VERSION ""

NS_ :

BS_:
BU_: IAP ODS _4WD BCM HUD DATC MDPS AAF_Tester AEMC SMK _4WD EPB CUBIS MTS TMU EVP CGW TPMS LPI DI_BOX SPAS EMS LCA TCU IBOX FATC AFLS FPCM SCC AHLS AVM ABS SNV OPI PGS SAS AAF Dummy LDWS_LKAS LVR ESC PSB CLU ECS ACU REA
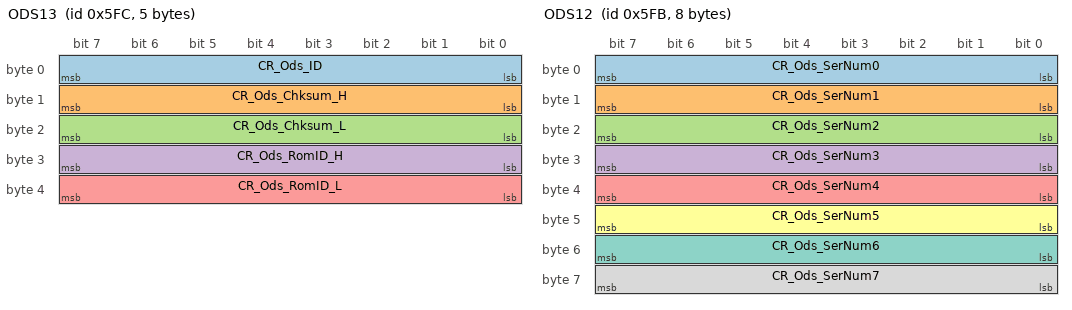
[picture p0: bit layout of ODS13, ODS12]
BO_ 1532 ODS13: 5 ODS
	SG_ CR_Ods_ID : 0|8@1+ (1.0,0.0) [0.0|255.0] ""  ACU
	SG_ CR_Ods_Chksum_H : 8|8@1+ (1.0,0.0) [0.0|255.0] ""  Dummy
	SG_ CR_Ods_Chksum_L : 16|8@1+ (1.0,0.0) [0.0|255.0] ""  Dummy
	SG_ CR_Ods_RomID_H : 24|8@1+ (1.0,0.0) [0.0|255.0] ""  Dummy
	SG_ CR_Ods_RomID_L : 32|8@1+ (1.0,0.0) [0.0|255.0] ""  Dummy

BO_ 1531 ODS12: 8 ODS
	SG_ CR_Ods_SerNum0 : 0|8@1+ (1.0,0.0) [0.0|255.0] ""  ACU
	SG_ CR_Ods_SerNum1 : 8|8@1+ (1.0,0.0) [0.0|255.0] ""  ACU
	SG_ CR_Ods_SerNum2 : 16|8@1+ (1.0,0.0) [0.0|255.0] ""  ACU
	SG_ CR_Ods_SerNum3 : 24|8@1+ (1.0,0.0) [0.0|255.0] ""  ACU
	SG_ CR_Ods_SerNum4 : 32|8@1+ (1.0,0.0) [0.0|255.0] ""  ACU
	SG_ CR_Ods_SerNum5 : 40|8@1+ (1.0,0.0) [0.0|255.0] ""  ACU
	SG_ CR_Ods_SerNum6 : 48|8@1+ (1.0,0.0) [0.0|255.0] ""  ACU
	SG_ CR_Ods_SerNum7 : 56|8@1+ (1.0,0.0) [0.0|255.0] ""  ACU

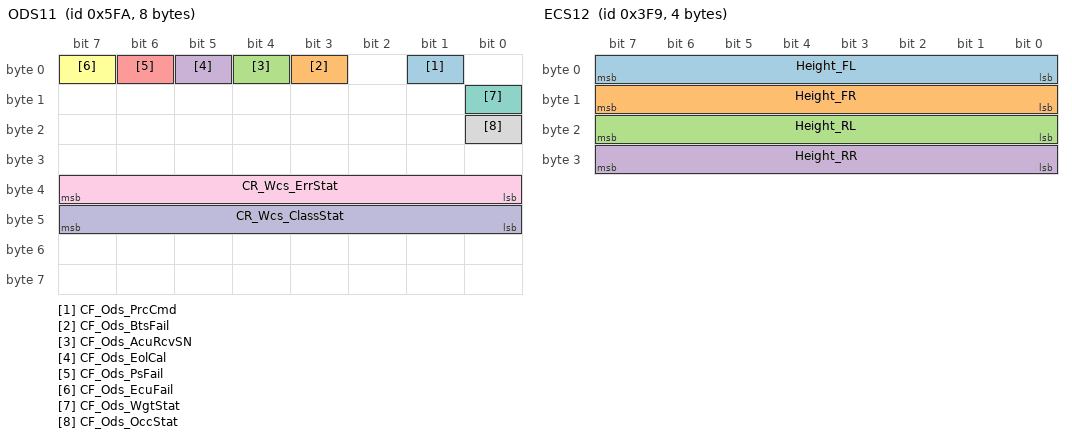
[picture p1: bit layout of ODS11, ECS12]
BO_ 1530 ODS11: 8 ODS
	SG_ CF_Ods_PrcCmd : 1|1@1+ (1.0,0.0) [0.0|1.0] ""  Dummy
	SG_ CF_Ods_BtsFail : 3|1@1+ (1.0,0.0) [0.0|1.0] ""  Dummy
	SG_ CF_Ods_AcuRcvSN : 4|1@1+ (1.0,0.0) [0.0|1.0] ""  ACU
	SG_ CF_Ods_EolCal : 5|1@1+ (1.0,0.0) [0.0|1.0] ""  ACU
	SG_ CF_Ods_PsFail : 6|1@1+ (1.0,0.0) [0.0|1.0] ""  ACU
	SG_ CF_Ods_EcuFail : 7|1@1+ (1.0,0.0) [0.0|1.0] ""  ACU
	SG_ CF_Ods_WgtStat : 8|1@1+ (1.0,0.0) [0.0|1.0] ""  ACU
	SG_ CF_Ods_OccStat : 16|1@1+ (1.0,0.0) [0.0|1.0] ""  ACU
	SG_ CR_Wcs_ErrStat : 32|8@1+ (1.0,0.0) [0.0|63.0] ""  ACU
	SG_ CR_Wcs_ClassStat : 40|8@1+ (1.0,0.0) [0.0|4.0] ""  ACU,BCM

BO_ 1017 ECS12: 4 ECS
	SG_ Height_FL : 0|8@1+ (1.0,-128.0) [-128.0|127.0] "mm"  AFLS
	SG_ Height_FR : 8|8@1+ (1.0,-128.0) [-128.0|127.0] "mm"  AFLS
	SG_ Height_RL : 16|8@1+ (1.0,-128.0) [-128.0|127.0] "mm"  AFLS
	SG_ Height_RR : 24|8@1+ (1.0,-128.0) [-128.0|127.0] "mm"  AFLS

BO_ 1268 SPAS12: 8 SPAS
	SG_ CF_Spas_HMI_Stat : 0|8@1+ (1.0,0.0) [0.0|255.0] ""  CLU
	SG_ CF_Spas_Disp : 8|2@1+ (1.0,0.0) [0.0|3.0] ""  CLU,EMS
	SG_ CF_Spas_FIL_Ind : 10|3@1+ (1.0,0.0) [0.0|7.0] ""  AVM,CLU
	SG_ CF_Spas_FIR_Ind : 13|3@1+ (1.0,0.0) [0.0|7.0] ""  AVM,CLU
	SG_ CF_Spas_FOL_Ind : 16|3@1+ (1.0,0.0) [0.0|7.0] ""  AVM,CLU
	SG_ CF_Spas_FOR_Ind : 19|3@1+ (1.0,0.0) [0.0|7.0] ""  AVM,CLU
	SG_ CF_Spas_VolDown : 22|2@1+ (1.0,0.0) [0.0|3.0] ""  CLU
	SG_ CF_Spas_RIL_Ind : 24|3@1+ (1.0,0.0) [0.0|7.0] ""  AVM,CLU
	SG_ CF_Spas_RIR_Ind : 27|3@1+ (1.0,0.0) [0.0|7.0] ""  AVM,CLU
	SG_ CF_Spas_FLS_Alarm : 30|2@1+ (1.0,0.0) [0.0|3.0] ""  CLU
	SG_ CF_Spas_ROL_Ind : 32|3@1+ (1.0,0.0) [0.0|7.0] ""  AVM,CLU
	SG_ CF_Spas_ROR_Ind : 35|3@1+ (1.0,0.0) [0.0|7.0] ""  AVM,CLU
	SG_ CF_Spas_FCS_Alarm : 38|2@1+ (1.0,0.0) [0.0|3.0] ""  CLU
	SG_ CF_Spas_FI_Ind : 40|3@1+ (1.0,0.0) [0.0|7.0] ""  AVM,CLU
	SG_ CF_Spas_RI_Ind : 43|3@1+ (1.0,0.0) [0.0|7.0] ""  AVM,CLU
	SG_ CF_Spas_FRS_Alarm : 46|2@1+ (1.0,0.0) [0.0|3.0] ""  CLU
	SG_ CF_Spas_FR_Alarm : 48|2@1+ (1.0,0.0) [0.0|3.0] ""  BCM,CLU
	SG_ CF_Spas_RR_Alarm : 50|2@1+ (1.0,0.0) [0.0|3.0] ""  BCM,CLU
	SG_ CF_Spas_BEEP_Alarm : 52|4@1+ (1.0,0.0) [0.0|15.0] ""  BCM,CLU
	SG_ CF_Spas_StatAlarm : 56|1@1+ (1.0,0.0) [0.0|1.0] ""  CLU
	SG_ CF_Spas_RLS_Alarm : 57|2@1+ (1.0,0.0) [0.0|3.0] ""  CLU
	SG_ CF_Spas_RCS_Alarm : 59|2@1+ (1.0,0.0) [0.0|3.0] ""  CLU
	SG_ CF_Spas_RRS_Alarm : 61|2@1+ (1.0,0.0) [0.0|3.0] ""  CLU

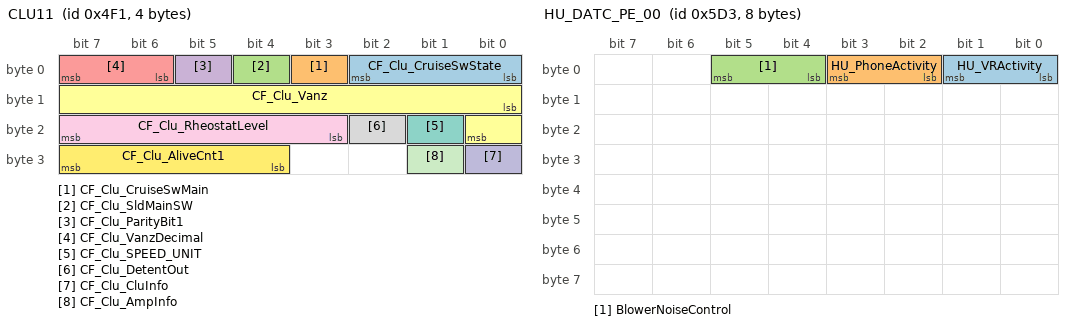
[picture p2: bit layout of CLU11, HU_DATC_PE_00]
BO_ 1265 CLU11: 4 CLU
	SG_ CF_Clu_CruiseSwState : 0|3@1+ (1.0,0.0) [0.0|7.0] ""  EMS,LDWS_LKAS,SCC
	SG_ CF_Clu_CruiseSwMain : 3|1@1+ (1.0,0.0) [0.0|1.0] ""  EMS,LDWS_LKAS,SCC
	SG_ CF_Clu_SldMainSW : 4|1@1+ (1.0,0.0) [0.0|1.0] ""  EMS
	SG_ CF_Clu_ParityBit1 : 5|1@1+ (1.0,0.0) [0.0|1.0] "pulse count"  EMS
	SG_ CF_Clu_VanzDecimal : 6|2@1+ (0.125,0.0) [0.0|0.375] ""  EMS
	SG_ CF_Clu_Vanz : 8|9@1+ (0.5,0.0) [0.0|255.5] "km/h or MPH"  BCM,CUBIS,EMS,IBOX,LDWS_LKAS,MDPS,SCC
	SG_ CF_Clu_SPEED_UNIT : 17|1@1+ (1.0,0.0) [0.0|1.0] ""  BCM,CUBIS,EMS,IBOX,LDWS_LKAS,MDPS,SCC
	SG_ CF_Clu_DetentOut : 18|1@1+ (1.0,0.0) [0.0|1.0] ""  AVM,BCM,LCA,PGS,SPAS
	SG_ CF_Clu_RheostatLevel : 19|5@1+ (1.0,0.0) [0.0|31.0] ""  AVM,BCM,LCA,PGS,SPAS
	SG_ CF_Clu_CluInfo : 24|1@1+ (1.0,0.0) [0.0|1.0] ""  BCM
	SG_ CF_Clu_AmpInfo : 25|1@1+ (1.0,0.0) [0.0|1.0] ""  BCM
	SG_ CF_Clu_AliveCnt1 : 28|4@1+ (1.0,0.0) [0.0|15.0] ""  AHLS,EMS,EPB,LDWS_LKAS,MDPS,SCC

BO_ 1492 TMU_GW_PE_01: 8 CLU
	SG_ TMU_IVRActivity : 0|2@1+ (1.0,0.0) [0.0|3.0] ""  DATC
	SG_ TMU_PhoneActivity : 2|2@1+ (1.0,0.0) [0.0|3.0] ""  DATC

BO_ 1491 HU_DATC_PE_00: 8 CLU
	SG_ HU_VRActivity : 0|2@1+ (1.0,0.0) [0.0|3.0] ""  DATC
	SG_ HU_PhoneActivity : 2|2@1+ (1.0,0.0) [0.0|3.0] ""  DATC
	SG_ BlowerNoiseControl : 4|2@1+ (1.0,0.0) [0.0|3.0] ""  DATC

BO_ 1490 HU_DATC_E_02: 8 CLU
	SG_ HU_DATC_RearOnOffSet : 6|2@1+ (1.0,0.0) [0.0|3.0] ""  DATC
	SG_ HU_DATC_ADSOnOffSet : 8|2@1+ (1.0,0.0) [0.0|3.0] ""  DATC

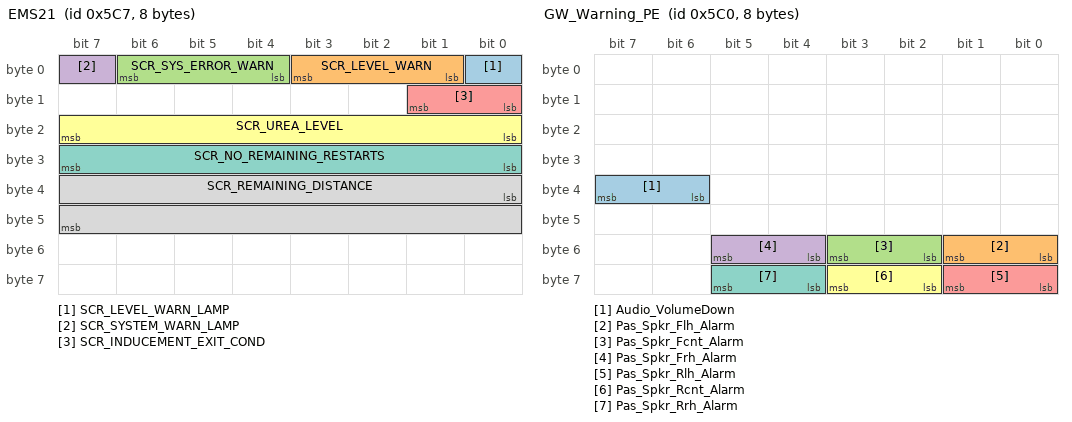
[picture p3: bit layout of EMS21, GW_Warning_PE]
BO_ 1479 EMS21: 8 EMS
	SG_ SCR_LEVEL_WARN_LAMP : 0|1@1+ (1.0,0.0) [0.0|1.0] ""  CLU
	SG_ SCR_LEVEL_WARN : 1|3@1+ (1.0,0.0) [0.0|4.0] ""  CLU
	SG_ SCR_SYS_ERROR_WARN : 4|3@1+ (1.0,0.0) [0.0|7.0] ""  CLU
	SG_ SCR_SYSTEM_WARN_LAMP : 7|1@1+ (1.0,0.0) [0.0|1.0] ""  CLU
	SG_ SCR_INDUCEMENT_EXIT_COND : 8|2@1+ (1.0,0.0) [0.0|3.0] ""  CLU
	SG_ SCR_UREA_LEVEL : 16|8@1+ (0.5,0.0) [0.0|100.0] "%"  CLU
	SG_ SCR_NO_REMAINING_RESTARTS : 24|8@1+ (1.0,0.0) [0.0|255.0] ""  CLU
	SG_ SCR_REMAINING_DISTANCE : 32|16@1+ (1.0,0.0) [0.0|25000.0] "km"  CLU

BO_ 1472 GW_Warning_PE: 8 BCM
	SG_ Audio_VolumeDown : 38|2@1+ (1.0,0.0) [0.0|3.0] ""  CLU
	SG_ Pas_Spkr_Flh_Alarm : 48|2@1+ (1.0,0.0) [0.0|3.0] ""  CLU
	SG_ Pas_Spkr_Fcnt_Alarm : 50|2@1+ (1.0,0.0) [0.0|3.0] ""  CLU
	SG_ Pas_Spkr_Frh_Alarm : 52|2@1+ (1.0,0.0) [0.0|3.0] ""  CLU
	SG_ Pas_Spkr_Rlh_Alarm : 56|2@1+ (1.0,0.0) [0.0|3.0] ""  CLU,PGS
	SG_ Pas_Spkr_Rcnt_Alarm : 58|2@1+ (1.0,0.0) [0.0|3.0] ""  CLU
	SG_ Pas_Spkr_Rrh_Alarm : 60|2@1+ (1.0,0.0) [0.0|3.0] ""  CLU,PGS

BO_ 1984 CAL_SAS11: 2 ESC
	SG_ CCW : 0|4@1+ (1.0,0.0) [0.0|15.0] ""  SAS
	SG_ SAS_CID : 4|11@1+ (1.0,0.0) [0.0|2047.0] ""  SAS

BO_ 1456 CLU12: 4 CLU
	SG_ CF_Clu_Odometer : 0|24@1+ (0.1,0.0) [0.0|1677721.4] "km"  _4WD,AAF,BCM,CUBIS,EMS,EPB,IBOX,LDWS_LKAS,SCC,TPMS

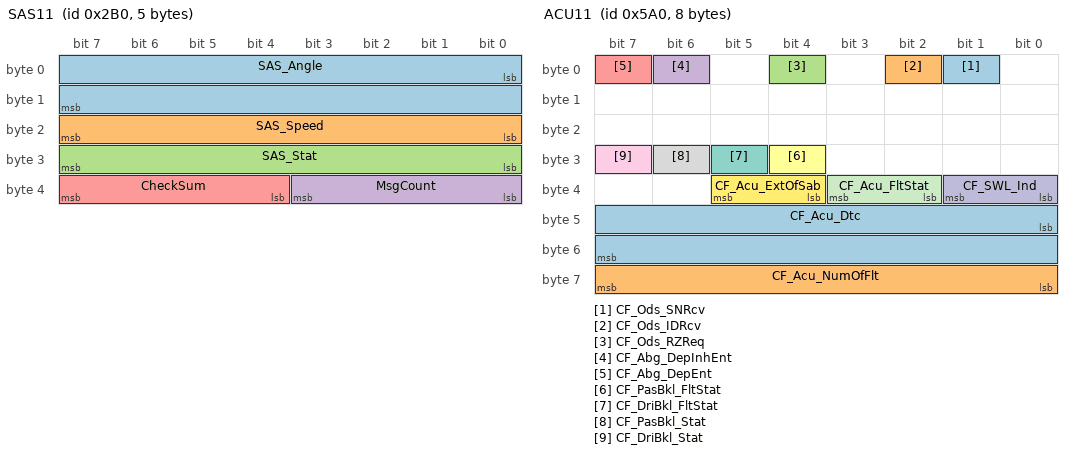
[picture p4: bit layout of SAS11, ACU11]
BO_ 688 SAS11: 5 MDPS
	SG_ SAS_Angle : 0|16@1+ (0.1,0.0) [-3276.8|3276.7] "Deg"  _4WD,ACU,AFLS,AVM,CLU,ECS,EMS,ESC,IBOX,LCA,LDWS_LKAS,PGS,PSB,SCC,SPAS,TCU,_4WD,ACU,AFLS,AVM,BCM,CLU,ECS,EMS,ESC,IBOX,LCA,LDWS_LKAS,PGS,PSB,SCC,SPAS,TCU
	SG_ SAS_Speed : 16|8@1+ (4.0,0.0) [0.0|1016.0] ""  AFLS,ECS,ESC,IBOX,LDWS_LKAS,SCC,SPAS,TCU,AFLS,ECS,ESC,IBOX,LDWS_LKAS,SCC,SPAS,TCU
	SG_ SAS_Stat : 24|8@1+ (1.0,0.0) [0.0|255.0] ""  ECS,ESC,IBOX,LDWS_LKAS,PSB,SCC,SPAS,TCU,ECS,ESC,IBOX,LDWS_LKAS,PSB,SCC,SPAS,TCU
	SG_ MsgCount : 32|4@1+ (1.0,0.0) [0.0|15.0] ""  ECS,ESC,IBOX,LDWS_LKAS,PSB,SCC,SPAS,ECS,ESC,IBOX,LDWS_LKAS,PSB,SCC,SPAS
	SG_ CheckSum : 36|4@1+ (1.0,0.0) [0.0|15.0] ""  ECS,EMS,ESC,IBOX,LDWS_LKAS,PSB,SCC,SPAS,ECS,EMS,ESC,IBOX,LDWS_LKAS,PSB,SCC,SPAS

BO_ 1441 ACU12: 8 ACU
	SG_ CR_Acu_SN : 0|64@1+ (1.0,0.0) [0.0|0.0] ""  ODS

BO_ 1440 ACU11: 8 ACU
	SG_ CF_Ods_SNRcv : 1|1@1+ (1.0,0.0) [0.0|1.0] ""  ODS
	SG_ CF_Ods_IDRcv : 2|1@1+ (1.0,0.0) [0.0|1.0] ""  ODS
	SG_ CF_Ods_RZReq : 4|1@1+ (1.0,0.0) [0.0|1.0] ""  ODS
	SG_ CF_Abg_DepInhEnt : 6|1@1+ (1.0,0.0) [0.0|1.0] ""  ODS
	SG_ CF_Abg_DepEnt : 7|1@1+ (1.0,0.0) [0.0|1.0] ""  ODS
	SG_ CF_PasBkl_FltStat : 28|1@1+ (1.0,0.0) [0.0|1.0] ""  ODS,PSB
	SG_ CF_DriBkl_FltStat : 29|1@1+ (1.0,0.0) [0.0|1.0] ""  ODS,PSB
	SG_ CF_PasBkl_Stat : 30|1@1+ (1.0,0.0) [0.0|1.0] ""  IBOX,ODS,PSB,TMU
	SG_ CF_DriBkl_Stat : 31|1@1+ (1.0,0.0) [0.0|1.0] ""  ODS,PSB
	SG_ CF_SWL_Ind : 32|2@1+ (1.0,0.0) [0.0|3.0] ""  CUBIS,IBOX
	SG_ CF_Acu_FltStat : 34|2@1+ (1.0,0.0) [0.0|3.0] ""  CUBIS,IBOX
	SG_ CF_Acu_ExtOfSab : 36|2@1+ (1.0,0.0) [0.0|3.0] ""  BCM,CLU,CUBIS,IBOX
	SG_ CF_Acu_Dtc : 40|16@1+ (1.0,0.0) [0.0|65535.0] ""  CUBIS,IBOX
	SG_ CF_Acu_NumOfFlt : 56|8@1+ (1.0,0.0) [0.0|255.0] ""  CUBIS,IBOX

BO_ 1437 AHLS11: 8 AHLS
	SG_ CF_Ahls_WarnLamp : 0|2@1+ (1.0,0.0) [0.0|3.0] ""  CLU
	SG_ CF_Ahls_WarnMsg : 2|2@1+ (1.0,0.0) [0.0|3.0] ""  CLU

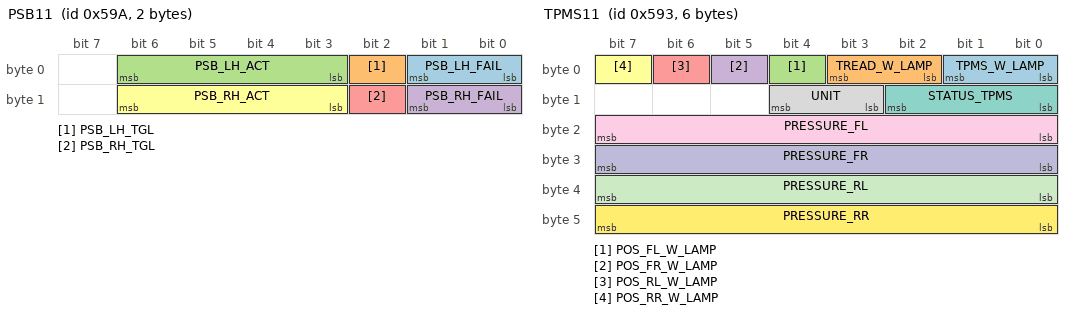
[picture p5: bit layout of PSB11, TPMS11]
BO_ 1434 PSB11: 2 PSB
	SG_ PSB_LH_FAIL : 0|2@1+ (1.0,0.0) [0.0|3.0] ""  CLU
	SG_ PSB_LH_TGL : 2|1@1+ (1.0,0.0) [0.0|1.0] ""  CLU
	SG_ PSB_LH_ACT : 3|4@1+ (1.0,0.0) [0.0|4.0] ""  Dummy
	SG_ PSB_RH_FAIL : 8|2@1+ (1.0,0.0) [0.0|3.0] ""  CLU
	SG_ PSB_RH_TGL : 10|1@1+ (1.0,0.0) [0.0|1.0] ""  CLU
	SG_ PSB_RH_ACT : 11|4@1+ (1.0,0.0) [0.0|4.0] ""  Dummy

BO_ 916 TCS13: 8 ESC
	SG_ aBasis : 0|11@1+ (0.01,-10.23) [-10.23|10.24] "m/s^2"  EMS,SCC
	SG_ BrakeLight : 11|1@1+ (1.0,0.0) [0.0|1.0] ""  CLU,EMS,SCC
	SG_ DCEnable : 12|1@1+ (1.0,0.0) [0.0|1.0] ""  EMS,SCC
	SG_ AliveCounterTCS : 13|3@1+ (1.0,0.0) [0.0|7.0] ""  EMS,SCC
	SG_ ACCReqLim : 22|2@1+ (1.0,0.0) [0.0|3.0] ""  EMS,SCC
	SG_ TQI_ACC : 24|8@1+ (0.390625,0.0) [0.0|99.609375] "%"  EMS
	SG_ ACCEL_REF_ACC : 32|11@1+ (0.01,-10.23) [-10.23|10.24] "m/s^2"  EMS,SCC
	SG_ ACCEnable : 43|2@1+ (1.0,0.0) [0.0|3.0] ""  EMS,SCC
	SG_ DriverOverride : 45|2@1+ (1.0,0.0) [0.0|3.0] ""  EMS,SCC
	SG_ StandStill : 47|1@1+ (1.0,0.0) [0.0|1.0] ""  EMS,SCC
	SG_ CheckSum_TCS3 : 48|4@1+ (1.0,0.0) [0.0|15.0] ""  EMS,SCC
	SG_ ACC_EQUIP : 52|1@1+ (1.0,0.0) [0.0|1.0] ""  EMS,SCC
	SG_ PBRAKE_ACT : 53|1@1+ (1.0,0.0) [0.0|1.0] ""  EMS,SCC
	SG_ ACC_REQ : 54|1@1+ (1.0,0.0) [0.0|1.0] ""  EMS
	SG_ DriverBraking : 55|1@1+ (1.0,0.0) [0.0|1.0] ""  EMS,SCC
	SG_ CF_VSM_Coded : 56|1@1+ (1.0,0.0) [0.0|1.0] ""  SCC
	SG_ CF_VSM_Avail : 57|2@1+ (1.0,0.0) [0.0|3.0] ""  CLU,SCC
	SG_ CF_VSM_Handshake : 59|1@1+ (1.0,0.0) [0.0|1.0] ""  SCC
	SG_ CF_DriBkeStat : 60|1@1+ (1.0,0.0) [0.0|1.0] ""  SCC
	SG_ CF_VSM_ConfSwi : 61|2@1+ (1.0,0.0) [0.0|3.0] ""  SCC
	SG_ AEB_EQUIP : 63|1@1+ (1.0,0.0) [0.0|1.0] ""  SCC

BO_ 1427 TPMS11: 6 BCM
	SG_ TPMS_W_LAMP : 0|2@1+ (1.0,0.0) [0.0|3.0] ""  CLU,CUBIS,HUD,IBOX,CLU,CUBIS,HUD,IBOX
	SG_ TREAD_W_LAMP : 2|2@1+ (1.0,0.0) [0.0|3.0] ""  CLU,CUBIS,HUD,IBOX,CLU,CUBIS,HUD,IBOX
	SG_ POS_FL_W_LAMP : 4|1@1+ (1.0,0.0) [0.0|1.0] ""  CLU,CUBIS,HUD,IBOX
	SG_ POS_FR_W_LAMP : 5|1@1+ (1.0,0.0) [0.0|1.0] ""  CLU,CUBIS,HUD,IBOX
	SG_ POS_RL_W_LAMP : 6|1@1+ (1.0,0.0) [0.0|1.0] ""  CLU,CUBIS,HUD,IBOX
	SG_ POS_RR_W_LAMP : 7|1@1+ (1.0,0.0) [0.0|1.0] ""  CLU,CUBIS,HUD,IBOX
	SG_ STATUS_TPMS : 8|3@1+ (1.0,0.0) [0.0|0.0] ""  CLU
	SG_ UNIT : 11|2@1+ (1.0,0.0) [0.0|3.0] ""  CLU
	SG_ PRESSURE_FL : 16|8@1+ (1.0,0.0) [0.0|255.0] ""  CLU
	SG_ PRESSURE_FR : 24|8@1+ (1.0,0.0) [0.0|255.0] ""  CLU
	SG_ PRESSURE_RL : 32|8@1+ (1.0,0.0) [0.0|255.0] ""  CLU
	SG_ PRESSURE_RR : 40|8@1+ (1.0,0.0) [0.0|255.0] ""  CLU

BO_ 915 TCS12: 4 ESC
	SG_ SA_COUNT : 0|16@1+ (2.0,-32768.0) [-32768.0|98302.0] "¢ª"  _4WD,ACU,MDPS
	SG_ SA_Z_COUNT : 16|15@1+ (2.0,-32768.0) [-32768.0|32766.0] "¢ª"  _4WD,ACU,MDPS
	SG_ SA_Z_FLAG : 31|1@1+ (1.0,0.0) [0.0|1.0] ""  _4WD,ACU,MDPS

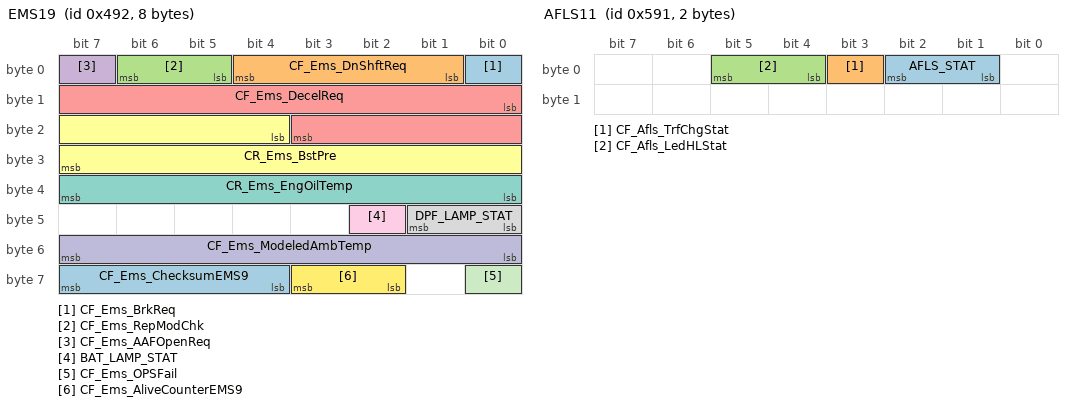
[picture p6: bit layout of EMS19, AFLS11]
BO_ 1170 EMS19: 8 EMS
	SG_ CF_Ems_BrkReq : 0|1@1+ (1.0,0.0) [0.0|1.0] ""  ESC,IBOX,TCU
	SG_ CF_Ems_DnShftReq : 1|4@1+ (1.0,0.0) [0.0|14.0] ""  IBOX,TCU
	SG_ CF_Ems_RepModChk : 5|2@1+ (1.0,0.0) [0.0|3.0] ""  IBOX
	SG_ CF_Ems_AAFOpenReq : 7|1@1+ (1.0,0.0) [0.0|1.0] ""  AAF,IBOX
	SG_ CF_Ems_DecelReq : 8|12@1+ (0.0010,-4.094) [-4.094|0.0] "m/s^2"  ESC,IBOX,TCU
	SG_ CR_Ems_BstPre : 20|12@1+ (1.322,0.0) [0.0|4094.0] "hPa"  CLU,IBOX
	SG_ CR_Ems_EngOilTemp : 32|8@1+ (0.75,-40.0) [0.0|254.0] "¡É"  CLU,IBOX
	SG_ DPF_LAMP_STAT : 40|2@1+ (1.0,0.0) [0.0|3.0] ""  CLU,IBOX
	SG_ BAT_LAMP_STAT : 42|1@1+ (1.0,0.0) [0.0|1.0] ""  CLU,IBOX
	SG_ CF_Ems_ModeledAmbTemp : 48|8@1+ (0.5,-41.0) [-41.0|85.5] "¡É"  AAF,IBOX
	SG_ CF_Ems_OPSFail : 56|1@1+ (1.0,0.0) [0.0|1.0] ""  CLU,IBOX
	SG_ CF_Ems_AliveCounterEMS9 : 58|2@1+ (1.0,0.0) [0.0|3.0] ""  AAF,ABS,CUBIS,ECS,EPB,IBOX,MDPS,REA,SCC,SMK,TCU
	SG_ CF_Ems_ChecksumEMS9 : 60|4@1+ (1.0,0.0) [0.0|15.0] ""  AAF,ABS,CUBIS,ECS,EPB,IBOX,MDPS,REA,SCC,SMK,TCU

BO_ 1425 AFLS11: 2 AFLS
	SG_ AFLS_STAT : 1|2@1+ (1.0,0.0) [0.0|3.0] ""  CLU
	SG_ CF_Afls_TrfChgStat : 3|1@1+ (1.0,0.0) [0.0|1.0] ""  CLU
	SG_ CF_Afls_LedHLStat : 4|2@1+ (1.0,0.0) [0.0|3.0] ""  CLU

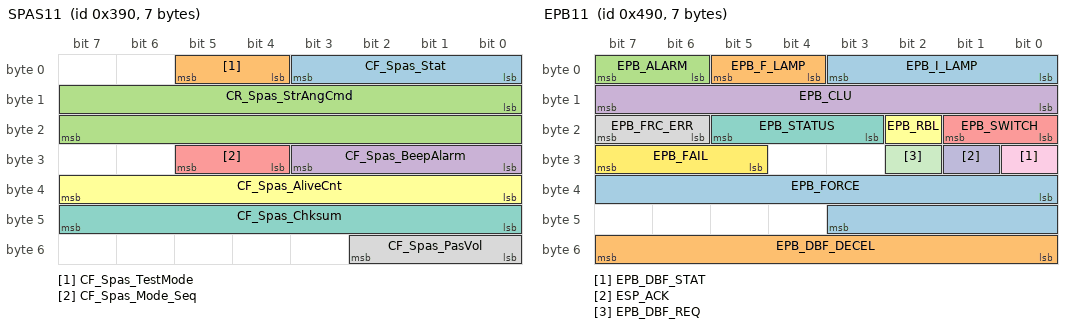
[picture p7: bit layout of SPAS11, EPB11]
BO_ 912 SPAS11: 7 SPAS
	SG_ CF_Spas_Stat : 0|4@1+ (1.0,0.0) [0.0|15.0] ""  ESC,MDPS
	SG_ CF_Spas_TestMode : 4|2@1+ (1.0,0.0) [0.0|3.0] ""  MDPS
	SG_ CR_Spas_StrAngCmd : 8|16@1- (0.1,0.0) [-3276.8|3276.7] ""  MDPS
	SG_ CF_Spas_BeepAlarm : 24|4@1+ (1.0,0.0) [0.0|15.0] ""  CLU
	SG_ CF_Spas_Mode_Seq : 28|2@1+ (1.0,0.0) [0.0|3.0] ""  CLU
	SG_ CF_Spas_AliveCnt : 32|8@1+ (1.0,0.0) [0.0|255.0] ""  MDPS
	SG_ CF_Spas_Chksum : 40|8@1+ (1.0,0.0) [0.0|255.0] ""  MDPS
	SG_ CF_Spas_PasVol : 48|3@1+ (1.0,0.0) [0.0|7.0] ""  CGW,CLU

BO_ 1168 EPB11: 7 EPB
	SG_ EPB_I_LAMP : 0|4@1+ (1.0,0.0) [0.0|15.0] ""  BCM,CLU,CUBIS,ESC,IBOX
	SG_ EPB_F_LAMP : 4|2@1+ (1.0,0.0) [0.0|3.0] ""  CLU,CUBIS,ESC,IBOX
	SG_ EPB_ALARM : 6|2@1+ (1.0,0.0) [0.0|3.0] ""  CLU,ESC
	SG_ EPB_CLU : 8|8@1+ (1.0,0.0) [0.0|255.0] ""  CLU,ESC
	SG_ EPB_SWITCH : 16|2@1+ (1.0,0.0) [0.0|3.0] ""  ESC,SCC
	SG_ EPB_RBL : 18|1@1+ (1.0,0.0) [0.0|1.0] ""  EMS,ESC
	SG_ EPB_STATUS : 19|3@1+ (1.0,0.0) [0.0|7.0] ""  CLU,EMS,ESC,SCC,TCU
	SG_ EPB_FRC_ERR : 22|2@1+ (1.0,0.0) [0.0|3.0] ""  EMS,ESC,SCC,TCU
	SG_ EPB_DBF_STAT : 24|1@1+ (1.0,0.0) [0.0|1.0] ""  ESC
	SG_ ESP_ACK : 25|1@1+ (1.0,0.0) [0.0|1.0] ""  ESC
	SG_ EPB_DBF_REQ : 26|1@1+ (1.0,0.0) [0.0|1.0] ""  ESC
	SG_ EPB_FAIL : 29|3@1+ (1.0,0.0) [0.0|7.0] ""  ESC,SCC
	SG_ EPB_FORCE : 32|12@1+ (1.0,-1000.0) [-1000.0|3000.0] ""  ESC
	SG_ EPB_DBF_DECEL : 48|8@1+ (0.01,0.0) [0.0|2.54] "g"  ESC

BO_ 399 EMS_H12: 8 EMS
	SG_ R_TqAcnApvC : 0|8@1+ (0.2,0.0) [0.0|51.0] "Nm"  DATC,IBOX
	SG_ R_PAcnC : 8|8@1+ (125.0,0.0) [0.0|31875.0] "hPa"  DATC,IBOX
	SG_ TQI_B : 16|8@1+ (0.390625,0.0) [0.0|99.609375] "%"  ABS,ESC,IBOX
	SG_ SLD_VS : 24|8@1+ (1.0,0.0) [0.0|255.0] "km/h"  CLU,IBOX
	SG_ CF_CdaStat : 32|3@1+ (1.0,0.0) [0.0|7.0] ""  AEMC,IBOX,TCU
	SG_ CF_Ems_IsgStat : 35|3@1+ (1.0,0.0) [0.0|7.0] ""  ABS,BCM,CLU,DATC,EPB,ESC,IBOX,LDWS_LKAS,MDPS,SMK,TCU
	SG_ CF_Ems_OilChg : 38|1@1+ (1.0,0.0) [0.0|1.0] ""  CLU,IBOX
	SG_ CF_Ems_EtcLimpMod : 39|1@1+ (1.0,0.0) [0.0|1.0] ""  CLU,IBOX
	SG_ R_NEngIdlTgC : 40|8@1+ (10.0,0.0) [0.0|2550.0] "rpm"  DATC,IBOX,TCU
	SG_ CF_Ems_UpTarGr : 48|1@1+ (1.0,0.0) [0.0|1.0] ""  CLU,IBOX
	SG_ CF_Ems_DownTarGr : 49|1@1+ (1.0,0.0) [0.0|1.0] ""  CLU,IBOX
	SG_ CF_Ems_DesCurGr : 50|4@1+ (1.0,0.0) [0.0|15.0] ""  CLU,IBOX
	SG_ CF_Ems_SldAct : 54|1@1+ (1.0,0.0) [0.0|1.0] ""  CLU,IBOX
	SG_ CF_Ems_SldPosAct : 55|1@1+ (1.0,0.0) [0.0|1.0] ""  CLU,IBOX
	SG_ CF_Ems_HPresStat : 56|1@1+ (1.0,0.0) [0.0|1.0] ""  IBOX,TCU
	SG_ CF_Ems_IsgBuz : 57|1@1+ (1.0,0.0) [0.0|1.0] ""  CLU,IBOX
	SG_ CF_Ems_IdlStpFCO : 58|1@1+ (1.0,0.0) [0.0|1.0] ""  CLU,IBOX
	SG_ CF_Ems_FCopen : 59|1@1+ (1.0,0.0) [0.0|1.0] ""  CLU,IBOX
	SG_ CF_Ems_ActEcoAct : 60|1@1+ (1.0,0.0) [0.0|1.0] ""  CLU,IBOX,TCU
	SG_ CF_Ems_EngRunNorm : 61|1@1+ (1.0,0.0) [0.0|1.0] ""  ABS,ESC,IBOX,TCU
	SG_ CF_Ems_IsgStat2 : 62|2@1+ (2.0,0.0) [0.0|3.0] ""  CLU,IBOX,TCU

BO_ 1419 LCA11: 8 LCA
	SG_ CF_Lca_Stat : 0|4@1+ (1.0,0.0) [0.0|15.0] ""  BCM,CLU
	SG_ CF_Rcta_Stat : 4|4@1+ (1.0,0.0) [0.0|15.0] ""  BCM,CLU
	SG_ CF_Lca_IndLeft : 8|2@1+ (1.0,0.0) [0.0|3.0] ""  BCM,CLU
	SG_ CF_Rcw_Stat : 10|4@1+ (1.0,0.0) [0.0|15.0] ""  BCM,CLU
	SG_ CF_RCW_Warning : 14|2@1+ (1.0,0.0) [0.0|3.0] ""  BCM,CLU
	SG_ CF_Lca_IndRight : 16|2@1+ (1.0,0.0) [0.0|3.0] ""  BCM,CLU
	SG_ CF_Lca_SndWan_Stat : 18|2@1+ (1.0,0.0) [0.0|3.0] ""  BCM,CLU
	SG_ CF_FR_SndWan : 20|1@1+ (1.0,0.0) [0.0|1.0] ""  BCM,CLU
	SG_ CF_FL_SndWan : 21|1@1+ (1.0,0.0) [0.0|1.0] ""  BCM,CLU
	SG_ CF_RR_SndWan : 22|1@1+ (1.0,0.0) [0.0|1.0] ""  BCM,CLU
	SG_ CF_RL_SndWan : 23|1@1+ (1.0,0.0) [0.0|1.0] ""  BCM,CLU
	SG_ CF_Lca_IndBriLeft : 24|8@1+ (1.0,0.0) [0.0|255.0] ""  BCM,CLU
	SG_ CF_Lca_IndBriRight : 32|8@1+ (1.0,0.0) [0.0|255.0] ""  BCM,CLU
	SG_ CF_RCTA_IndBriLeft : 40|8@1+ (1.0,0.0) [0.0|255.0] ""  BCM,CLU
	SG_ CF_RCTA_IndBriRight : 48|8@1+ (1.0,0.0) [0.0|255.0] ""  BCM,CLU
	SG_ CF_RCTA_IndLeft : 56|2@1+ (1.0,0.0) [0.0|3.0] ""  BCM,CLU
	SG_ CF_RCTA_IndRight : 58|2@1+ (1.0,0.0) [0.0|3.0] ""  BCM,CLU
	SG_ CF_SndWarnForClu : 60|1@1+ (1.0,0.0) [0.0|1.0] ""  CLU

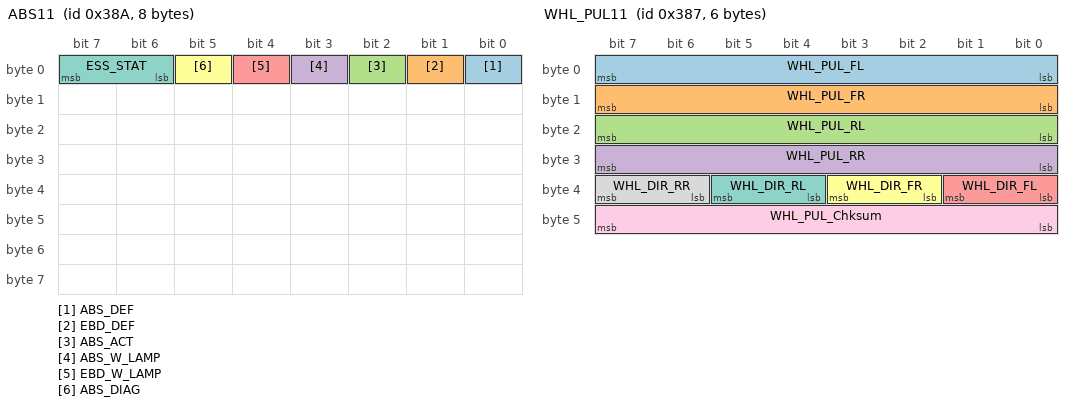
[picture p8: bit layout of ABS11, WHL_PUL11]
BO_ 906 ABS11: 8 ABS
	SG_ ABS_DEF : 0|1@1+ (1.0,0.0) [0.0|1.0] ""  _4WD,ACU,EMS,SPAS,TCU
	SG_ EBD_DEF : 1|1@1+ (1.0,0.0) [0.0|1.0] ""  _4WD,EMS,SPAS,TCU
	SG_ ABS_ACT : 2|1@1+ (1.0,0.0) [0.0|1.0] ""  _4WD,ACU,EPB,SPAS,TCU
	SG_ ABS_W_LAMP : 3|1@1+ (1.0,0.0) [0.0|1.0] ""  _4WD,CLU,CUBIS,MTS,TMU
	SG_ EBD_W_LAMP : 4|1@1+ (1.0,0.0) [0.0|1.0] ""  _4WD,CLU
	SG_ ABS_DIAG : 5|1@1+ (1.0,0.0) [0.0|1.0] ""  _4WD,CLU
	SG_ ESS_STAT : 6|2@1+ (1.0,0.0) [0.0|3.0] ""  _4WD,BCM,CLU,EMS

BO_ 903 WHL_PUL11: 6 ABS
	SG_ WHL_PUL_FL : 0|8@1+ (0.5,0.0) [0.0|127.5] "pulse count"  CUBIS,EPB,IBOX,SPAS,TMU,TPMS,CUBIS,EPB,IBOX,LDWS_LKAS,SPAS,TMU,TPMS
	SG_ WHL_PUL_FR : 8|8@1+ (0.5,0.0) [0.0|127.5] "pulse count"  CUBIS,EPB,IBOX,SPAS,TMU,TPMS,CUBIS,EPB,IBOX,LDWS_LKAS,SPAS,TMU,TPMS
	SG_ WHL_PUL_RL : 16|8@1+ (0.5,0.0) [0.0|127.5] "pulse count"  CUBIS,EPB,IBOX,SPAS,TMU,TPMS,CUBIS,EPB,IBOX,LDWS_LKAS,SPAS,TMU,TPMS
	SG_ WHL_PUL_RR : 24|8@1+ (0.5,0.0) [0.0|127.5] "pulse count"  CUBIS,EPB,IBOX,SPAS,TMU,TPMS,CUBIS,EPB,IBOX,LDWS_LKAS,SPAS,TMU,TPMS
	SG_ WHL_DIR_FL : 32|2@1+ (1.0,0.0) [0.0|3.0] ""  EPB,SPAS,TPMS,EPB,LCA,SPAS,TPMS
	SG_ WHL_DIR_FR : 34|2@1+ (1.0,0.0) [0.0|3.0] ""  EPB,SPAS,TPMS,EPB,LCA,SPAS,TPMS
	SG_ WHL_DIR_RL : 36|2@1+ (1.0,0.0) [0.0|3.0] ""  EPB,SPAS,TPMS,EPB,LCA,SPAS,TPMS
	SG_ WHL_DIR_RR : 38|2@1+ (1.0,0.0) [0.0|3.0] ""  EPB,SPAS,TPMS,EPB,LCA,SPAS,TPMS
	SG_ WHL_PUL_Chksum : 40|8@1+ (1.0,0.0) [0.0|255.0] ""  EPB,SPAS,TPMS,EPB,LCA,LDWS_LKAS,SPAS,TPMS

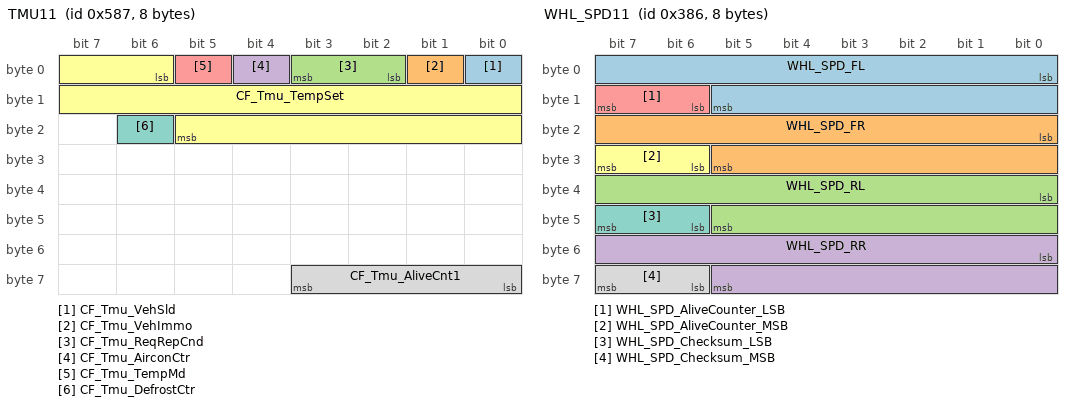
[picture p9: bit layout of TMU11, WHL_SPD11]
BO_ 1415 TMU11: 8 IBOX
	SG_ CF_Tmu_VehSld : 0|1@1+ (1.0,0.0) [0.0|1.0] ""  EMS
	SG_ CF_Tmu_VehImmo : 1|1@1+ (1.0,0.0) [0.0|1.0] ""  EMS
	SG_ CF_Tmu_ReqRepCnd : 2|2@1+ (1.0,0.0) [0.0|3.0] ""  EMS
	SG_ CF_Tmu_AirconCtr : 4|1@1+ (1.0,0.0) [0.0|1.0] ""  DATC
	SG_ CF_Tmu_TempMd : 5|1@1+ (1.0,0.0) [0.0|1.0] ""  DATC
	SG_ CF_Tmu_TempSet : 6|16@1+ (1.0,0.0) [0.0|20.0] ""  DATC
	SG_ CF_Tmu_DefrostCtr : 22|1@1+ (1.0,0.0) [0.0|1.0] ""  DATC,FATC
	SG_ CF_Tmu_AliveCnt1 : 56|4@1+ (1.0,0.0) [0.0|15.0] ""  EMS

BO_ 902 WHL_SPD11: 8 ABS
	SG_ WHL_SPD_FL : 0|14@1+ (0.03125,0.0) [0.0|511.96875] "km/h"  _4WD,AFLS,AHLS,AVM,CLU,CUBIS,ECS,EMS,EPB,IBOX,LDWS_LKAS,PGS,PSB,SCC,SMK,SPAS,TCU,TPMS,_4WD,ACU,AFLS,AHLS,AVM,CLU,ECS,EMS,EPB,IBOX,LCA,LDWS_LKAS,PGS,PSB,SCC,SMK,SPAS,TCU,TPMS
	SG_ WHL_SPD_FR : 16|14@1+ (0.03125,0.0) [0.0|511.96875] "km/h"  _4WD,ACU,AFLS,AHLS,AVM,CLU,CUBIS,ECS,EMS,EPB,IBOX,LDWS_LKAS,PGS,PSB,SCC,SMK,SPAS,TCU,TPMS,_4WD,ACU,AFLS,AHLS,AVM,CLU,ECS,EMS,EPB,IBOX,LCA,LDWS_LKAS,PGS,PSB,SCC,SMK,SPAS,TCU,TPMS
	SG_ WHL_SPD_RL : 32|14@1+ (0.03125,0.0) [0.0|511.96875] "km/h"  _4WD,AFLS,AHLS,AVM,BCM,CLU,CUBIS,ECS,EMS,EPB,IBOX,LDWS_LKAS,PGS,PSB,SCC,SMK,SPAS,TCU,TPMS,_4WD,ACU,AFLS,AHLS,AVM,BCM,CLU,ECS,EMS,EPB,IBOX,LCA,LDWS_LKAS,PGS,PSB,SCC,SMK,SPAS,TCU,TPMS
	SG_ WHL_SPD_RR : 48|14@1+ (0.03125,0.0) [0.0|511.96875] "km/h"  _4WD,AFLS,AHLS,AVM,CLU,CUBIS,ECS,EMS,EPB,IBOX,LDWS_LKAS,PGS,PSB,SCC,SMK,SPAS,TCU,TPMS,_4WD,ACU,AFLS,AHLS,AVM,CLU,ECS,EMS,EPB,IBOX,LCA,LDWS_LKAS,PGS,PSB,SCC,SMK,SPAS,TCU,TPMS
	SG_ WHL_SPD_AliveCounter_LSB : 14|2@1+ (1.0,0.0) [0.0|15.0] ""  _4WD,EMS,LPI,TCU,TMU
	SG_ WHL_SPD_AliveCounter_MSB : 30|2@1+ (1.0,0.0) [0.0|15.0] ""  _4WD,EMS,LPI,TCU,TMU
	SG_ WHL_SPD_Checksum_LSB : 46|2@1+ (1.0,0.0) [0.0|15.0] ""  _4WD,EMS,LPI,TCU,TMU
	SG_ WHL_SPD_Checksum_MSB : 62|2@1+ (1.0,0.0) [0.0|15.0] ""  _4WD,EMS,LPI,TCU,TMU

BO_ 1414 EVP11: 3 EVP
	SG_ CF_Evp_Stat : 0|1@1+ (1.0,0.0) [0.0|1.0] ""  CLU

BO_ 1412 AAF11: 8 AAF
	SG_ CF_Aaf_ActFlapStatus : 0|2@1+ (1.0,0.0) [0.0|3.0] ""  AAF_Tester
	SG_ CF_Aaf_ModeStatus : 2|3@1+ (1.0,0.0) [0.0|7.0] ""  AAF_Tester
	SG_ CF_Aaf_WrnLamp : 5|1@1+ (1.0,0.0) [0.0|1.0] ""  CLU
	SG_ CF_Aaf_ErrStatus : 6|10@1+ (1.0,0.0) [0.0|1023.0] ""  AAF_Tester,EMS
	SG_ CF_Aaf_OpenRqSysAct : 16|8@1+ (1.0,0.0) [0.0|255.0] ""  AAF_Tester
	SG_ CF_Aaf_PStatus : 24|8@1+ (1.0,0.0) [0.0|100.0] "%"  AAF_Tester
	SG_ CF_Aaf_OpenRqSysSol : 32|8@1+ (1.0,0.0) [0.0|255.0] ""  AAF_Tester
	SG_ CF_Aaf_SolFlapStatus : 40|2@1+ (1.0,0.0) [0.0|3.0] ""  AAF_Tester
	SG_ CF_Aaf_MilOnReq : 42|1@1+ (1.0,0.0) [0.0|1.0] ""  EMS

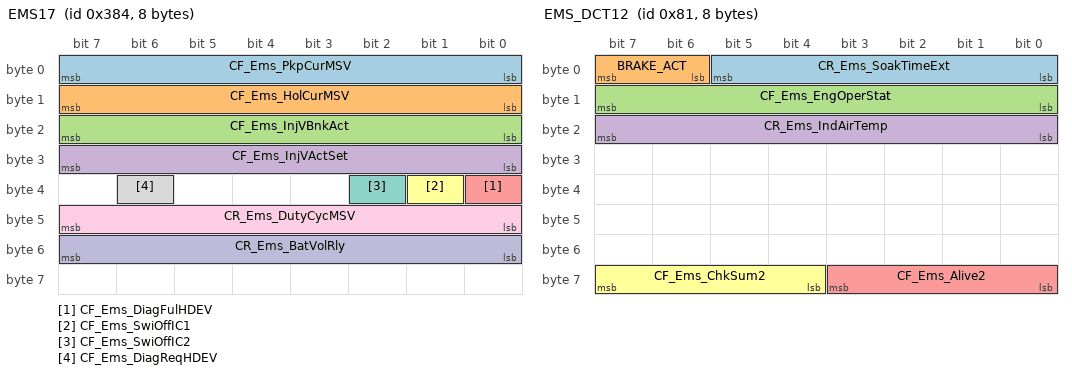
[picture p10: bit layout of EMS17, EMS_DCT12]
BO_ 900 EMS17: 8 EMS
	SG_ CF_Ems_PkpCurMSV : 0|8@1+ (1.0,0.0) [0.0|255.0] ""  DI_BOX
	SG_ CF_Ems_HolCurMSV : 8|8@1+ (1.0,0.0) [0.0|255.0] ""  DI_BOX
	SG_ CF_Ems_InjVBnkAct : 16|8@1+ (1.0,0.0) [0.0|255.0] ""  DI_BOX
	SG_ CF_Ems_InjVActSet : 24|8@1+ (1.0,0.0) [0.0|255.0] ""  DI_BOX
	SG_ CF_Ems_DiagFulHDEV : 32|1@1+ (1.0,0.0) [0.0|1.0] ""  DI_BOX
	SG_ CF_Ems_SwiOffIC1 : 33|1@1+ (1.0,0.0) [0.0|1.0] ""  DI_BOX
	SG_ CF_Ems_SwiOffIC2 : 34|1@1+ (1.0,0.0) [0.0|1.0] ""  DI_BOX
	SG_ CF_Ems_DiagReqHDEV : 38|1@1+ (1.0,0.0) [0.0|1.0] ""  DI_BOX
	SG_ CR_Ems_DutyCycMSV : 40|8@1+ (0.3921568627,0.0) [0.0|100.0] "%"  DI_BOX
	SG_ CR_Ems_BatVolRly : 48|8@1+ (0.1,0.0) [0.0|25.5] "V"  DI_BOX

BO_ 387 REA11: 8 REA
	SG_ CF_EndBst_PwmDuH : 0|1@1+ (1.0,0.0) [0.0|1.0] ""  EMS
	SG_ CF_EndBst_PwmDuL : 1|1@1+ (1.0,0.0) [0.0|1.0] ""  EMS
	SG_ CF_EndBst_PwmFqOutRng : 2|1@1+ (1.0,0.0) [0.0|1.0] ""  EMS
	SG_ CF_EndBst_HbriOverCur : 3|1@1+ (1.0,0.0) [0.0|1.0] ""  EMS
	SG_ CF_EndBst_HbriOverTemp : 4|1@1+ (1.0,0.0) [0.0|1.0] ""  EMS
	SG_ CF_EndBst_PosSnsKOR : 6|1@1+ (1.0,0.0) [0.0|1.0] ""  EMS
	SG_ CF_EndBst_PosSnsOSOR : 7|1@1+ (1.0,0.0) [0.0|1.0] ""  EMS
	SG_ CF_EndBst_EepFlt : 8|1@1+ (1.0,0.0) [0.0|1.0] ""  EMS
	SG_ CF_EndBst_RomFlt : 9|1@1+ (1.0,0.0) [0.0|1.0] ""  EMS
	SG_ CF_EndBst_RamFlt : 10|1@1+ (1.0,0.0) [0.0|1.0] ""  EMS
	SG_ CF_EndBst_CanFlt : 11|1@1+ (1.0,0.0) [0.0|1.0] ""  EMS
	SG_ CF_EndBst_AgH : 12|1@1+ (1.0,0.0) [0.0|1.0] ""  EMS
	SG_ CF_EndBst_AgL : 13|1@1+ (1.0,0.0) [0.0|1.0] ""  EMS
	SG_ CF_EndBst_ORVol : 14|1@1+ (1.0,0.0) [0.0|1.0] ""  EMS
	SG_ CR_EndBst_ActPos : 16|16@1+ (0.117,0.0) [1.989|118.053] "¢ª"  EMS
	SG_ CR_EndBst_DemPos : 32|16@1+ (0.117,0.0) [0.0|119.691] "¢ª"  EMS
	SG_ CR_EndBst_HbriPwr : 48|16@1+ (0.045,0.0) [0.0|99.99] "%"  EMS

BO_ 1411 CUBIS11: 8 CUBIS
	SG_ CF_Cubis_HUDisp : 0|4@1+ (1.0,0.0) [0.0|15.0] ""  CLU

BO_ 899 FATC11: 8 DATC
	SG_ CR_Fatc_TqAcnOut : 0|8@1+ (0.2,0.0) [0.0|50.8] "Nm"  EMS,IBOX
	SG_ CF_Fatc_AcnRqSwi : 8|1@1+ (1.0,0.0) [0.0|1.0] ""  AAF,EMS,IBOX
	SG_ CF_Fatc_AcnCltEnRq : 9|1@1+ (1.0,0.0) [0.0|1.0] ""  EMS,IBOX
	SG_ CF_Fatc_EcvFlt : 10|1@1+ (1.0,0.0) [0.0|1.0] ""  EMS,IBOX
	SG_ CF_Fatc_BlwrOn : 11|1@1+ (1.0,0.0) [0.0|1.0] ""  EMS,IBOX
	SG_ CF_FATC_Iden : 12|2@1+ (1.0,0.0) [0.0|3.0] ""  EMS,IBOX
	SG_ CF_Fatc_BlwrMax : 14|1@1+ (1.0,0.0) [0.0|1.0] ""  CLU,EMS,IBOX
	SG_ CF_Fatc_EngStartReq : 15|1@1+ (1.0,0.0) [0.0|1.0] ""  EMS,IBOX
	SG_ CF_Fatc_IsgStopReq : 16|1@1+ (1.0,0.0) [0.0|1.0] ""  EMS,IBOX
	SG_ CF_Fatc_CtrInf : 17|3@1+ (1.0,0.0) [0.0|7.0] ""  EMS,IBOX
	SG_ CF_Fatc_MsgCnt : 20|4@1+ (1.0,0.0) [0.0|15.0] ""  EMS,IBOX
	SG_ CR_Fatc_OutTemp : 24|8@1+ (0.5,-40.0) [-40.0|60.0] "¡É"  BCM,CLU,EMS,IBOX,SPAS,TCU,TPMS
	SG_ CR_Fatc_OutTempSns : 32|8@1+ (0.5,-40.0) [-40.0|60.0] "¡É"  AAF,AHLS,CLU,EMS,IBOX,SPAS,TCU
	SG_ CF_Fatc_Compload : 40|3@1+ (1.0,0.0) [0.0|7.0] ""  EMS,IBOX
	SG_ CF_Fatc_ActiveEco : 43|1@1+ (1.0,0.0) [0.0|1.0] ""  CLU,IBOX
	SG_ CF_Fatc_AutoActivation : 44|1@1+ (1.0,0.0) [0.0|1.0] ""  IBOX
	SG_ CF_Fatc_DefSw : 45|1@1+ (1.0,0.0) [0.0|1.0] ""  BCM,IBOX
	SG_ CF_Fatc_PtcRlyStat : 46|1@1+ (1.0,0.0) [0.0|1.0] ""  EMS,IBOX
	SG_ CF_Fatc_ChkSum : 56|8@1+ (1.0,0.0) [0.0|255.0] ""  EMS,IBOX,SPAS

BO_ 129 EMS_DCT12: 8 EMS
	SG_ CR_Ems_SoakTimeExt : 0|6@1+ (5.0,0.0) [0.0|315.0] "Min"  TCU
	SG_ BRAKE_ACT : 6|2@1+ (1.0,0.0) [0.0|3.0] ""  TCU
	SG_ CF_Ems_EngOperStat : 8|8@1+ (1.0,0.0) [0.0|255.0] ""  TCU
	SG_ CR_Ems_IndAirTemp : 16|8@1+ (0.75,-48.0) [-48.0|143.25] "¡É"  TCU
	SG_ CF_Ems_Alive2 : 56|4@1+ (1.0,0.0) [0.0|15.0] ""  TCU
	SG_ CF_Ems_ChkSum2 : 60|4@1+ (1.0,0.0) [0.0|15.0] ""  TCU

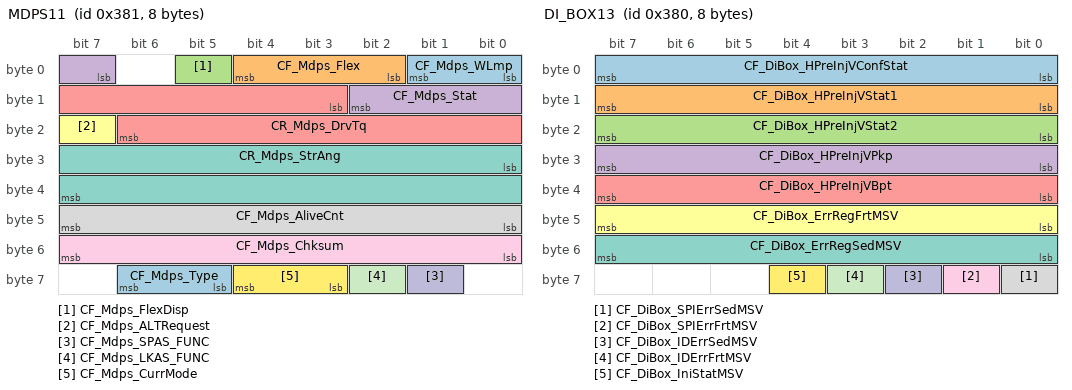
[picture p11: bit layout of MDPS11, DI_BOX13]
BO_ 897 MDPS11: 8 MDPS
	SG_ CF_Mdps_WLmp : 0|2@1+ (1.0,0.0) [0.0|3.0] ""  CLU,CUBIS,EMS,IBOX,SPAS
	SG_ CF_Mdps_Flex : 2|3@1+ (1.0,0.0) [0.0|3.0] ""  CLU,LDWS_LKAS
	SG_ CF_Mdps_FlexDisp : 5|1@1+ (1.0,0.0) [0.0|1.0] ""  CLU
	SG_ CF_Mdps_Stat : 7|4@1+ (1.0,0.0) [0.0|15.0] ""  SPAS
	SG_ CR_Mdps_DrvTq : 11|12@1+ (0.01,-20.48) [-20.48|20.46] ""  SPAS
	SG_ CF_Mdps_ALTRequest : 23|1@1+ (1.0,0.0) [0.0|1.0] ""  EMS
	SG_ CR_Mdps_StrAng : 24|16@1- (0.1,0.0) [-3276.8|3276.7] "Deg"  SPAS
	SG_ CF_Mdps_AliveCnt : 40|8@1+ (1.0,0.0) [0.0|255.0] ""  LDWS_LKAS,SPAS
	SG_ CF_Mdps_Chksum : 48|8@1+ (1.0,0.0) [0.0|255.0] ""  LDWS_LKAS,SPAS
	SG_ CF_Mdps_SPAS_FUNC : 57|1@1+ (1.0,0.0) [0.0|1.0] "flag"  SPAS
	SG_ CF_Mdps_LKAS_FUNC : 58|1@1+ (1.0,0.0) [0.0|1.0] "flag"  LDWS_LKAS
	SG_ CF_Mdps_CurrMode : 59|2@1+ (1.0,0.0) [0.0|3.0] ""  LDWS_LKAS
	SG_ CF_Mdps_Type : 61|2@1+ (1.0,0.0) [0.0|2.0] ""  LDWS_LKAS,SPAS

BO_ 896 DI_BOX13: 8 DI_BOX
	SG_ CF_DiBox_HPreInjVConfStat : 0|8@1+ (1.0,0.0) [0.0|255.0] ""  EMS
	SG_ CF_DiBox_HPreInjVStat1 : 8|8@1+ (1.0,0.0) [0.0|255.0] ""  EMS
	SG_ CF_DiBox_HPreInjVStat2 : 16|8@1+ (1.0,0.0) [0.0|255.0] ""  EMS
	SG_ CF_DiBox_HPreInjVPkp : 24|8@1+ (1.0,0.0) [0.0|255.0] ""  EMS
	SG_ CF_DiBox_HPreInjVBpt : 32|8@1+ (1.0,0.0) [0.0|255.0] ""  EMS
	SG_ CF_DiBox_ErrRegFrtMSV : 40|8@1+ (1.0,0.0) [0.0|255.0] ""  EMS
	SG_ CF_DiBox_ErrRegSedMSV : 48|8@1+ (1.0,0.0) [0.0|255.0] ""  EMS
	SG_ CF_DiBox_SPIErrSedMSV : 56|1@1+ (1.0,0.0) [0.0|1.0] ""  EMS
	SG_ CF_DiBox_SPIErrFrtMSV : 57|1@1+ (1.0,0.0) [0.0|1.0] ""  EMS
	SG_ CF_DiBox_IDErrSedMSV : 58|1@1+ (1.0,0.0) [0.0|1.0] ""  EMS
	SG_ CF_DiBox_IDErrFrtMSV : 59|1@1+ (1.0,0.0) [0.0|1.0] ""  EMS
	SG_ CF_DiBox_IniStatMSV : 60|1@1+ (1.0,0.0) [0.0|1.0] ""  EMS

BO_ 640 EMS13: 8 EMS
	SG_ LV_FUEL_TYPE_ECU : 0|1@1+ (1.0,0.0) [0.0|1.0] ""  BCM,CLU,LPI,SMK
	SG_ LV_BFS_CFIRM : 1|1@1+ (1.0,0.0) [0.0|1.0] ""  LPI
	SG_ LV_CRASH : 2|1@1+ (1.0,0.0) [0.0|1.0] ""  LPI
	SG_ LV_VB_OFF_ACT : 3|1@1+ (1.0,0.0) [0.0|1.0] ""  LPI
	SG_ LV_GSL_MAP M : 4|1@1+ (1.0,0.0) [0.0|1.0] ""  LPI
	SG_ LV_ENG_TURN : 5|1@1+ (1.0,0.0) [0.0|1.0] ""  LPI
	SG_ ERR_FUEL : 8|8@1+ (1.0,0.0) [0.0|255.0] ""  LPI
	SG_ EOS : 16|8@1+ (1.0,0.0) [0.0|255.0] ""  LPI
	SG_ TCO : 24|8@1+ (0.75,-48.0) [-48.0|143.25] "¡É"  LPI
	SG_ N_32 : 32|8@1+ (32.0,0.0) [0.0|8160.0] "rpm"  LPI
	SG_ MAF : 40|8@1+ (5.447,0.0) [0.0|1388.985] "mg/TDC"  LPI
	SG_ TIA : 48|8@1+ (0.75,-48.0) [-48.0|143.25] "¡É"  LPI
	SG_ MAP m1 : 56|8@1+ (0.47058,0.0) [0.0|119.9979] "kPa"  LPI
	SG_ AMP m0 : 56|8@1+ (21.22,0.0) [0.0|5411.1] "hPa"  LPI

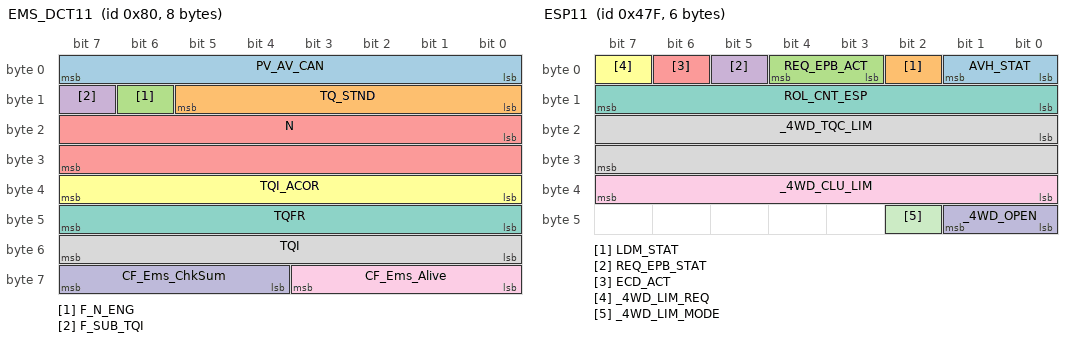
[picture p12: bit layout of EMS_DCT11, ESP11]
BO_ 128 EMS_DCT11: 8 EMS
	SG_ PV_AV_CAN : 0|8@1+ (0.3906,0.0) [0.0|99.603] "%"  TCU
	SG_ TQ_STND : 8|6@1+ (10.0,0.0) [0.0|630.0] "Nm"  TCU
	SG_ F_N_ENG : 14|1@1+ (1.0,0.0) [0.0|1.0] ""  TCU
	SG_ F_SUB_TQI : 15|1@1+ (1.0,0.0) [0.0|1.0] ""  TCU
	SG_ N : 16|16@1+ (0.25,0.0) [0.0|16383.75] "rpm"  TCU
	SG_ TQI_ACOR : 32|8@1+ (0.390625,0.0) [0.0|99.6094] "%"  IBOX,TCU
	SG_ TQFR : 40|8@1+ (0.390625,0.0) [0.0|99.6094] "%"  TCU
	SG_ TQI : 48|8@1+ (0.390625,0.0) [0.0|99.609375] "%"  TCU
	SG_ CF_Ems_Alive : 56|4@1+ (1.0,0.0) [0.0|15.0] ""  TCU
	SG_ CF_Ems_ChkSum : 60|4@1+ (1.0,0.0) [0.0|15.0] ""  TCU

BO_ 1407 HU_MON_PE_01: 8 CLU
	SG_ HU_Type : 0|8@1+ (1.0,0.0) [0.0|255.0] ""  AVM,PGS

BO_ 127 CGW5: 8 BCM
	SG_ C_StopLampLhOpenSts : 0|1@1+ (1.0,0.0) [0.0|1.0] ""  CLU
	SG_ C_StopLampRhOpenSts : 1|1@1+ (1.0,0.0) [0.0|1.0] ""  CLU
	SG_ C_HMSLOpenSts : 2|1@1+ (1.0,0.0) [0.0|1.0] ""  CLU
	SG_ C_HLampLowLhOpenSts : 3|1@1+ (1.0,0.0) [0.0|1.0] ""  CLU
	SG_ C_HLampLowRhOpenSts : 4|1@1+ (1.0,0.0) [0.0|1.0] ""  CLU
	SG_ C_HLampHighLhOpenSts : 5|1@1+ (1.0,0.0) [0.0|1.0] ""  CLU
	SG_ C_HLampHighRhOpenSts : 6|1@1+ (1.0,0.0) [0.0|1.0] ""  CLU
	SG_ C_DRLLampLhOpenSts : 7|1@1+ (1.0,0.0) [0.0|1.0] ""  CLU
	SG_ C_DRLLampRhOpenSts : 8|1@1+ (1.0,0.0) [0.0|1.0] ""  CLU
	SG_ C_RearFOGLhOpenSts : 9|1@1+ (1.0,0.0) [0.0|1.0] ""  CLU
	SG_ C_RearFOGRhOpenSts : 10|1@1+ (1.0,0.0) [0.0|1.0] ""  CLU
	SG_ C_FrontFOGLhOpenSts : 11|1@1+ (1.0,0.0) [0.0|1.0] ""  CLU
	SG_ C_FrontFOGRhOpenSts : 12|1@1+ (1.0,0.0) [0.0|1.0] ""  CLU
	SG_ C_RearEXTTailLhOpenSts : 13|1@1+ (1.0,0.0) [0.0|1.0] ""  CLU
	SG_ C_RearEXTTailRhOpenSts : 14|1@1+ (1.0,0.0) [0.0|1.0] ""  CLU
	SG_ C_FrontEXTTailLhOpenSts : 15|1@1+ (1.0,0.0) [0.0|1.0] ""  CLU
	SG_ C_FrontEXTTailRhOpenSts : 16|1@1+ (1.0,0.0) [0.0|1.0] ""  CLU
	SG_ C_RearTSIGLhOpenSts : 17|1@1+ (1.0,0.0) [0.0|1.0] ""  CLU
	SG_ C_RearTSIGRhOpenSts : 18|1@1+ (1.0,0.0) [0.0|1.0] ""  CLU
	SG_ C_FrontTSIGLhOpenSts : 19|1@1+ (1.0,0.0) [0.0|1.0] ""  CLU
	SG_ C_FrontTSIGRhOpenSts : 20|1@1+ (1.0,0.0) [0.0|1.0] ""  CLU
	SG_ C_SBendingLhOpenSts : 21|1@1+ (1.0,0.0) [0.0|1.0] ""  CLU
	SG_ C_SBendingRhOpenSts : 22|1@1+ (1.0,0.0) [0.0|1.0] ""  CLU
	SG_ C_LicensePlateLhOpenSts : 23|1@1+ (1.0,0.0) [0.0|1.0] ""  CLU
	SG_ C_LicensePlateRhOpenSts : 24|1@1+ (1.0,0.0) [0.0|1.0] ""  CLU

BO_ 1151 ESP11: 6 ESC
	SG_ AVH_STAT : 0|2@1+ (1.0,0.0) [0.0|3.0] ""  EMS,EPB,TCU
	SG_ LDM_STAT : 2|1@1+ (1.0,0.0) [0.0|1.0] ""  EPB,TCU
	SG_ REQ_EPB_ACT : 3|2@1+ (1.0,0.0) [0.0|3.0] ""  EPB,TCU
	SG_ REQ_EPB_STAT : 5|1@1+ (1.0,0.0) [0.0|1.0] ""  EPB
	SG_ ECD_ACT : 6|1@1+ (1.0,0.0) [0.0|1.0] ""  EPB
	SG_ _4WD_LIM_REQ : 7|1@1+ (1.0,0.0) [0.0|1.0] ""  _4WD,EMS
	SG_ ROL_CNT_ESP : 8|8@1+ (1.0,0.0) [0.0|255.0] ""  EPB,TCU
	SG_ _4WD_TQC_LIM : 16|16@1+ (1.0,0.0) [0.0|65535.0] "Nm"  _4WD,EMS
	SG_ _4WD_CLU_LIM : 32|8@1+ (0.390625,0.0) [0.0|99.609375] "%"  _4WD,EMS
	SG_ _4WD_OPEN : 40|2@1+ (1.0,0.0) [0.0|3.0] ""  _4WD,EMS
	SG_ _4WD_LIM_MODE : 42|1@1+ (1.0,0.0) [0.0|1.0] ""  _4WD

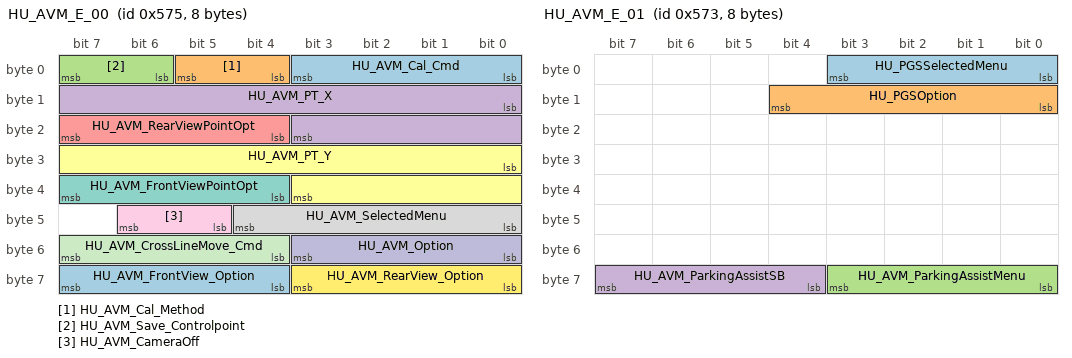
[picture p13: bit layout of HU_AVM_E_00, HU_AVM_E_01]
BO_ 1397 HU_AVM_E_00: 8 CLU
	SG_ HU_AVM_Cal_Cmd : 0|4@1+ (1.0,0.0) [0.0|15.0] ""  AVM,PGS
	SG_ HU_AVM_Cal_Method : 4|2@1+ (1.0,0.0) [0.0|3.0] ""  AVM,PGS
	SG_ HU_AVM_Save_Controlpoint : 6|2@1+ (1.0,0.0) [0.0|3.0] ""  AVM,PGS
	SG_ HU_AVM_PT_X : 8|12@1+ (1.0,0.0) [0.0|15.0] ""  AVM,PGS
	SG_ HU_AVM_RearViewPointOpt : 20|4@1+ (1.0,0.0) [0.0|15.0] ""  AVM,PGS
	SG_ HU_AVM_PT_Y : 24|12@1+ (1.0,0.0) [0.0|4095.0] ""  AVM,PGS
	SG_ HU_AVM_FrontViewPointOpt : 36|4@1+ (1.0,0.0) [0.0|15.0] ""  AVM,PGS
	SG_ HU_AVM_SelectedMenu : 40|5@1+ (1.0,0.0) [0.0|31.0] ""  AVM,PGS
	SG_ HU_AVM_CameraOff : 45|2@1+ (1.0,0.0) [0.0|3.0] ""  AVM,PGS
	SG_ HU_AVM_Option : 48|4@1+ (1.0,0.0) [0.0|15.0] ""  AVM,PGS
	SG_ HU_AVM_CrossLineMove_Cmd : 52|4@1+ (1.0,0.0) [0.0|15.0] ""  AVM,PGS
	SG_ HU_AVM_RearView_Option : 56|4@1+ (1.0,0.0) [0.0|15.0] ""  AVM,PGS
	SG_ HU_AVM_FrontView_Option : 60|4@1+ (1.0,0.0) [0.0|15.0] ""  AVM,PGS

BO_ 1395 HU_AVM_E_01: 8 CLU
	SG_ HU_PGSSelectedMenu : 0|4@1+ (1.0,0.0) [0.0|15.0] ""  AVM,PGS
	SG_ HU_PGSOption : 8|5@1+ (1.0,0.0) [0.0|31.0] ""  AVM,PGS
	SG_ HU_AVM_ParkingAssistMenu : 56|4@1+ (1.0,0.0) [0.0|15.0] ""  AVM,PGS
	SG_ HU_AVM_ParkingAssistSB : 60|4@1+ (1.0,0.0) [0.0|15.0] ""  AVM,PGS

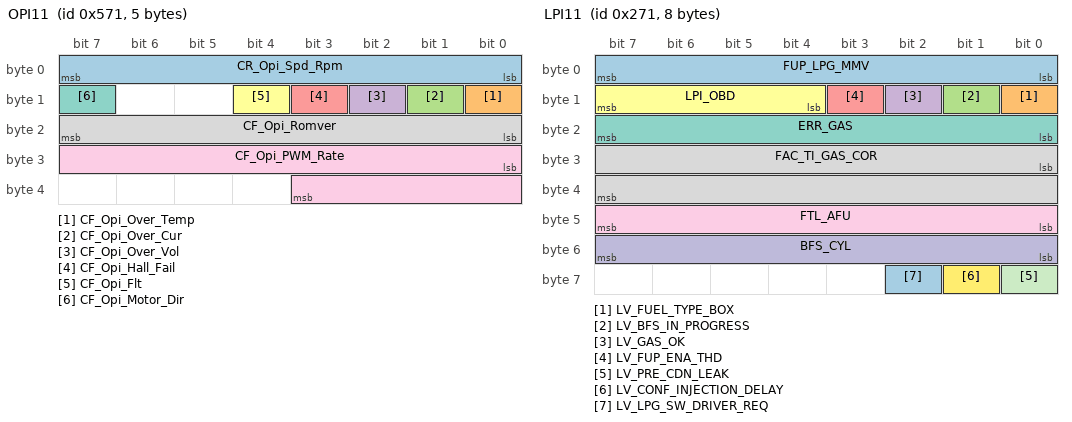
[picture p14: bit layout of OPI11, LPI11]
BO_ 1393 OPI11: 5 OPI
	SG_ CR_Opi_Spd_Rpm : 0|8@1+ (20.0,0.0) [0.0|3500.0] "rpm"  TCU
	SG_ CF_Opi_Over_Temp : 8|1@1+ (1.0,0.0) [0.0|1.0] ""  TCU
	SG_ CF_Opi_Over_Cur : 9|1@1+ (1.0,0.0) [0.0|1.0] ""  EMS,TCU
	SG_ CF_Opi_Over_Vol : 10|1@1+ (1.0,0.0) [0.0|1.0] ""  TCU
	SG_ CF_Opi_Hall_Fail : 11|1@1+ (1.0,0.0) [0.0|1.0] ""  EMS,TCU
	SG_ CF_Opi_Flt : 12|1@1+ (1.0,0.0) [0.0|1.0] ""  EMS,TCU
	SG_ CF_Opi_Motor_Dir : 15|1@1+ (1.0,0.0) [0.0|1.0] ""  TCU
	SG_ CF_Opi_Romver : 16|8@1+ (1.0,0.0) [0.0|255.0] ""  TCU
	SG_ CF_Opi_PWM_Rate : 24|12@1+ (1.0,0.0) [0.0|100.0] "%"  TCU

BO_ 625 LPI11: 8 LPI
	SG_ FUP_LPG_MMV : 0|8@1+ (128.0,0.0) [0.0|32640.0] "hPa"  EMS
	SG_ LV_FUEL_TYPE_BOX : 8|1@1+ (1.0,0.0) [0.0|1.0] ""  EMS
	SG_ LV_BFS_IN_PROGRESS : 9|1@1+ (1.0,0.0) [0.0|1.0] ""  EMS
	SG_ LV_GAS_OK : 10|1@1+ (1.0,0.0) [0.0|1.0] ""  EMS
	SG_ LV_FUP_ENA_THD : 11|1@1+ (1.0,0.0) [0.0|1.0] ""  BCM,CLU,EMS,SMK
	SG_ LPI_OBD : 12|4@1+ (1.0,0.0) [0.0|15.0] ""  EMS
	SG_ ERR_GAS : 16|8@1+ (1.0,0.0) [0.0|255.0] ""  EMS
	SG_ FAC_TI_GAS_COR : 24|16@1+ (3.05E-5,0.0) [0.0|1.9988175] ""  EMS
	SG_ FTL_AFU : 40|8@1+ (0.392,0.0) [0.0|99.96] "%"  EMS
	SG_ BFS_CYL : 48|8@1+ (1.0,0.0) [0.0|6.0] "Cyl Nr."  EMS
	SG_ LV_PRE_CDN_LEAK : 56|1@1+ (1.0,0.0) [0.0|1.0] ""  EMS
	SG_ LV_CONF_INJECTION_DELAY : 57|1@1+ (1.0,0.0) [0.0|1.0] ""  EMS
	SG_ LV_LPG_SW_DRIVER_REQ : 58|1@1+ (1.0,0.0) [0.0|1.0] ""  EMS

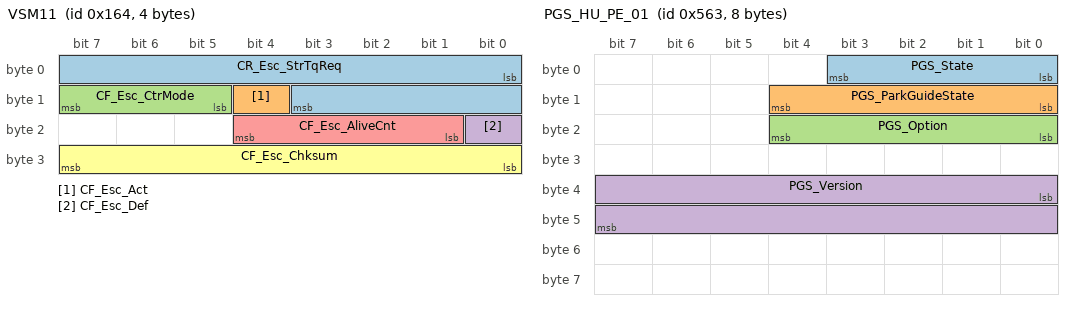
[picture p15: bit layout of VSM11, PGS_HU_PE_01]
BO_ 356 VSM11: 4 ESC
	SG_ CR_Esc_StrTqReq : 0|12@1+ (0.01,-20.48) [-20.48|20.47] "Nm"  MDPS
	SG_ CF_Esc_Act : 12|1@1+ (1.0,0.0) [0.0|1.0] ""  LDWS_LKAS,MDPS
	SG_ CF_Esc_CtrMode : 13|3@1+ (1.0,0.0) [0.0|7.0] ""  MDPS
	SG_ CF_Esc_Def : 16|1@1+ (1.0,0.0) [0.0|1.0] ""  MDPS
	SG_ CF_Esc_AliveCnt : 17|4@1+ (1.0,0.0) [0.0|15.0] ""  LDWS_LKAS,MDPS
	SG_ CF_Esc_Chksum : 24|8@1+ (1.0,0.0) [0.0|255.0] ""  LDWS_LKAS,MDPS

BO_ 1379 PGS_HU_PE_01: 8 PGS
	SG_ PGS_State : 0|4@1+ (1.0,0.0) [0.0|15.0] ""  CLU
	SG_ PGS_ParkGuideState : 8|5@1+ (1.0,0.0) [0.0|31.0] ""  CLU
	SG_ PGS_Option : 16|5@1+ (1.0,0.0) [0.0|31.0] ""  CLU
	SG_ PGS_Version : 32|16@1+ (1.0,0.0) [0.0|65535.0] ""  CLU

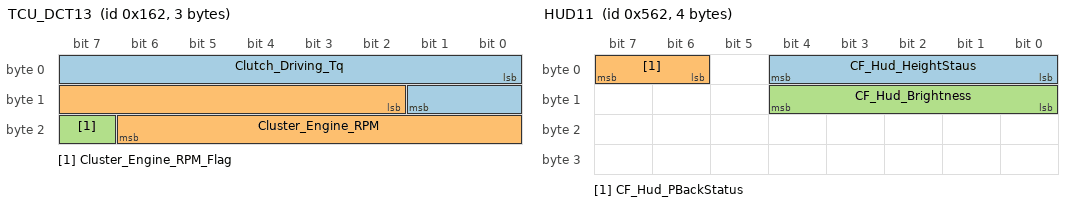
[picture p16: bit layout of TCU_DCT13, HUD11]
BO_ 354 TCU_DCT13: 3 TCU
	SG_ Clutch_Driving_Tq : 0|10@1+ (1.0,-512.0) [0.0|0.0] "Nm"  ESC
	SG_ Cluster_Engine_RPM : 10|13@1+ (0.9766,0.0) [0.0|0.0] ""  CLU
	SG_ Cluster_Engine_RPM_Flag : 23|1@1+ (1.0,0.0) [0.0|0.0] ""  CLU

BO_ 1378 HUD11: 4 HUD
	SG_ CF_Hud_HeightStaus : 0|5@1+ (1.0,0.0) [0.0|31.0] ""  CLU
	SG_ CF_Hud_PBackStatus : 6|2@1+ (1.0,0.0) [0.0|0.0] ""  BCM,CLU
	SG_ CF_Hud_Brightness : 8|5@1+ (1.0,0.0) [0.0|31.0] ""  CLU

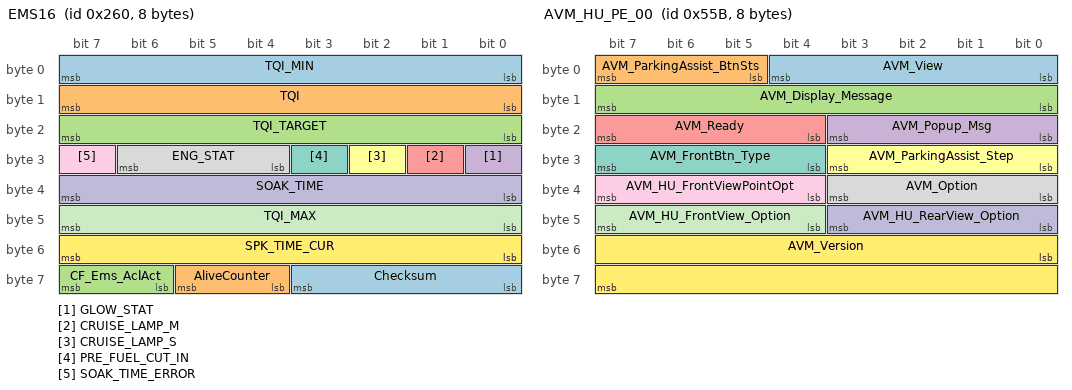
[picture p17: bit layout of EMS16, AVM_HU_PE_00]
BO_ 608 EMS16: 8 EMS
	SG_ TQI_MIN : 0|8@1+ (0.390625,0.0) [0.0|99.609375] "%"  ESC,IBOX,TCU
	SG_ TQI : 8|8@1+ (0.390625,0.0) [0.0|99.609375] "%"  ESC,IBOX,TCU
	SG_ TQI_TARGET : 16|8@1+ (0.390625,0.0) [0.0|99.609375] "%"  EPB,ESC,IBOX,TCU
	SG_ GLOW_STAT : 24|1@1+ (1.0,0.0) [0.0|1.0] ""  BCM,CLU,IBOX,SMK
	SG_ CRUISE_LAMP_M : 25|1@1+ (1.0,0.0) [0.0|1.0] ""  CLU,IBOX,TCU
	SG_ CRUISE_LAMP_S : 26|1@1+ (1.0,0.0) [0.0|1.0] ""  CLU,IBOX,TCU
	SG_ PRE_FUEL_CUT_IN : 27|1@1+ (1.0,0.0) [0.0|1.0] ""  IBOX,TCU
	SG_ ENG_STAT : 28|3@1+ (1.0,0.0) [0.0|7.0] ""  ABS,AHLS,AVM,BCM,CLU,EPB,ESC,EVP,FPCM,IBOX,LCA,LDWS_LKAS,MDPS,SCC,SMK,TCU
	SG_ SOAK_TIME_ERROR : 31|1@1+ (1.0,0.0) [0.0|1.0] ""  DATC,EPB,IBOX,TCU
	SG_ SOAK_TIME : 32|8@1+ (1.0,0.0) [0.0|255.0] "Min"  _4WD,DATC,EPB,IBOX,TCU
	SG_ TQI_MAX : 40|8@1+ (0.390625,0.0) [0.0|99.609375] "%"  ESC,IBOX,TCU
	SG_ SPK_TIME_CUR : 48|8@1+ (0.375,-35.625) [-35.625|60.0] "¢ª"  IBOX,TCU
	SG_ Checksum : 56|4@1+ (1.0,0.0) [0.0|15.0] ""  ECS,IBOX,LDWS_LKAS,MDPS,SCC
	SG_ AliveCounter : 60|2@1+ (1.0,0.0) [0.0|3.0] ""  IBOX,LDWS_LKAS,MDPS,SCC
	SG_ CF_Ems_AclAct : 62|2@1+ (1.0,0.0) [0.0|3.0] ""  IBOX,SCC

BO_ 1371 AVM_HU_PE_00: 8 AVM
	SG_ AVM_View : 0|5@1+ (1.0,0.0) [0.0|31.0] ""  CLU
	SG_ AVM_ParkingAssist_BtnSts : 5|3@1+ (1.0,0.0) [0.0|7.0] ""  CLU
	SG_ AVM_Display_Message : 8|8@1+ (1.0,0.0) [0.0|255.0] ""  CLU
	SG_ AVM_Popup_Msg : 16|4@1+ (1.0,0.0) [0.0|15.0] ""  CLU
	SG_ AVM_Ready : 20|4@1+ (1.0,0.0) [0.0|15.0] ""  CLU
	SG_ AVM_ParkingAssist_Step : 24|4@1+ (1.0,0.0) [0.0|15.0] ""  CLU
	SG_ AVM_FrontBtn_Type : 28|4@1+ (1.0,0.0) [0.0|15.0] ""  CLU
	SG_ AVM_Option : 32|4@1+ (1.0,0.0) [0.0|15.0] ""  CLU
	SG_ AVM_HU_FrontViewPointOpt : 36|4@1+ (1.0,0.0) [0.0|15.0] ""  CLU
	SG_ AVM_HU_RearView_Option : 40|4@1+ (1.0,0.0) [0.0|15.0] ""  CLU
	SG_ AVM_HU_FrontView_Option : 44|4@1+ (1.0,0.0) [0.0|15.0] ""  CLU
	SG_ AVM_Version : 48|16@1+ (1.0,0.0) [0.0|65535.0] ""  CLU

BO_ 1370 HU_AVM_PE_00: 8 CLU
	SG_ HU_AVM_Status : 0|2@1+ (1.0,0.0) [0.0|3.0] ""  AVM,PGS

BO_ 1369 CGW4: 8 BCM
	SG_ CF_Gway_MemoryP1Cmd : 0|1@1+ (1.0,0.0) [0.0|1.0] ""  CLU
	SG_ CF_Gway_MemoryP2Cmd : 1|1@1+ (1.0,0.0) [0.0|1.0] ""  CLU
	SG_ CF_Gway_PBackP1Cmd : 2|1@1+ (1.0,0.0) [0.0|1.0] ""  CLU
	SG_ CF_Gway_PBackP2Cmd : 3|1@1+ (1.0,0.0) [0.0|1.0] ""  CLU
	SG_ CF_Gway_StrgWhlHeatedState : 4|1@1+ (1.0,0.0) [0.0|1.0] ""  CLU
	SG_ CF_Gway_PBackStopCmd : 5|1@1+ (1.0,0.0) [0.0|1.0] ""  CLU,HUD
	SG_ CF_Gway_StaticBendLhAct : 6|1@1+ (1.0,0.0) [0.0|1.0] ""  CLU
	SG_ CF_Gway_StaticBendRhAct : 7|1@1+ (1.0,0.0) [0.0|1.0] ""  CLU
	SG_ CF_Gway_DrvWdwStat : 8|1@1+ (1.0,0.0) [0.0|1.0] ""  CLU
	SG_ CF_Gway_RLWdwState : 9|1@1+ (1.0,0.0) [0.0|1.0] ""  CLU
	SG_ CF_Gway_RRWdwState : 10|1@1+ (1.0,0.0) [0.0|1.0] ""  CLU
	SG_ CF_Gway_AstWdwStat : 11|1@1+ (1.0,0.0) [0.0|1.0] ""  CLU
	SG_ CF_Gway_MemoryEnable : 12|1@1+ (1.0,0.0) [0.0|1.0] ""  CLU
	SG_ CF_Gway_PBACKStopCmd : 13|1@1+ (1.0,0.0) [0.0|1.0] ""  CLU
	SG_ CF_Gway_PBACKStop : 14|1@1+ (1.0,0.0) [0.0|1.0] ""  CLU,HUD
	SG_ CF_Gway_IMSBuzzer : 15|1@1+ (1.0,0.0) [0.0|1.0] ""  CLU
	SG_ CF_Gway_DrvSeatBeltInd : 36|2@1+ (1.0,0.0) [0.0|3.0] ""  CLU,Dummy
	SG_ CF_Gway_AstSeatBeltInd : 38|2@1+ (1.0,0.0) [0.0|3.0] ""  CLU
	SG_ CF_Gway_RCSeatBeltInd : 40|2@1+ (1.0,0.0) [0.0|3.0] ""  CLU
	SG_ CF_Gway_RLSeatBeltInd : 42|2@1+ (1.0,0.0) [0.0|3.0] ""  CLU
	SG_ CF_Gway_RRSeatBeltInd : 44|2@1+ (1.0,0.0) [0.0|3.0] ""  CLU
	SG_ CF_Gway_RrWiperHighSw : 46|1@1+ (1.0,0.0) [0.0|1.0] ""  CLU
	SG_ CF_Gway_RrWiperLowSw : 47|1@1+ (1.0,0.0) [0.0|1.0] ""  CLU

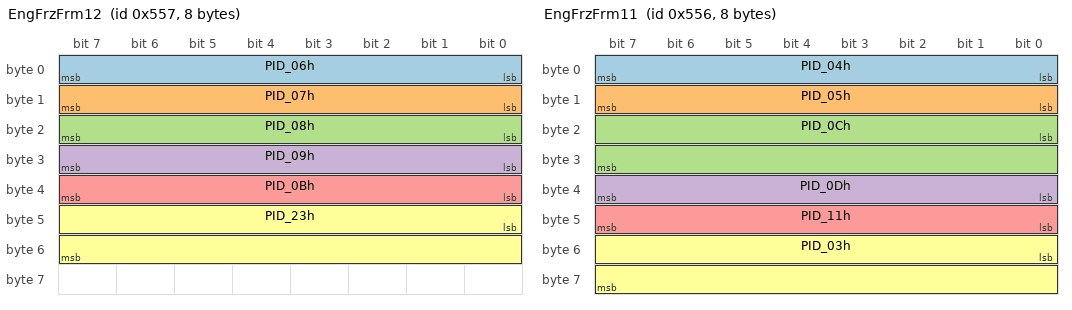
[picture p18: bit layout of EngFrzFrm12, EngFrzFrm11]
BO_ 1367 EngFrzFrm12: 8 EMS
	SG_ PID_06h : 0|8@1+ (0.78125,-100.0) [-100.0|99.22] "%"  AAF,IBOX,TCU
	SG_ PID_07h : 8|8@1+ (0.78125,-100.0) [-100.0|99.22] "%"  AAF,IBOX,TCU
	SG_ PID_08h : 16|8@1+ (0.78125,-100.0) [-100.0|99.22] "%"  AAF,IBOX,TCU
	SG_ PID_09h : 24|8@1+ (0.78125,-100.0) [-100.0|99.22] "%"  AAF,IBOX,TCU
	SG_ PID_0Bh : 32|8@1+ (1.0,0.0) [0.0|255.0] "kPa"  AAF,IBOX,TCU
	SG_ PID_23h : 40|16@1+ (10.0,0.0) [0.0|655350.0] "kPa"  AAF,IBOX,TCU

BO_ 1366 EngFrzFrm11: 8 EMS
	SG_ PID_04h : 0|8@1+ (0.3921568627,0.0) [0.0|100.0] "%"  AAF,TCU
	SG_ PID_05h : 8|8@1+ (1.0,-40.0) [-40.0|215.0] "¡É"  AAF,TCU
	SG_ PID_0Ch : 16|16@1+ (0.25,0.0) [0.0|16383.75] "rpm"  AAF,TCU
	SG_ PID_0Dh : 32|8@1+ (1.0,0.0) [0.0|255.0] "km/h"  AAF,TCU
	SG_ PID_11h : 40|8@1+ (0.3921568627,0.0) [0.0|100.0] "%"  AAF,TCU
	SG_ PID_03h : 48|16@1+ (1.0,0.0) [0.0|65535.0] ""  AAF,TCU

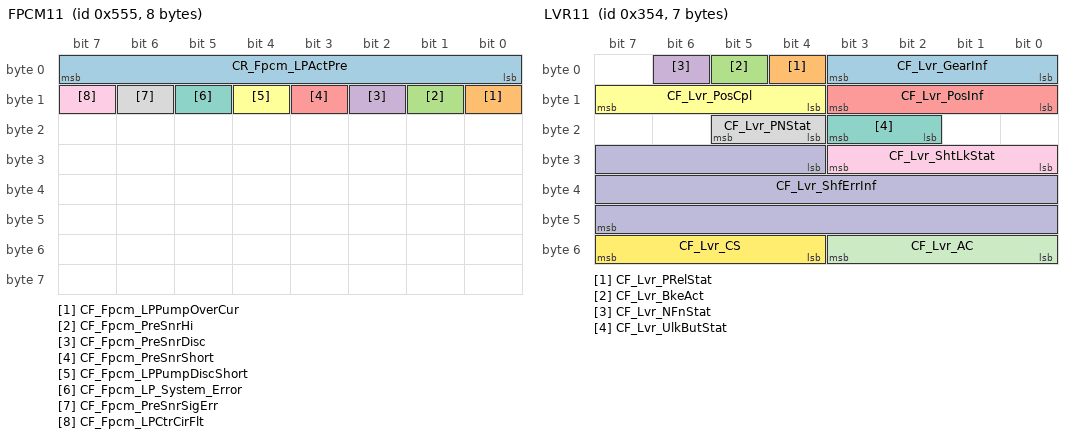
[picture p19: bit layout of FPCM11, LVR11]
BO_ 1365 FPCM11: 8 FPCM
	SG_ CR_Fpcm_LPActPre : 0|8@1+ (3.137254902,0.0) [0.0|800.0] "kPa"  EMS
	SG_ CF_Fpcm_LPPumpOverCur : 8|1@1+ (1.0,0.0) [0.0|1.0] ""  EMS
	SG_ CF_Fpcm_PreSnrHi : 9|1@1+ (1.0,0.0) [0.0|1.0] ""  EMS
	SG_ CF_Fpcm_PreSnrDisc : 10|1@1+ (1.0,0.0) [0.0|1.0] ""  EMS
	SG_ CF_Fpcm_PreSnrShort : 11|1@1+ (1.0,0.0) [0.0|1.0] ""  EMS
	SG_ CF_Fpcm_LPPumpDiscShort : 12|1@1+ (1.0,0.0) [0.0|1.0] ""  EMS
	SG_ CF_Fpcm_LP_System_Error : 13|1@1+ (1.0,0.0) [0.0|1.0] ""  EMS
	SG_ CF_Fpcm_PreSnrSigErr : 14|1@1+ (1.0,0.0) [0.0|1.0] ""  EMS
	SG_ CF_Fpcm_LPCtrCirFlt : 15|1@1+ (1.0,0.0) [0.0|1.0] ""  EMS

BO_ 852 LVR11: 7 LVR
	SG_ CF_Lvr_GearInf : 0|4@1+ (1.0,0.0) [0.0|15.0] ""  CLU,TCU
	SG_ CF_Lvr_PRelStat : 4|1@1+ (1.0,0.0) [0.0|1.0] ""  BCM,CLU,SMK,TCU
	SG_ CF_Lvr_BkeAct : 5|1@1+ (1.0,0.0) [0.0|1.0] ""  TCU
	SG_ CF_Lvr_NFnStat : 6|1@1+ (1.0,0.0) [0.0|1.0] ""  CLU
	SG_ CF_Lvr_PosInf : 8|4@1+ (1.0,0.0) [0.0|15.0] ""  TCU
	SG_ CF_Lvr_PosCpl : 12|4@1+ (1.0,0.0) [0.0|15.0] ""  TCU
	SG_ CF_Lvr_UlkButStat : 18|2@1+ (1.0,0.0) [0.0|3.0] ""  TCU
	SG_ CF_Lvr_PNStat : 20|2@1+ (1.0,0.0) [0.0|3.0] ""  CLU
	SG_ CF_Lvr_ShtLkStat : 24|4@1+ (1.0,0.0) [0.0|15.0] ""  TCU
	SG_ CF_Lvr_ShfErrInf : 28|20@1+ (1.0,0.0) [0.0|8191.0] ""  CLU,TCU
	SG_ CF_Lvr_AC : 48|4@1+ (1.0,0.0) [0.0|15.0] ""  TCU
	SG_ CF_Lvr_CS : 52|4@1+ (1.0,0.0) [0.0|15.0] ""  TCU

BO_ 1363 CGW2: 8 BCM
	SG_ CF_Gway_GwayDiagState : 0|1@1+ (1.0,0.0) [0.0|3.0] ""  CLU,Dummy
	SG_ CF_Gway_DDMDiagState : 1|1@1+ (1.0,0.0) [0.0|1.0] ""  CLU,Dummy
	SG_ CF_Gway_SCMDiagState : 2|1@1+ (1.0,0.0) [0.0|1.0] ""  CLU,Dummy
	SG_ CF_Gway_PSMDiagState : 3|1@1+ (1.0,0.0) [0.0|1.0] ""  CLU,Dummy
	SG_ CF_Gway_SJBDiagState : 4|1@1+ (1.0,0.0) [0.0|1.0] ""  CLU,Dummy
	SG_ CF_Gway_IPMDiagState : 5|1@1+ (1.0,0.0) [0.0|1.0] ""  CLU,Dummy
	SG_ CF_Gway_LDMFail : 6|2@1+ (1.0,0.0) [0.0|3.0] ""  CLU,LDWS_LKAS,LDWS_LKAS
	SG_ CF_Gway_CLUSwGuiCtrl : 10|3@1+ (1.0,0.0) [0.0|63.0] ""  CLU,Dummy
	SG_ CF_Gway_CLUSwGroup : 13|1@1+ (1.0,0.0) [0.0|1.0] ""  CLU,Dummy
	SG_ CF_Gway_CLUSwMode : 14|1@1+ (1.0,0.0) [0.0|1.0] ""  CLU,Dummy
	SG_ CF_Gway_CLUSwEnter : 15|1@1+ (1.0,0.0) [0.0|1.0] ""  CLU,Dummy
	SG_ CF_Gway_AutoLightValue : 16|1@1+ (1.0,0.0) [0.0|1.0] ""  LCA,LCA
	SG_ CF_Gway_BrakeFluidSw : 17|1@1+ (1.0,0.0) [0.0|1.0] ""  CLU,Dummy
	SG_ CF_Gway_DrvSeatBeltInd : 18|2@1+ (1.0,0.0) [0.0|3.0] ""  CLU
	SG_ CF_Gway_AvTail : 20|1@1+ (1.0,0.0) [0.0|3.0] ""  CLU,SNV,SNV
	SG_ CF_Gway_RearFogAct : 21|1@1+ (1.0,0.0) [0.0|1.0] ""  CLU,Dummy
	SG_ CF_Gway_ExtTailAct : 22|1@1+ (1.0,0.0) [0.0|1.0] ""  AVM,CLU,LCA,PGS,SPAS,AVM,LCA,PGS,SPAS
	SG_ CF_Gway_RRDrSw : 23|1@1+ (1.0,0.0) [0.0|1.0] ""  CLU,Dummy
	SG_ CF_Gway_RLDrSw : 24|1@1+ (1.0,0.0) [0.0|1.0] ""  CLU,Dummy
	SG_ CF_Gway_IntTailAct : 25|1@1+ (1.0,0.0) [0.0|1.0] ""  CLU,Dummy
	SG_ CF_Gway_CountryCfg : 26|3@1+ (1.0,0.0) [0.0|7.0] ""  AVM,CLU,PGS,Dummy
	SG_ CF_Gway_WiperParkPosition : 32|1@1+ (1.0,0.0) [0.0|1.0] ""  AFLS,EMS,LDWS_LKAS,AFLS,EMS,LDWS_LKAS
	SG_ CF_Gway_HLLowLHFail : 33|1@1+ (1.0,0.0) [0.0|1.0] ""  LDWS_LKAS,SNV,LDWS_LKAS,SNV
	SG_ CF_Gway_HLLowRHFail : 34|1@1+ (1.0,0.0) [0.0|1.0] ""  LDWS_LKAS,SNV,LDWS_LKAS,SNV
	SG_ CF_Gway_ESCLFailWarn : 35|1@1+ (1.0,0.0) [0.0|1.0] ""  CLU,Dummy
	SG_ CF_Gway_ESCLNotLockedWarn : 36|1@1+ (1.0,0.0) [0.0|1.0] ""  CLU,Dummy
	SG_ CF_Gway_ESCLNotUnlockWarn : 37|1@1+ (1.0,0.0) [0.0|1.0] ""  CLU,Dummy
	SG_ CF_Gway_IDoutWarn : 38|1@1+ (1.0,0.0) [0.0|1.0] ""  CLU,Dummy
	SG_ CF_Gway_ImmoLp : 40|1@1+ (1.0,0.0) [0.0|3.0] ""  CLU,Dummy
	SG_ CF_Gway_BCMRKEID : 41|3@1+ (1.0,0.0) [0.0|7.0] ""  CLU,Dummy
	SG_ CF_Gway_VehicleNotPWarn : 44|1@1+ (1.0,0.0) [0.0|1.0] ""  CLU,Dummy
	SG_ CF_Gway_DeactivationWarn : 45|1@1+ (1.0,0.0) [0.0|1.0] ""  CLU,Dummy
	SG_ CF_Gway_KeyBATDischargeWarn : 46|1@1+ (1.0,0.0) [0.0|1.0] ""  CLU,Dummy
	SG_ CF_Gway_SSBWarn : 47|1@1+ (1.0,0.0) [0.0|1.0] ""  CLU,Dummy
	SG_ CF_Gway_SMKFobID : 48|3@1+ (1.0,0.0) [0.0|7.0] ""  CLU,Dummy
	SG_ CF_Gway_SMKRKECmd : 51|3@1+ (1.0,0.0) [0.0|7.0] ""  CLU,Dummy
	SG_ CF_Gway_AutoLightOption : 54|1@1+ (1.0,0.0) [0.0|1.0] ""  CLU
	SG_ CF_Gway_SJBDeliveryMode : 55|1@1+ (1.0,0.0) [0.0|1.0] ""  CLU,Dummy
	SG_ CF_Gway_KeyoutLp : 56|1@1+ (1.0,0.0) [0.0|1.0] ""  CLU,Dummy
	SG_ CF_Gway_SMKDispWarn : 57|4@1+ (1.0,0.0) [0.0|15.0] ""  CLU,Dummy
	SG_ CF_Gway_WngBuz : 61|3@1+ (1.0,0.0) [0.0|7.0] ""  CLU,Dummy

BO_TX_BU_ 903 : ABS,ESC;
BO_TX_BU_ 902 : ABS,ESC;
BO_TX_BU_ 1427 : BCM,TPMS;
BO_TX_BU_ 1363 : BCM,CLU;
BO_TX_BU_ 688 : MDPS,SAS;
CM_ BO_ 1412 "[P] Periodic";
CM_ SG_ 1412 CF_Aaf_ActFlapStatus "Unknown : When the potentiometer or other parts are in faulty status, AAF actuator cannot recognize the position of air flaps. In this case, AAF actuator should set the value of CF_Aaf_ActFlapStatus to ¡°Unknown¡±.";
CM_ SG_ 1412 CF_Aaf_ModeStatus "Fail Safety Mode is indicated when the flap is opened by Fail Safety Mode";
CM_ BO_ 906 "[P] Periodic";
CM_ BO_ 903 "[P] Periodic";
CM_ BO_ 902 "[P] Periodic";
CM_ BO_ 1440 "[P] Periodic";
CM_ SG_ 1440 CF_SWL_Ind "Transmit condition : Send ACU Diagnostic result(when crash output signal is
issued or ACU is entered to extended diagnostic mode, stop to send message)";
CM_ SG_ 1440 CF_Acu_FltStat "Transmit condition : Send ACU Diagnostic result(when crash output signal is
issued or ACU is entered to extended diagnostic mode, stop to send message)";
CM_ SG_ 1440 CF_Acu_Dtc "Transmit condition : Send ACU Diagnostic result(when crash output signal is
issued or ACU is entered to extended diagnostic mode, stop to send message)
Refer to the attached file (figure)";
CM_ BO_ 1441 "[P] Periodic";
CM_ BO_ 1425 "[P] Periodic";
CM_ BO_ 1437 "[P] Periodic";
CM_ BO_ 1371 "[PE] Periodic and On Event";
CM_ BO_ 1363 "[PE] Periodic and On Event";
CM_ SG_ 1363 CF_Gway_GwayDiagState "This signal is for ¡°IPM (Gateway)¡± applied vehicles only.";
CM_ SG_ 1363 CF_Gway_DDMDiagState "This signal is for ¡°IPM (Gateway)¡± applied vehicles only.";
CM_ SG_ 1363 CF_Gway_SCMDiagState "This signal is for ¡°IPM (Gateway)¡± applied vehicles only.";
CM_ SG_ 1363 CF_Gway_PSMDiagState "This signal is for ¡°IPM (Gateway)¡± applied vehicles only.";
CM_ SG_ 1363 CF_Gway_SJBDiagState "This signal is for ¡°IPM (Gateway)¡± applied vehicles only.";
CM_ SG_ 1363 CF_Gway_IPMDiagState "This signal is for ¡°IPM (Gateway)¡± applied vehicles only.";
CM_ SG_ 1363 CF_Gway_LDMFail "This signal is for ¡°IPM (Gateway)¡± applied vehicles only.";
CM_ SG_ 1363 CF_Gway_CLUSwGuiCtrl "This signal is for ¡°IPM (Gateway)¡± applied vehicles only.";
CM_ SG_ 1363 CF_Gway_CLUSwGroup "This signal is for ¡°IPM (Gateway)¡± applied vehicles only.";
CM_ SG_ 1363 CF_Gway_CLUSwMode "This signal is for ¡°IPM (Gateway)¡± applied vehicles only.";
CM_ SG_ 1363 CF_Gway_CLUSwEnter "This signal is for ¡°IPM (Gateway)¡± applied vehicles only.";
CM_ SG_ 1363 CF_Gway_DrvSeatBeltInd "This signal is for ¡°IPM (Gateway)¡± applied vehicles only.";
CM_ SG_ 1363 CF_Gway_AvTail "This signal is for ¡°IPM (Gateway)¡± applied vehicles only.";
CM_ SG_ 1363 CF_Gway_RearFogAct "This signal is for ¡°IPM (Gateway)¡± applied vehicles only.";
CM_ SG_ 1363 CF_Gway_ExtTailAct "This signal is for ¡°IPM (Gateway)¡± applied vehicles only.";
CM_ SG_ 1363 CF_Gway_RRDrSw "This signal is for ¡°IPM (Gateway)¡± applied vehicles only.";
CM_ SG_ 1363 CF_Gway_RLDrSw "This signal is for ¡°IPM (Gateway)¡± applied vehicles only.";
CM_ SG_ 1363 CF_Gway_IntTailAct "This signal is for ¡°IPM (Gateway)¡± applied vehicles only.";
CM_ SG_ 1363 CF_Gway_CountryCfg "This signal is for ¡°IPM (Gateway)¡± applied vehicles only.";
CM_ SG_ 1363 CF_Gway_ESCLFailWarn "This signal is for ¡°IPM (Gateway)¡± applied vehicles only.";
CM_ SG_ 1363 CF_Gway_ESCLNotLockedWarn "This signal is for ¡°IPM (Gateway)¡± applied vehicles only.";
CM_ SG_ 1363 CF_Gway_ESCLNotUnlockWarn "This signal is for ¡°IPM (Gateway)¡± applied vehicles only.";
CM_ SG_ 1363 CF_Gway_IDoutWarn "This signal is for ¡°IPM (Gateway)¡± applied vehicles only.";
CM_ SG_ 1363 CF_Gway_ImmoLp "This signal is for ¡°IPM (Gateway)¡± applied vehicles only.";
CM_ SG_ 1363 CF_Gway_BCMRKEID "This signal is for ¡°IPM (Gateway)¡± applied vehicles only.";
CM_ SG_ 1363 CF_Gway_VehicleNotPWarn "This signal is for ¡°IPM (Gateway)¡± applied vehicles only.";
CM_ SG_ 1363 CF_Gway_DeactivationWarn "This signal is for ¡°IPM (Gateway)¡± applied vehicles only.";
CM_ SG_ 1363 CF_Gway_KeyBATDischargeWarn "This signal is for ¡°IPM (Gateway)¡± applied vehicles only.";
CM_ SG_ 1363 CF_Gway_SSBWarn "This signal is for ¡°IPM (Gateway)¡± applied vehicles only.";
CM_ SG_ 1363 CF_Gway_SMKFobID "This signal is for ¡°IPM (Gateway)¡± applied vehicles only.";
CM_ SG_ 1363 CF_Gway_SMKRKECmd "This signal is for ¡°IPM (Gateway)¡± applied vehicles only.";
CM_ SG_ 1363 CF_Gway_WngBuz "This signal is for ¡°IPM (Gateway)¡± applied vehicles only.";
CM_ BO_ 1369 "[PE] Periodic and On Event";
CM_ SG_ 1369 CF_Gway_StaticBendLhAct "This signal is for ¡°IPM (Gateway)¡± applied vehicles only.";
CM_ SG_ 1369 CF_Gway_StaticBendRhAct "This signal is for ¡°IPM (Gateway)¡± applied vehicles only.";
CM_ SG_ 1369 CF_Gway_PBACKStopCmd "-";
CM_ SG_ 1369 CF_Gway_DrvSeatBeltInd "This signal is for ¡°IPM (Gateway)¡± applied vehicles only.";
CM_ SG_ 1369 CF_Gway_AstSeatBeltInd "This signal is for ¡°IPM (Gateway)¡± applied vehicles only.";
CM_ SG_ 1369 CF_Gway_RCSeatBeltInd "This signal is for ¡°IPM (Gateway)¡± applied vehicles only.";
CM_ SG_ 1369 CF_Gway_RLSeatBeltInd "This signal is for ¡°IPM (Gateway)¡± applied vehicles only.";
CM_ SG_ 1369 CF_Gway_RRSeatBeltInd "This signal is for ¡°IPM (Gateway)¡± applied vehicles only.";
CM_ BO_ 127 "[PE] Periodic and On Event";
CM_ BO_ 1472 "[PE] Periodic and On Event";
CM_ BO_ 1427 "[P] Periodic";
CM_ SG_ 1427 TPMS_W_LAMP "-";
CM_ SG_ 1427 TREAD_W_LAMP "-";
CM_ BO_ 1265 "[P] Periodic";
CM_ SG_ 1265 CF_Clu_DetentOut "Detent Status from CLUSTER";
CM_ SG_ 1265 CF_Clu_RheostatLevel "Rheostat Level from CLUSTER";
CM_ SG_ 1265 CF_Clu_AliveCnt1 "In case of Delphi ECU, Output period tolerance(+1ms) will be applied to Engine Lamda3.";
CM_ BO_ 1456 "[P] Periodic";
CM_ BO_ 1397 "[E] On Event";
CM_ BO_ 1395 "[E] On Event";
CM_ BO_ 1370 "[PE] Periodic and On Event";
CM_ BO_ 1490 "[E] On Event";
CM_ BO_ 1491 "[PE] Periodic and On Event";
CM_ BO_ 1407 "[PE] Periodic and On Event";
CM_ BO_ 1492 "[PE] Periodic and On Event";
CM_ BO_ 1411 "[P] Periodic";
CM_ BO_ 899 "[P] Periodic";
CM_ SG_ 899 CF_Fatc_CtrInf "Heater control not using CAN communication for data exchange does not send HVAC compressor type information especially.";
CM_ BO_ 896 "[P] Periodic";
CM_ BO_ 1017 "[P] Periodic";
CM_ BO_ 640 "[P] Periodic";
CM_ SG_ 640 LV_FUEL_TYPE_ECU "1. This signal is for an LPI system only
2. In case of Delphi ECU, Output period tolerance(+1ms) will be applied to Engine Lamda3.";
CM_ SG_ 640 LV_BFS_CFIRM "1. This signal is for an LPI system only
2. In case of Delphi ECU, Output period tolerance(+1ms) will be applied to Engine Lamda3.";
CM_ SG_ 640 LV_CRASH "1. This signal is for an LPI system only
2. In case of Delphi ECU, Output period tolerance(+1ms) will be applied to Engine Lamda3.";
CM_ SG_ 640 LV_VB_OFF_ACT "1. This signal is for an LPI system only
2. In case of Delphi ECU, Output period tolerance(+1ms) will be applied to Engine Lamda3.";
CM_ SG_ 640 LV_GSL_MAP "1. This signal is for an LPI system only
2. In case of Delphi ECU, Output period tolerance(+1ms) will be applied to Engine Lamda3.";
CM_ SG_ 640 LV_ENG_TURN "1. This signal is for an LPI system only
2. In case of Delphi ECU, Output period tolerance(+1ms) will be applied to Engine Lamda3.";
CM_ SG_ 640 ERR_FUEL "1. This signal is for an LPI system only
2. In case of Delphi ECU, Output period tolerance(+1ms) will be applied to Engine Lamda3.";
CM_ SG_ 640 EOS "1. This signal is for an LPI system only
2. In case of Delphi ECU, Output period tolerance(+1ms) will be applied to Engine Lamda3.";
CM_ SG_ 640 TCO "1. This signal is for an LPI system only
2. In case of Delphi ECU, Output period tolerance(+1ms) will be applied to Engine Lamda3.";
CM_ SG_ 640 N_32 "1. This signal is for an LPI system only
2. In case of Delphi ECU, Output period tolerance(+1ms) will be applied to Engine Lamda3.";
CM_ SG_ 640 MAF "1. This signal is for an LPI system only
2. In case of Delphi ECU, Output period tolerance(+1ms) will be applied to Engine Lamda3.";
CM_ SG_ 640 TIA "1. This signal is for an LPI system only
2. In case of Delphi ECU, Output period tolerance(+1ms) will be applied to Engine Lamda3.";
CM_ SG_ 640 MAP "1. This signal is for an LPI system only
2. In case of Delphi ECU, Output period tolerance(+1ms) will be applied to Engine Lamda3.";
CM_ SG_ 640 AMP "1. This signal is for an LPI system only
2. In case of Delphi ECU, Output period tolerance(+1ms) will be applied to Engine Lamda3.";
CM_ BO_ 608 "[P] Periodic";
CM_ SG_ 608 TQI_MIN "In case of Delphi ECU, Output period tolerance(+1ms) will be applied to Engine Lamda3.";
CM_ SG_ 608 TQI "In case of Delphi ECU, Output period tolerance(+1ms) will be applied to Engine Lamda3.";
CM_ SG_ 608 TQI_TARGET "In case of Delphi ECU, Output period tolerance(+1ms) will be applied to Engine Lamda3.";
CM_ SG_ 608 GLOW_STAT "In case of Delphi ECU, Output period tolerance(+1ms) will be applied to Engine Lamda3.";
CM_ SG_ 608 CRUISE_LAMP_M "In case of Delphi ECU, Output period tolerance(+1ms) will be applied to Engine Lamda3.";
CM_ SG_ 608 CRUISE_LAMP_S "In case of Delphi ECU, Output period tolerance(+1ms) will be applied to Engine Lamda3.";
CM_ SG_ 608 PRE_FUEL_CUT_IN "In case of Delphi ECU, Output period tolerance(+1ms) will be applied to Engine Lamda3.";
CM_ SG_ 608 ENG_STAT "In case of Delphi ECU, Output period tolerance(+1ms) will be applied to Engine Lamda3.";
CM_ SG_ 608 SOAK_TIME_ERROR "In case of Delphi ECU, Output period tolerance(+1ms) will be applied to Engine Lamda3.";
CM_ SG_ 608 SOAK_TIME "In case of Delphi ECU, Output period tolerance(+1ms) will be applied to Engine Lamda3.";
CM_ SG_ 608 TQI_MAX "In case of Delphi ECU, Output period tolerance(+1ms) will be applied to Engine Lamda3.";
CM_ SG_ 608 SPK_TIME_CUR "In case of Delphi ECU, Output period tolerance(+1ms) will be applied to Engine Lamda3.";
CM_ SG_ 608 Checksum "In case of Delphi ECU, Output period tolerance(+1ms) will be applied to Engine Lamda3.";
CM_ SG_ 608 AliveCounter "In case of Delphi ECU, Output period tolerance(+1ms) will be applied to Engine Lamda3.";
CM_ SG_ 608 CF_Ems_AclAct "In case of Delphi ECU, Output period tolerance(+1ms) will be applied to Engine Lamda3.";
CM_ BO_ 900 "[P] Periodic";
CM_ SG_ 900 CF_Ems_PkpCurMSV "This signal is for the specific engine system only. (V6/V8 GDI engine only)";
CM_ SG_ 900 CF_Ems_HolCurMSV "This signal is for the specific engine system only. (V6/V8 GDI engine only)";
CM_ SG_ 900 CF_Ems_InjVBnkAct "This signal is for the specific engine system only. (V6/V8 GDI engine only)";
CM_ SG_ 900 CF_Ems_InjVActSet "This signal is for the specific engine system only. (V6/V8 GDI engine only)";
CM_ SG_ 900 CF_Ems_DiagFulHDEV "This signal is for the specific engine system only. (V6/V8 GDI engine only)";
CM_ SG_ 900 CF_Ems_SwiOffIC1 "This signal is for the specific engine system only. (V6/V8 GDI engine only)";
CM_ SG_ 900 CF_Ems_SwiOffIC2 "This signal is for the specific engine system only. (V6/V8 GDI engine only)";
CM_ SG_ 900 CF_Ems_DiagReqHDEV "This signal is for the specific engine system only. (V6/V8 GDI engine only)";
CM_ SG_ 900 CR_Ems_DutyCycMSV "This signal is for the specific engine system only. (V6/V8 GDI engine only)";
CM_ SG_ 900 CR_Ems_BatVolRly "This signal is for the specific engine system only. (V6/V8 GDI engine only)";
CM_ BO_ 1170 "[P] Periodic";
CM_ BO_ 1479 "[P] Periodic";
CM_ SG_ 1479 SCR_LEVEL_WARN_LAMP "SCR Inducement meessage for Passenger car";
CM_ SG_ 1479 SCR_LEVEL_WARN "SCR Inducement meessage for Passenger car";
CM_ SG_ 1479 SCR_SYS_ERROR_WARN "SCR Inducement meessage for Passenger car";
CM_ SG_ 1479 SCR_SYSTEM_WARN_LAMP "SCR Inducement meessage for Passenger car";
CM_ SG_ 1479 SCR_INDUCEMENT_EXIT_COND "SCR Inducement meessage for Passenger car";
CM_ SG_ 1479 SCR_UREA_LEVEL "SCR Inducement meessage for Passenger car";
CM_ SG_ 1479 SCR_NO_REMAINING_RESTARTS "SCR Inducement meessage for Passenger car";
CM_ SG_ 1479 SCR_REMAINING_DISTANCE "SCR Inducement meessage for Passenger car";
CM_ BO_ 128 "[P] Periodic";
CM_ SG_ 128 PV_AV_CAN "This signal is for the ¡°Bosch Gasoline EMS for LuK DCT(Double Clutch T/M)¡± system
applied vehicles only.";
CM_ SG_ 128 TQ_STND "This signal is for the ¡°Bosch Gasoline EMS for LuK DCT(Double Clutch T/M)¡± system
applied vehicles only.";
CM_ SG_ 128 F_N_ENG "This signal is for the ¡°Bosch Gasoline EMS for LuK DCT(Double Clutch T/M)¡± system
applied vehicles only.";
CM_ SG_ 128 F_SUB_TQI "This signal is for the ¡°Bosch Gasoline EMS for LuK DCT(Double Clutch T/M)¡± system
applied vehicles only.";
CM_ SG_ 128 N "This signal is for the ¡°Bosch Gasoline EMS for LuK DCT(Double Clutch T/M)¡± system
applied vehicles only.";
CM_ SG_ 128 TQI_ACOR "This signal is for the ¡°Bosch Gasoline EMS for LuK DCT(Double Clutch T/M)¡± system
applied vehicles only.";
CM_ SG_ 128 TQFR "This signal is for the ¡°Bosch Gasoline EMS for LuK DCT(Double Clutch T/M)¡± system
applied vehicles only.";
CM_ SG_ 128 TQI "This signal is for the ¡°Bosch Gasoline EMS for LuK DCT(Double Clutch T/M)¡± system
applied vehicles only.";
CM_ SG_ 128 CF_Ems_Alive "This signal is for the ¡°Bosch Gasoline EMS for LuK DCT(Double Clutch T/M)¡± system
applied vehicles only.";
CM_ SG_ 128 CF_Ems_ChkSum "This signal is for the ¡°Bosch Gasoline EMS for LuK DCT(Double Clutch T/M)¡± system
applied vehicles only.";
CM_ BO_ 129 "[P] Periodic";
CM_ SG_ 129 CR_Ems_SoakTimeExt "This signal is for the ¡°Bosch Gasoline EMS for LuK DCT(Double Clutch T/M)¡± system
applied vehicles only.";
CM_ SG_ 129 BRAKE_ACT "This signal is for the ¡°Bosch Gasoline EMS for LuK DCT(Double Clutch T/M)¡± system
applied vehicles only.";
CM_ SG_ 129 CF_Ems_EngOperStat "1. This signal is for the ¡°Bosch Gasoline EMS for LuK DCT(Double Clutch T/M)¡± system
applied vehicles only.
2. This signa is same as EOS in EMS3 message.";
CM_ SG_ 129 CR_Ems_IndAirTemp "1. This signal is for the ¡°Bosch Gasoline EMS for LuK DCT(Double Clutch T/M)¡± system
applied vehicles only.
2. This signal is same as TIA in EMS3 message.";
CM_ SG_ 129 CF_Ems_Alive2 "This signal is for the ¡°Bosch Gasoline EMS for LuK DCT(Double Clutch T/M)¡± system
applied vehicles only.";
CM_ SG_ 129 CF_Ems_ChkSum2 "This signal is for the ¡°Bosch Gasoline EMS for LuK DCT(Double Clutch T/M)¡± system
applied vehicles only.";
CM_ BO_ 399 "[P] Periodic";
CM_ SG_ 399 R_TqAcnApvC "In case of Delphi ECU, Output period tolerance(+1ms) will be applied to Engine Lamda3.";
CM_ SG_ 399 R_PAcnC "In case of Delphi ECU, Output period tolerance(+1ms) will be applied to Engine Lamda3.";
CM_ SG_ 399 TQI_B "In case of Delphi ECU, Output period tolerance(+1ms) will be applied to Engine Lamda3.";
CM_ SG_ 399 SLD_VS "In case of Delphi ECU, Output period tolerance(+1ms) will be applied to Engine Lamda3.";
CM_ SG_ 399 CF_CdaStat "In case of Delphi ECU, Output period tolerance(+1ms) will be applied to Engine Lamda3.";
CM_ SG_ 399 CF_Ems_IsgStat "In case of Delphi ECU, Output period tolerance(+1ms) will be applied to Engine Lamda3.";
CM_ SG_ 399 CF_Ems_OilChg "In case of Delphi ECU, Output period tolerance(+1ms) will be applied to Engine Lamda3.";
CM_ SG_ 399 CF_Ems_EtcLimpMod "In case of Delphi ECU, Output period tolerance(+1ms) will be applied to Engine Lamda3.";
CM_ SG_ 399 R_NEngIdlTgC "In case of Delphi ECU, Output period tolerance(+1ms) will be applied to Engine Lamda3.";
CM_ SG_ 399 CF_Ems_UpTarGr "In case of Delphi ECU, Output period tolerance(+1ms) will be applied to Engine Lamda3.";
CM_ SG_ 399 CF_Ems_DownTarGr "In case of Delphi ECU, Output period tolerance(+1ms) will be applied to Engine Lamda3.";
CM_ SG_ 399 CF_Ems_DesCurGr "In case of Delphi ECU, Output period tolerance(+1ms) will be applied to Engine Lamda3.";
CM_ SG_ 399 CF_Ems_SldAct "In case of Delphi ECU, Output period tolerance(+1ms) will be applied to Engine Lamda3.";
CM_ SG_ 399 CF_Ems_SldPosAct "In case of Delphi ECU, Output period tolerance(+1ms) will be applied to Engine Lamda3.";
CM_ SG_ 399 CF_Ems_HPresStat "In case of Delphi ECU, Output period tolerance(+1ms) will be applied to Engine Lamda3.";
CM_ SG_ 399 CF_Ems_IsgBuz "In case of Delphi ECU, Output period tolerance(+1ms) will be applied to Engine Lamda3.";
CM_ SG_ 399 CF_Ems_IdlStpFCO "In case of Delphi ECU, Output period tolerance(+1ms) will be applied to Engine Lamda3.";
CM_ SG_ 399 CF_Ems_FCopen "In case of Delphi ECU, Output period tolerance(+1ms) will be applied to Engine Lamda3.";
CM_ SG_ 399 CF_Ems_ActEcoAct "In case of Delphi ECU, Output period tolerance(+1ms) will be applied to Engine Lamda3.";
CM_ SG_ 399 CF_Ems_EngRunNorm "In case of Delphi ECU, Output period tolerance(+1ms) will be applied to Engine Lamda3.";
CM_ SG_ 399 CF_Ems_IsgStat2 "In case of Delphi ECU, Output period tolerance(+1ms) will be applied to Engine Lamda3.";
CM_ BO_ 1366 "[P] Periodic";
CM_ SG_ 1366 PID_04h "See PID 43h of SAE J1979 for an additional definition of engine load";
CM_ SG_ 1366 PID_11h "See PID 45h of SAE J1979 for a definition of Relative Throttle Position";
CM_ SG_ 1366 PID_03h "Fuel systems do not normally refer to injector banks. Fuel systems are intended to represent completely different fuel systems that can independently enter and exit closed loop fuel. Banks of injectors on a V-engine are generally not independent and share";
CM_ BO_ 1367 "[P] Periodic";
CM_ BO_ 1168 "[P] Periodic";
CM_ BO_ 1984 "[E] On Event";
CM_ BO_ 1151 "[P] Periodic";
CM_ SG_ 1151 AVH_STAT "This message is for ¡°EPB (Electric Parking Brake)¡± system applied vehicle only.";
CM_ SG_ 1151 LDM_STAT "This message is for ¡°EPB (Electric Parking Brake)¡± system applied vehicle only.";
CM_ SG_ 1151 REQ_EPB_ACT "This message is for ¡°EPB (Electric Parking Brake)¡± system applied vehicle only.";
CM_ SG_ 1151 REQ_EPB_STAT "This message is for ¡°EPB (Electric Parking Brake)¡± system applied vehicle only.";
CM_ SG_ 1151 ECD_ACT "This message is for ¡°EPB (Electric Parking Brake)¡± system applied vehicle only.";
CM_ SG_ 1151 _4WD_LIM_REQ "This signal is for MANDO TCS/ESC system only.";
CM_ SG_ 1151 ROL_CNT_ESP "This message is for ¡°EPB (Electric Parking Brake)¡± system applied vehicle only.";
CM_ BO_ 915 "[P] Periodic";
CM_ SG_ 915 SA_COUNT "This signal is for the Non-CAN Type Streering Angle Sensor ONLY.";
CM_ SG_ 915 SA_Z_COUNT "This signal is for the Non-CAN Type Streering Angle Sensor ONLY.";
CM_ SG_ 915 SA_Z_FLAG "This signal is for the Non-CAN Type Streering Angle Sensor ONLY.";
CM_ BO_ 916 "[P] Periodic";
CM_ BO_ 356 "[P] Periodic";
CM_ SG_ 356 CR_Esc_StrTqReq "(PH) > 0 : Left Direction (CCW)
(PH) < 0 : Right Direction (CW)";
CM_ BO_ 1414 "[P] Periodic";
CM_ SG_ 1414 CF_Evp_Stat "this signal is only for case which the warning lamp is illuminated when the EVP is defective";
CM_ BO_ 1365 "[P] Periodic";
CM_ BO_ 1378 "[P] Periodic";
CM_ SG_ 1378 CF_Hud_PBackStatus "This signal is for HUD interoperation with IMS";
CM_ BO_ 1415 "[P] Periodic";
CM_ BO_ 1419 "[P] Periodic";
CM_ SG_ 1419 CF_SndWarnForClu ".";
CM_ BO_ 625 "[P] Periodic";
CM_ SG_ 625 LPI_OBD "The exact meaning of this signal and conditions that this signal is used have to be defined by the LPI interface box supplier (in accordance with the OBD regulations).";
CM_ BO_ 852 "[P] Periodic";
CM_ SG_ 852 CF_Lvr_GearInf "In case of DCT(Double Clutch T/M) system, LVR11 message don't be used. LVR_DCT must be used.";
CM_ SG_ 852 CF_Lvr_PRelStat "In case of DCT(Double Clutch T/M) system, LVR11 message don't be used. LVR_DCT must be used.";
CM_ SG_ 852 CF_Lvr_BkeAct "In case of DCT(Double Clutch T/M) system, LVR11 message don't be used. LVR_DCT must be used.";
CM_ SG_ 852 CF_Lvr_NFnStat "In case of DCT(Double Clutch T/M) system, LVR11 message don't be used. LVR_DCT must be used.";
CM_ SG_ 852 CF_Lvr_PosInf "In case of DCT(Double Clutch T/M) system, LVR11 message don't be used. LVR_DCT must be used.";
CM_ SG_ 852 CF_Lvr_PosCpl "In case of DCT(Double Clutch T/M) system, LVR11 message don't be used. LVR_DCT must be used.";
CM_ SG_ 852 CF_Lvr_UlkButStat "In case of DCT(Double Clutch T/M) system, LVR11 message don't be used. LVR_DCT must be used.";
CM_ SG_ 852 CF_Lvr_PNStat "In case of DCT(Double Clutch T/M) system, LVR11 message don't be used. LVR_DCT must be used.";
CM_ SG_ 852 CF_Lvr_ShtLkStat "In case of DCT(Double Clutch T/M) system, LVR11 message don't be used. LVR_DCT must be used.";
CM_ SG_ 852 CF_Lvr_ShfErrInf "In case of DCT(Double Clutch T/M) system, LVR11 message don't be used. LVR_DCT must be used.";
CM_ SG_ 852 CF_Lvr_AC "In case of DCT(Double Clutch T/M) system, LVR11 message don't be used. LVR_DCT must be used.";
CM_ SG_ 852 CF_Lvr_CS "In case of DCT(Double Clutch T/M) system, LVR11 message don't be used. LVR_DCT must be used.";
CM_ BO_ 897 "[P] Periodic";
CM_ SG_ 897 CF_Mdps_Flex "To broadcast MDPS steering support mode";
CM_ SG_ 897 CF_Mdps_Stat "This message is for the ¡°SPAS(Smart Parking Assist System)¡± applied vehicles only";
CM_ SG_ 897 CR_Mdps_DrvTq "This message is for the ¡°SPAS(Smart Parking Assist System)¡± applied vehicles only";
CM_ SG_ 897 CR_Mdps_StrAng "This message is for the ¡°SPAS(Smart Parking Assist System)¡± applied vehicles only";
CM_ SG_ 897 CF_Mdps_AliveCnt "This message is for the ¡°SPAS(Smart Parking Assist System)¡± applied vehicles only";
CM_ SG_ 897 CF_Mdps_Chksum "This message is for the ¡°SPAS(Smart Parking Assist System)¡± applied vehicles only";
CM_ SG_ 897 CF_Mdps_SPAS_FUNC "-";
CM_ SG_ 897 CF_Mdps_LKAS_FUNC "-";
CM_ SG_ 897 CF_Mdps_CurrMode "To broadcast MDPS steering support mode";
CM_ BO_ 688 "[P] Periodic";
CM_ SG_ 688 SAS_Angle "When MDPS ECU sends this message, this message value is valid 1.5 sec later from IG-ON.";
CM_ SG_ 688 SAS_Speed "When MDPS ECU sends this message, this message value is valid 1.5 sec later from IG-ON.";
CM_ SG_ 688 SAS_Stat "When MDPS ECU sends this message, this message value is valid 1.5 sec later from IG-ON.";
CM_ SG_ 688 MsgCount "When MDPS ECU sends this message, this message value is valid 1.5 sec later from IG-ON.";
CM_ SG_ 688 CheckSum "When MDPS ECU sends this message, this message value is valid 1.5 sec later from IG-ON.";
CM_ BO_ 1530 "[P] Periodic";
CM_ BO_ 1531 "[P] Periodic";
CM_ SG_ 1531 CR_Ods_SerNum0 "Output period : 1000 ms until ODS_ID_Received_Flag is set to 1 in ACU1 message";
CM_ SG_ 1531 CR_Ods_SerNum1 "Output period : 1000 ms until ODS_ID_Received_Flag is set to 1 in ACU1 message";
CM_ SG_ 1531 CR_Ods_SerNum2 "Output period : 1000 ms until ODS_ID_Received_Flag is set to 1 in ACU1 message";
CM_ SG_ 1531 CR_Ods_SerNum3 "Output period : 1000 ms until ODS_ID_Received_Flag is set to 1 in ACU1 message";
CM_ SG_ 1531 CR_Ods_SerNum4 "Output period : 1000 ms until ODS_ID_Received_Flag is set to 1 in ACU1 message";
CM_ SG_ 1531 CR_Ods_SerNum5 "Output period : 1000 ms until ODS_ID_Received_Flag is set to 1 in ACU1 message";
CM_ SG_ 1531 CR_Ods_SerNum6 "Output period : 1000 ms until ODS_ID_Received_Flag is set to 1 in ACU1 message";
CM_ SG_ 1531 CR_Ods_SerNum7 "Output period : 1000 ms until ODS_ID_Received_Flag is set to 1 in ACU1 message";
CM_ BO_ 1532 "[P] Periodic";
CM_ SG_ 1532 CR_Ods_ID "Output period : 1000 ms until ODS_ID_Received_Flag is set to 1 in ACU1 message";
CM_ SG_ 1532 CR_Ods_Chksum_H "Output period : 1000 ms until ODS_ID_Received_Flag is set to 1 in ACU1 message";
CM_ SG_ 1532 CR_Ods_Chksum_L "Output period : 1000 ms until ODS_ID_Received_Flag is set to 1 in ACU1 message";
CM_ SG_ 1532 CR_Ods_RomID_H "Output period : 1000 ms until ODS_ID_Received_Flag is set to 1 in ACU1 message";
CM_ SG_ 1532 CR_Ods_RomID_L "Output period : 1000 ms until ODS_ID_Received_Flag is set to 1 in ACU1 message";
CM_ BO_ 1393 "[P] Periodic";
CM_ SG_ 1393 CF_Opi_Romver "Value Table is provided to HMC by Continetal for each SW version.";
CM_ BO_ 1379 "[PE] Periodic and On Event";
CM_ BO_ 1434 "[P] Periodic";
CM_ BO_ 387 "[P] Periodic";
CM_ BO_ 912 "[P] Periodic";
CM_ SG_ 912 CF_Spas_Stat "This signal is for the ¡°SPAS(Smart Parking Assist System)¡± applied vehicles only.";
CM_ SG_ 912 CR_Spas_StrAngCmd "This signal is for the ¡°SPAS(Smart Parking Assist System)¡± applied vehicles only.";
CM_ SG_ 912 CF_Spas_AliveCnt "This signal is for the ¡°SPAS(Smart Parking Assist System)¡± applied vehicles only.";
CM_ SG_ 912 CF_Spas_Chksum "This signal is for the ¡°SPAS(Smart Parking Assist System)¡± applied vehicles only.";
CM_ BO_ 1268 "[P] Periodic";
CM_ BO_ 354 "[P] Periodic";
CM_ SG_ 354 Cluster_Engine_RPM "Engine RPM only for the display on Cluster";
BA_DEF_ SG_ "GenSigEnvVarType" ENUM "Int","Float","Undef" ;
BA_DEF_ SG_ "GenSigEVName" STRING ;
BA_DEF_ SG_ "GenSigInactiveValue" INT 0 65535 ;
BA_DEF_ SG_ "GenSigSendType" ENUM "Cyclic","OnWrite","OnWriteWithRepetition","OnChange","OnChangeWithRepetition","IfActive","IfActiveWithRepetition","NoSigSendType" ;
BA_DEF_ SG_ "GenSigStartValue" INT 0 1215752192 ;
BA_DEF_ SG_ "GwSigLatencyTime" INT 0 65535 ;
BA_DEF_ SG_ "GwSigMissingSourceType" ENUM "Undef","OldValue","DefaultValue","InitialValue" ;
BA_DEF_ SG_ "SignalCategory" HEX 10 15 ;
BA_DEF_ BO_ "GenMsgCycleTime" INT 0 2000 ;
BA_DEF_ BO_ "GenMsgCycleTimeFast" INT 0 500 ;
BA_DEF_ BO_ "GenMsgDelayTime" INT 0 20 ;
BA_DEF_ BO_ "GenMsgILSupport" ENUM "No","Yes" ;
BA_DEF_ BO_ "GenMsgNrOfRepetition" INT 0 3 ;
BA_DEF_ BO_ "GenMsgSendType" ENUM "Cyclic","not_used","not_used","not_used","not_used","not_used","not_used","not_used","NoMsgSendType" ;
BA_DEF_ BO_ "GenMsgStartDelayTime" INT 0 2000 ;
BA_DEF_ BU_ "GenNodSleepTime" INT 1375 1650 ;
BA_DEF_ BU_ "ILUsed" ENUM "No","Yes" ;
BA_DEF_ BU_ "NmCAN" INT 1 2 ;
BA_DEF_ BU_ "NmStationAddress" HEX 0 255 ;
BA_DEF_ BU_ "NodeLayerModules" STRING ;
BA_DEF_ "Baudrate" INT 50000 1000000 ;
BA_DEF_ "BusType" STRING ;
BA_DEF_ "GenEnvVarEndingDsp" STRING ;
BA_DEF_ "GenEnvVarEndingSnd" STRING ;
BA_DEF_ "GenEnvVarPrefix" STRING ;
BA_DEF_ "GenNWMApBusSleep" STRING ;
BA_DEF_ "GenNWMApCanNormal" STRING ;
BA_DEF_ "GenNWMApCanOff" STRING ;
BA_DEF_ "GenNWMApCanOn" STRING ;
BA_DEF_ "GenNWMApCanSleep" STRING ;
BA_DEF_ "GenNWMApCanWakeUp" STRING ;
BA_DEF_ "GenNWMGotoMode_Awake" STRING ;
BA_DEF_ "GenNWMGotoMode_BusSleep" STRING ;
BA_DEF_ "GenNWMSleepTime" INT 1375 1650 ;
BA_DEF_ "GenNWMTalkNM" STRING ;
BA_DEF_ "Manufacturer" STRING ;
BA_DEF_ "NmBaseAddress" HEX 0 2047 ;
BA_DEF_ "NmMessageCount" INT 0 128 ;
BA_DEF_ "NmType" STRING ;
BA_DEF_ "SamplePointMax" INT 50 85 ;
BA_DEF_ "SamplePointMin" INT 55 85 ;
BA_DEF_ "SyncJumpWidthMax" INT 1 8 ;
BA_DEF_ "SyncJumpWidthMin" INT 1 4 ;
BA_DEF_ "VersionDay" INT 1 31 ;
BA_DEF_ "VersionMonth" INT 1 12 ;
BA_DEF_ "VersionWeek" INT 1 53 ;
BA_DEF_ "VersionYear" INT 0 9999 ;
BA_DEF_REL_ BU_SG_REL_ "GenSigTimeoutTime" INT 0 7000 ;
BA_DEF_DEF_ "GenSigEnvVarType" "Undef" ;
BA_DEF_DEF_ "GenSigEVName" "@Signame" ;
BA_DEF_DEF_ "GenSigInactiveValue" 0 ;
BA_DEF_DEF_ "GenSigSendType" "NoSigSendType" ;
BA_DEF_DEF_ "GenSigStartValue" 0 ;
BA_DEF_DEF_ "GwSigLatencyTime" 40 ;
BA_DEF_DEF_ "GwSigMissingSourceType" "Undef" ;
BA_DEF_DEF_ "SignalCategory" 12 ;
BA_DEF_DEF_ "GenMsgCycleTime" 10 ;
BA_DEF_DEF_ "GenMsgCycleTimeFast" 40 ;
BA_DEF_DEF_ "GenMsgDelayTime" 20 ;
BA_DEF_DEF_ "GenMsgILSupport" "Yes" ;
BA_DEF_DEF_ "GenMsgNrOfRepetition" 0 ;
BA_DEF_DEF_ "GenMsgSendType" "Cyclic" ;
BA_DEF_DEF_ "GenMsgStartDelayTime" 0 ;
BA_DEF_DEF_ "GenNodSleepTime" 1500 ;
BA_DEF_DEF_ "ILUsed" "Yes" ;
BA_DEF_DEF_ "NmCAN" 1 ;
BA_DEF_DEF_ "NmStationAddress" 0 ;
BA_DEF_DEF_ "NodeLayerModules" "oseknm01.dll" ;
BA_DEF_DEF_ "Baudrate" 500000 ;
BA_DEF_DEF_ "BusType" "CAN" ;
BA_DEF_DEF_ "GenEnvVarEndingDsp" "Dsp_" ;
BA_DEF_DEF_ "GenEnvVarEndingSnd" "_" ;
BA_DEF_DEF_ "GenEnvVarPrefix" "Env" ;
BA_DEF_DEF_ "GenNWMApBusSleep" "ApplNmCanBusSleep()" ;
BA_DEF_DEF_ "GenNWMApCanNormal" "ApplNmCanNormal()" ;
BA_DEF_DEF_ "GenNWMApCanOff" "ApplCanOffline()" ;
BA_DEF_DEF_ "GenNWMApCanOn" "ApplCanOnline()" ;
BA_DEF_DEF_ "GenNWMApCanSleep" "ApplNmCanSleep()" ;
BA_DEF_DEF_ "GenNWMApCanWakeUp" "ApplCanWakeUp()" ;
BA_DEF_DEF_ "GenNWMGotoMode_Awake" "GotoMode_Awake()" ;
BA_DEF_DEF_ "GenNWMGotoMode_BusSleep" "GotoMode_BusSleep()" ;
BA_DEF_DEF_ "GenNWMSleepTime" 1500 ;
BA_DEF_DEF_ "GenNWMTalkNM" "TalkNM()" ;
BA_DEF_DEF_ "Manufacturer" "HMC" ;
BA_DEF_DEF_ "NmBaseAddress" 1024 ;
BA_DEF_DEF_ "NmMessageCount" 128 ;
BA_DEF_DEF_ "NmType" "Vector" ;
BA_DEF_DEF_ "SamplePointMax" 82 ;
BA_DEF_DEF_ "SamplePointMin" 75 ;
BA_DEF_DEF_ "SyncJumpWidthMax" 3 ;
BA_DEF_DEF_ "SyncJumpWidthMin" 2 ;
BA_DEF_DEF_ "VersionDay" 1 ;
BA_DEF_DEF_ "VersionMonth" 1 ;
BA_DEF_DEF_ "VersionWeek" 1 ;
BA_DEF_DEF_ "VersionYear" 2010 ;
BA_DEF_DEF_REL_ "GenSigTimeoutTime" 500 ;
BA_ "GenMsgCycleTime" BO_ 1412 100;
BA_REL_ "GenSigTimeoutTime" BU_SG_REL_ AAF_Tester SG_ 1412 CF_Aaf_ActFlapStatus 1000;
BA_ "GenSigStartValue" SG_ 1412 CF_Aaf_ActFlapStatus 1;
BA_REL_ "GenSigTimeoutTime" BU_SG_REL_ AAF_Tester SG_ 1412 CF_Aaf_ModeStatus 1000;
BA_REL_ "GenSigTimeoutTime" BU_SG_REL_ CLU SG_ 1412 CF_Aaf_WrnLamp 1000;
BA_REL_ "GenSigTimeoutTime" BU_SG_REL_ AAF_Tester SG_ 1412 CF_Aaf_ErrStatus 1000;
BA_REL_ "GenSigTimeoutTime" BU_SG_REL_ EMS SG_ 1412 CF_Aaf_ErrStatus 1000;
BA_REL_ "GenSigTimeoutTime" BU_SG_REL_ AAF_Tester SG_ 1412 CF_Aaf_OpenRqSysAct 1000;
BA_REL_ "GenSigTimeoutTime" BU_SG_REL_ AAF_Tester SG_ 1412 CF_Aaf_PStatus 1000;
BA_REL_ "GenSigTimeoutTime" BU_SG_REL_ AAF_Tester SG_ 1412 CF_Aaf_OpenRqSysSol 1000;
BA_REL_ "GenSigTimeoutTime" BU_SG_REL_ AAF_Tester SG_ 1412 CF_Aaf_SolFlapStatus 1000;
BA_ "GenSigStartValue" SG_ 1412 CF_Aaf_SolFlapStatus 1;
BA_REL_ "GenSigTimeoutTime" BU_SG_REL_ EMS SG_ 1412 CF_Aaf_MilOnReq 1000;
BA_ "GenMsgCycleTime" BO_ 906 20;
BA_ "GenMsgCycleTime" BO_ 903 20;
BA_ "GenMsgCycleTime" BO_ 902 20;
BA_ "GenMsgCycleTime" BO_ 1440 1000;
BA_REL_ "GenSigTimeoutTime" BU_SG_REL_ ODS SG_ 1440 CF_Ods_SNRcv 5000;
BA_REL_ "GenSigTimeoutTime" BU_SG_REL_ ODS SG_ 1440 CF_Ods_IDRcv 5000;
BA_REL_ "GenSigTimeoutTime" BU_SG_REL_ ODS SG_ 1440 CF_Ods_RZReq 5000;
BA_REL_ "GenSigTimeoutTime" BU_SG_REL_ ODS SG_ 1440 CF_Abg_DepInhEnt 5000;
BA_REL_ "GenSigTimeoutTime" BU_SG_REL_ ODS SG_ 1440 CF_Abg_DepEnt 5000;
BA_REL_ "GenSigTimeoutTime" BU_SG_REL_ ODS SG_ 1440 CF_PasBkl_FltStat 5000;
BA_REL_ "GenSigTimeoutTime" BU_SG_REL_ PSB SG_ 1440 CF_PasBkl_FltStat 5000;
BA_REL_ "GenSigTimeoutTime" BU_SG_REL_ ODS SG_ 1440 CF_DriBkl_FltStat 5000;
BA_REL_ "GenSigTimeoutTime" BU_SG_REL_ PSB SG_ 1440 CF_DriBkl_FltStat 5000;
BA_REL_ "GenSigTimeoutTime" BU_SG_REL_ IBOX SG_ 1440 CF_PasBkl_Stat 5000;
BA_REL_ "GenSigTimeoutTime" BU_SG_REL_ ODS SG_ 1440 CF_PasBkl_Stat 5000;
BA_REL_ "GenSigTimeoutTime" BU_SG_REL_ PSB SG_ 1440 CF_PasBkl_Stat 5000;
BA_REL_ "GenSigTimeoutTime" BU_SG_REL_ TMU SG_ 1440 CF_PasBkl_Stat 5000;
BA_REL_ "GenSigTimeoutTime" BU_SG_REL_ ODS SG_ 1440 CF_DriBkl_Stat 5000;
BA_REL_ "GenSigTimeoutTime" BU_SG_REL_ PSB SG_ 1440 CF_DriBkl_Stat 5000;
BA_REL_ "GenSigTimeoutTime" BU_SG_REL_ CUBIS SG_ 1440 CF_SWL_Ind 5000;
BA_REL_ "GenSigTimeoutTime" BU_SG_REL_ IBOX SG_ 1440 CF_SWL_Ind 5000;
BA_REL_ "GenSigTimeoutTime" BU_SG_REL_ CUBIS SG_ 1440 CF_Acu_FltStat 5000;
BA_REL_ "GenSigTimeoutTime" BU_SG_REL_ IBOX SG_ 1440 CF_Acu_FltStat 5000;
BA_REL_ "GenSigTimeoutTime" BU_SG_REL_ BCM SG_ 1440 CF_Acu_ExtOfSab 5000;
BA_REL_ "GenSigTimeoutTime" BU_SG_REL_ CLU SG_ 1440 CF_Acu_ExtOfSab 5000;
BA_REL_ "GenSigTimeoutTime" BU_SG_REL_ CUBIS SG_ 1440 CF_Acu_ExtOfSab 5000;
BA_REL_ "GenSigTimeoutTime" BU_SG_REL_ IBOX SG_ 1440 CF_Acu_ExtOfSab 5000;
BA_ "GenSigStartValue" SG_ 1440 CF_Acu_ExtOfSab 1;
BA_REL_ "GenSigTimeoutTime" BU_SG_REL_ CUBIS SG_ 1440 CF_Acu_Dtc 5000;
BA_REL_ "GenSigTimeoutTime" BU_SG_REL_ IBOX SG_ 1440 CF_Acu_Dtc 5000;
BA_REL_ "GenSigTimeoutTime" BU_SG_REL_ CUBIS SG_ 1440 CF_Acu_NumOfFlt 5000;
BA_REL_ "GenSigTimeoutTime" BU_SG_REL_ IBOX SG_ 1440 CF_Acu_NumOfFlt 5000;
BA_ "GenMsgCycleTime" BO_ 1441 1000;
BA_REL_ "GenSigTimeoutTime" BU_SG_REL_ ODS SG_ 1441 CR_Acu_SN 5000;
BA_ "GenMsgCycleTime" BO_ 1425 100;
BA_REL_ "GenSigTimeoutTime" BU_SG_REL_ CLU SG_ 1425 AFLS_STAT 1000;
BA_REL_ "GenSigTimeoutTime" BU_SG_REL_ CLU SG_ 1425 CF_Afls_TrfChgStat 1000;
BA_REL_ "GenSigTimeoutTime" BU_SG_REL_ CLU SG_ 1425 CF_Afls_LedHLStat 1000;
BA_ "GenMsgCycleTime" BO_ 1437 300;
BA_REL_ "GenSigTimeoutTime" BU_SG_REL_ CLU SG_ 1437 CF_Ahls_WarnLamp 1500;
BA_REL_ "GenSigTimeoutTime" BU_SG_REL_ CLU SG_ 1437 CF_Ahls_WarnMsg 1500;
BA_ "GenMsgCycleTime" BO_ 1371 600;
BA_ "GenMsgNrOfRepetition" BO_ 1371 3;
BA_REL_ "GenSigTimeoutTime" BU_SG_REL_ CLU SG_ 1371 AVM_View 2100;
BA_ "GenSigSendType" SG_ 1371 AVM_View 4;
BA_ "GenSigStartValue" SG_ 1371 AVM_View 31;
BA_REL_ "GenSigTimeoutTime" BU_SG_REL_ CLU SG_ 1371 AVM_ParkingAssist_BtnSts 2100;
BA_ "GenSigSendType" SG_ 1371 AVM_ParkingAssist_BtnSts 4;
BA_ "GenSigStartValue" SG_ 1371 AVM_ParkingAssist_BtnSts 7;
BA_REL_ "GenSigTimeoutTime" BU_SG_REL_ CLU SG_ 1371 AVM_Display_Message 2100;
BA_ "GenSigSendType" SG_ 1371 AVM_Display_Message 4;
BA_ "GenSigStartValue" SG_ 1371 AVM_Display_Message 255;
BA_REL_ "GenSigTimeoutTime" BU_SG_REL_ CLU SG_ 1371 AVM_Popup_Msg 2100;
BA_ "GenSigSendType" SG_ 1371 AVM_Popup_Msg 4;
BA_ "GenSigStartValue" SG_ 1371 AVM_Popup_Msg 15;
BA_REL_ "GenSigTimeoutTime" BU_SG_REL_ CLU SG_ 1371 AVM_Ready 2100;
BA_ "GenSigSendType" SG_ 1371 AVM_Ready 4;
BA_ "GenSigStartValue" SG_ 1371 AVM_Ready 15;
BA_REL_ "GenSigTimeoutTime" BU_SG_REL_ CLU SG_ 1371 AVM_ParkingAssist_Step 2100;
BA_ "GenSigSendType" SG_ 1371 AVM_ParkingAssist_Step 4;
BA_ "GenSigStartValue" SG_ 1371 AVM_ParkingAssist_Step 15;
BA_REL_ "GenSigTimeoutTime" BU_SG_REL_ CLU SG_ 1371 AVM_FrontBtn_Type 2100;
BA_ "GenSigSendType" SG_ 1371 AVM_FrontBtn_Type 4;
BA_ "GenSigStartValue" SG_ 1371 AVM_FrontBtn_Type 1;
BA_REL_ "GenSigTimeoutTime" BU_SG_REL_ CLU SG_ 1371 AVM_Option 2100;
BA_ "GenSigSendType" SG_ 1371 AVM_Option 4;
BA_ "GenSigStartValue" SG_ 1371 AVM_Option 15;
BA_REL_ "GenSigTimeoutTime" BU_SG_REL_ CLU SG_ 1371 AVM_HU_FrontViewPointOpt 2100;
BA_ "GenSigSendType" SG_ 1371 AVM_HU_FrontViewPointOpt 4;
BA_ "GenSigStartValue" SG_ 1371 AVM_HU_FrontViewPointOpt 15;
BA_REL_ "GenSigTimeoutTime" BU_SG_REL_ CLU SG_ 1371 AVM_HU_RearView_Option 2100;
BA_ "GenSigSendType" SG_ 1371 AVM_HU_RearView_Option 4;
BA_ "GenSigStartValue" SG_ 1371 AVM_HU_RearView_Option 15;
BA_REL_ "GenSigTimeoutTime" BU_SG_REL_ CLU SG_ 1371 AVM_HU_FrontView_Option 2100;
BA_ "GenSigSendType" SG_ 1371 AVM_HU_FrontView_Option 4;
BA_ "GenSigStartValue" SG_ 1371 AVM_HU_FrontView_Option 15;
BA_REL_ "GenSigTimeoutTime" BU_SG_REL_ CLU SG_ 1371 AVM_Version 2100;
BA_ "GenSigSendType" SG_ 1371 AVM_Version 4;
BA_ "GenSigStartValue" SG_ 1371 AVM_Version 65535;
BA_ "GenMsgCycleTime" BO_ 1363 200;
BA_ "GenMsgNrOfRepetition" BO_ 1363 3;
BA_REL_ "GenSigTimeoutTime" BU_SG_REL_ CLU SG_ 1363 CF_Gway_GwayDiagState 1000;
BA_ "GenSigSendType" SG_ 1363 CF_Gway_GwayDiagState 4;
BA_ "GenSigSendType" SG_ 1363 CF_Gway_DDMDiagState 4;
BA_ "GenSigSendType" SG_ 1363 CF_Gway_SCMDiagState 4;
BA_ "GenSigSendType" SG_ 1363 CF_Gway_PSMDiagState 4;
BA_ "GenSigSendType" SG_ 1363 CF_Gway_SJBDiagState 4;
BA_ "GenSigSendType" SG_ 1363 CF_Gway_IPMDiagState 4;
BA_ "GenSigSendType" SG_ 1363 CF_Gway_LDMFail 4;
BA_REL_ "GenSigTimeoutTime" BU_SG_REL_ CLU SG_ 1363 CF_Gway_CLUSwGuiCtrl 1000;
BA_ "GenSigSendType" SG_ 1363 CF_Gway_CLUSwGuiCtrl 4;
BA_REL_ "GenSigTimeoutTime" BU_SG_REL_ CLU SG_ 1363 CF_Gway_CLUSwGroup 1000;
BA_ "GenSigSendType" SG_ 1363 CF_Gway_CLUSwGroup 4;
BA_REL_ "GenSigTimeoutTime" BU_SG_REL_ CLU SG_ 1363 CF_Gway_CLUSwMode 1000;
BA_ "GenSigSendType" SG_ 1363 CF_Gway_CLUSwMode 4;
BA_REL_ "GenSigTimeoutTime" BU_SG_REL_ CLU SG_ 1363 CF_Gway_CLUSwEnter 1000;
BA_ "GenSigSendType" SG_ 1363 CF_Gway_CLUSwEnter 4;
BA_ "GenSigSendType" SG_ 1363 CF_Gway_AutoLightValue 4;
BA_ "GenSigSendType" SG_ 1363 CF_Gway_BrakeFluidSw 4;
BA_REL_ "GenSigTimeoutTime" BU_SG_REL_ CLU SG_ 1363 CF_Gway_DrvSeatBeltInd 1000;
BA_ "GenSigSendType" SG_ 1363 CF_Gway_DrvSeatBeltInd 4;
BA_REL_ "GenSigTimeoutTime" BU_SG_REL_ CLU SG_ 1363 CF_Gway_AvTail 1000;
BA_REL_ "GenSigTimeoutTime" BU_SG_REL_ SNV SG_ 1363 CF_Gway_AvTail 1000;
BA_ "GenSigSendType" SG_ 1363 CF_Gway_AvTail 4;
BA_REL_ "GenSigTimeoutTime" BU_SG_REL_ CLU SG_ 1363 CF_Gway_RearFogAct 1000;
BA_ "GenSigSendType" SG_ 1363 CF_Gway_RearFogAct 4;
BA_REL_ "GenSigTimeoutTime" BU_SG_REL_ AVM SG_ 1363 CF_Gway_ExtTailAct 1000;
BA_REL_ "GenSigTimeoutTime" BU_SG_REL_ CLU SG_ 1363 CF_Gway_ExtTailAct 1000;
BA_REL_ "GenSigTimeoutTime" BU_SG_REL_ LCA SG_ 1363 CF_Gway_ExtTailAct 1000;
BA_REL_ "GenSigTimeoutTime" BU_SG_REL_ PGS SG_ 1363 CF_Gway_ExtTailAct 1000;
BA_REL_ "GenSigTimeoutTime" BU_SG_REL_ SPAS SG_ 1363 CF_Gway_ExtTailAct 1000;
BA_ "GenSigSendType" SG_ 1363 CF_Gway_ExtTailAct 4;
BA_REL_ "GenSigTimeoutTime" BU_SG_REL_ CLU SG_ 1363 CF_Gway_RRDrSw 1000;
BA_ "GenSigSendType" SG_ 1363 CF_Gway_RRDrSw 4;
BA_REL_ "GenSigTimeoutTime" BU_SG_REL_ CLU SG_ 1363 CF_Gway_RLDrSw 1000;
BA_ "GenSigSendType" SG_ 1363 CF_Gway_RLDrSw 4;
BA_REL_ "GenSigTimeoutTime" BU_SG_REL_ CLU SG_ 1363 CF_Gway_IntTailAct 1000;
BA_ "GenSigSendType" SG_ 1363 CF_Gway_IntTailAct 4;
BA_REL_ "GenSigTimeoutTime" BU_SG_REL_ AVM SG_ 1363 CF_Gway_CountryCfg 0;
BA_REL_ "GenSigTimeoutTime" BU_SG_REL_ CLU SG_ 1363 CF_Gway_CountryCfg 0;
BA_REL_ "GenSigTimeoutTime" BU_SG_REL_ PGS SG_ 1363 CF_Gway_CountryCfg 0;
BA_ "GenSigSendType" SG_ 1363 CF_Gway_CountryCfg 4;
BA_REL_ "GenSigTimeoutTime" BU_SG_REL_ AFLS SG_ 1363 CF_Gway_WiperParkPosition 1000;
BA_REL_ "GenSigTimeoutTime" BU_SG_REL_ EMS SG_ 1363 CF_Gway_WiperParkPosition 1000;
BA_REL_ "GenSigTimeoutTime" BU_SG_REL_ LDWS_LKAS SG_ 1363 CF_Gway_WiperParkPosition 1000;
BA_ "GenSigSendType" SG_ 1363 CF_Gway_WiperParkPosition 4;
BA_REL_ "GenSigTimeoutTime" BU_SG_REL_ LDWS_LKAS SG_ 1363 CF_Gway_HLLowLHFail 1000;
BA_REL_ "GenSigTimeoutTime" BU_SG_REL_ SNV SG_ 1363 CF_Gway_HLLowLHFail 1000;
BA_ "GenSigSendType" SG_ 1363 CF_Gway_HLLowLHFail 4;
BA_REL_ "GenSigTimeoutTime" BU_SG_REL_ LDWS_LKAS SG_ 1363 CF_Gway_HLLowRHFail 1000;
BA_REL_ "GenSigTimeoutTime" BU_SG_REL_ SNV SG_ 1363 CF_Gway_HLLowRHFail 1000;
BA_ "GenSigSendType" SG_ 1363 CF_Gway_HLLowRHFail 4;
BA_REL_ "GenSigTimeoutTime" BU_SG_REL_ CLU SG_ 1363 CF_Gway_ESCLFailWarn 1000;
BA_ "GenSigSendType" SG_ 1363 CF_Gway_ESCLFailWarn 4;
BA_REL_ "GenSigTimeoutTime" BU_SG_REL_ CLU SG_ 1363 CF_Gway_ESCLNotLockedWarn 1000;
BA_ "GenSigSendType" SG_ 1363 CF_Gway_ESCLNotLockedWarn 4;
BA_REL_ "GenSigTimeoutTime" BU_SG_REL_ CLU SG_ 1363 CF_Gway_ESCLNotUnlockWarn 1000;
BA_ "GenSigSendType" SG_ 1363 CF_Gway_ESCLNotUnlockWarn 4;
BA_REL_ "GenSigTimeoutTime" BU_SG_REL_ CLU SG_ 1363 CF_Gway_IDoutWarn 1000;
BA_ "GenSigSendType" SG_ 1363 CF_Gway_IDoutWarn 4;
BA_REL_ "GenSigTimeoutTime" BU_SG_REL_ CLU SG_ 1363 CF_Gway_ImmoLp 1000;
BA_ "GenSigSendType" SG_ 1363 CF_Gway_ImmoLp 4;
BA_ "GenSigSendType" SG_ 1363 CF_Gway_BCMRKEID 4;
BA_REL_ "GenSigTimeoutTime" BU_SG_REL_ CLU SG_ 1363 CF_Gway_VehicleNotPWarn 1000;
BA_ "GenSigSendType" SG_ 1363 CF_Gway_VehicleNotPWarn 4;
BA_REL_ "GenSigTimeoutTime" BU_SG_REL_ CLU SG_ 1363 CF_Gway_DeactivationWarn 1000;
BA_ "GenSigSendType" SG_ 1363 CF_Gway_DeactivationWarn 4;
BA_REL_ "GenSigTimeoutTime" BU_SG_REL_ CLU SG_ 1363 CF_Gway_KeyBATDischargeWarn 1000;
BA_ "GenSigSendType" SG_ 1363 CF_Gway_KeyBATDischargeWarn 4;
BA_REL_ "GenSigTimeoutTime" BU_SG_REL_ CLU SG_ 1363 CF_Gway_SSBWarn 1000;
BA_ "GenSigSendType" SG_ 1363 CF_Gway_SSBWarn 4;
BA_REL_ "GenSigTimeoutTime" BU_SG_REL_ CLU SG_ 1363 CF_Gway_SMKFobID 1000;
BA_ "GenSigSendType" SG_ 1363 CF_Gway_SMKFobID 4;
BA_REL_ "GenSigTimeoutTime" BU_SG_REL_ CLU SG_ 1363 CF_Gway_SMKRKECmd 1000;
BA_ "GenSigSendType" SG_ 1363 CF_Gway_SMKRKECmd 4;
BA_ "GenSigSendType" SG_ 1363 CF_Gway_AutoLightOption 4;
BA_REL_ "GenSigTimeoutTime" BU_SG_REL_ CLU SG_ 1363 CF_Gway_SJBDeliveryMode 1000;
BA_ "GenSigSendType" SG_ 1363 CF_Gway_SJBDeliveryMode 4;
BA_ "GenSigStartValue" SG_ 1363 CF_Gway_SJBDeliveryMode 1;
BA_REL_ "GenSigTimeoutTime" BU_SG_REL_ CLU SG_ 1363 CF_Gway_KeyoutLp 1000;
BA_ "GenSigSendType" SG_ 1363 CF_Gway_KeyoutLp 4;
BA_REL_ "GenSigTimeoutTime" BU_SG_REL_ CLU SG_ 1363 CF_Gway_SMKDispWarn 1000;
BA_ "GenSigSendType" SG_ 1363 CF_Gway_SMKDispWarn 4;
BA_ "GenSigSendType" SG_ 1363 CF_Gway_WngBuz 4;
BA_ "GenMsgCycleTime" BO_ 1369 200;
BA_ "GenMsgNrOfRepetition" BO_ 1369 3;
BA_ "GenSigSendType" SG_ 1369 CF_Gway_MemoryP1Cmd 4;
BA_ "GenSigSendType" SG_ 1369 CF_Gway_MemoryP2Cmd 4;
BA_ "GenSigSendType" SG_ 1369 CF_Gway_PBackP1Cmd 4;
BA_ "GenSigSendType" SG_ 1369 CF_Gway_PBackP2Cmd 4;
BA_ "GenSigSendType" SG_ 1369 CF_Gway_StrgWhlHeatedState 4;
BA_ "GenSigSendType" SG_ 1369 CF_Gway_PBackStopCmd 4;
BA_ "GenSigSendType" SG_ 1369 CF_Gway_StaticBendLhAct 4;
BA_ "GenSigSendType" SG_ 1369 CF_Gway_StaticBendRhAct 4;
BA_ "GenSigSendType" SG_ 1369 CF_Gway_DrvWdwStat 4;
BA_ "GenSigSendType" SG_ 1369 CF_Gway_RLWdwState 4;
BA_ "GenSigSendType" SG_ 1369 CF_Gway_RRWdwState 4;
BA_ "GenSigSendType" SG_ 1369 CF_Gway_AstWdwStat 4;
BA_ "GenSigSendType" SG_ 1369 CF_Gway_MemoryEnable 4;
BA_ "GenSigSendType" SG_ 1369 CF_Gway_PBACKStopCmd 4;
BA_REL_ "GenSigTimeoutTime" BU_SG_REL_ CLU SG_ 1369 CF_Gway_PBACKStop 0;
BA_REL_ "GenSigTimeoutTime" BU_SG_REL_ HUD SG_ 1369 CF_Gway_PBACKStop 0;
BA_ "GenSigSendType" SG_ 1369 CF_Gway_PBACKStop 4;
BA_ "GenSigSendType" SG_ 1369 CF_Gway_IMSBuzzer 4;
BA_REL_ "GenSigTimeoutTime" BU_SG_REL_ CLU SG_ 1369 CF_Gway_DrvSeatBeltInd 1000;
BA_ "GenSigSendType" SG_ 1369 CF_Gway_DrvSeatBeltInd 4;
BA_REL_ "GenSigTimeoutTime" BU_SG_REL_ CLU SG_ 1369 CF_Gway_AstSeatBeltInd 1000;
BA_ "GenSigSendType" SG_ 1369 CF_Gway_AstSeatBeltInd 4;
BA_REL_ "GenSigTimeoutTime" BU_SG_REL_ CLU SG_ 1369 CF_Gway_RCSeatBeltInd 1000;
BA_ "GenSigSendType" SG_ 1369 CF_Gway_RCSeatBeltInd 4;
BA_REL_ "GenSigTimeoutTime" BU_SG_REL_ CLU SG_ 1369 CF_Gway_RLSeatBeltInd 1000;
BA_ "GenSigSendType" SG_ 1369 CF_Gway_RLSeatBeltInd 4;
BA_REL_ "GenSigTimeoutTime" BU_SG_REL_ CLU SG_ 1369 CF_Gway_RRSeatBeltInd 1000;
BA_ "GenSigSendType" SG_ 1369 CF_Gway_RRSeatBeltInd 4;
BA_ "GenSigSendType" SG_ 1369 CF_Gway_RrWiperHighSw 4;
BA_ "GenSigSendType" SG_ 1369 CF_Gway_RrWiperLowSw 4;
BA_ "GenMsgCycleTime" BO_ 127 1000;
BA_ "GenMsgNrOfRepetition" BO_ 127 3;
BA_REL_ "GenSigTimeoutTime" BU_SG_REL_ CLU SG_ 127 C_StopLampLhOpenSts 0;
BA_ "GenSigSendType" SG_ 127 C_StopLampLhOpenSts 4;
BA_REL_ "GenSigTimeoutTime" BU_SG_REL_ CLU SG_ 127 C_StopLampRhOpenSts 0;
BA_ "GenSigSendType" SG_ 127 C_StopLampRhOpenSts 4;
BA_REL_ "GenSigTimeoutTime" BU_SG_REL_ CLU SG_ 127 C_HMSLOpenSts 0;
BA_ "GenSigSendType" SG_ 127 C_HMSLOpenSts 4;
BA_REL_ "GenSigTimeoutTime" BU_SG_REL_ CLU SG_ 127 C_HLampLowLhOpenSts 0;
BA_ "GenSigSendType" SG_ 127 C_HLampLowLhOpenSts 4;
BA_REL_ "GenSigTimeoutTime" BU_SG_REL_ CLU SG_ 127 C_HLampLowRhOpenSts 0;
BA_ "GenSigSendType" SG_ 127 C_HLampLowRhOpenSts 4;
BA_REL_ "GenSigTimeoutTime" BU_SG_REL_ CLU SG_ 127 C_HLampHighLhOpenSts 0;
BA_ "GenSigSendType" SG_ 127 C_HLampHighLhOpenSts 4;
BA_REL_ "GenSigTimeoutTime" BU_SG_REL_ CLU SG_ 127 C_HLampHighRhOpenSts 0;
BA_ "GenSigSendType" SG_ 127 C_HLampHighRhOpenSts 4;
BA_REL_ "GenSigTimeoutTime" BU_SG_REL_ CLU SG_ 127 C_DRLLampLhOpenSts 0;
BA_ "GenSigSendType" SG_ 127 C_DRLLampLhOpenSts 4;
BA_REL_ "GenSigTimeoutTime" BU_SG_REL_ CLU SG_ 127 C_DRLLampRhOpenSts 0;
BA_ "GenSigSendType" SG_ 127 C_DRLLampRhOpenSts 4;
BA_REL_ "GenSigTimeoutTime" BU_SG_REL_ CLU SG_ 127 C_RearFOGLhOpenSts 0;
BA_ "GenSigSendType" SG_ 127 C_RearFOGLhOpenSts 4;
BA_REL_ "GenSigTimeoutTime" BU_SG_REL_ CLU SG_ 127 C_RearFOGRhOpenSts 0;
BA_ "GenSigSendType" SG_ 127 C_RearFOGRhOpenSts 4;
BA_REL_ "GenSigTimeoutTime" BU_SG_REL_ CLU SG_ 127 C_FrontFOGLhOpenSts 0;
BA_ "GenSigSendType" SG_ 127 C_FrontFOGLhOpenSts 4;
BA_REL_ "GenSigTimeoutTime" BU_SG_REL_ CLU SG_ 127 C_FrontFOGRhOpenSts 0;
BA_ "GenSigSendType" SG_ 127 C_FrontFOGRhOpenSts 4;
BA_REL_ "GenSigTimeoutTime" BU_SG_REL_ CLU SG_ 127 C_RearEXTTailLhOpenSts 0;
BA_ "GenSigSendType" SG_ 127 C_RearEXTTailLhOpenSts 4;
BA_REL_ "GenSigTimeoutTime" BU_SG_REL_ CLU SG_ 127 C_RearEXTTailRhOpenSts 0;
BA_ "GenSigSendType" SG_ 127 C_RearEXTTailRhOpenSts 4;
BA_REL_ "GenSigTimeoutTime" BU_SG_REL_ CLU SG_ 127 C_FrontEXTTailLhOpenSts 0;
BA_ "GenSigSendType" SG_ 127 C_FrontEXTTailLhOpenSts 4;
BA_REL_ "GenSigTimeoutTime" BU_SG_REL_ CLU SG_ 127 C_FrontEXTTailRhOpenSts 0;
BA_ "GenSigSendType" SG_ 127 C_FrontEXTTailRhOpenSts 4;
BA_REL_ "GenSigTimeoutTime" BU_SG_REL_ CLU SG_ 127 C_RearTSIGLhOpenSts 0;
BA_ "GenSigSendType" SG_ 127 C_RearTSIGLhOpenSts 4;
BA_REL_ "GenSigTimeoutTime" BU_SG_REL_ CLU SG_ 127 C_RearTSIGRhOpenSts 0;
BA_ "GenSigSendType" SG_ 127 C_RearTSIGRhOpenSts 4;
BA_REL_ "GenSigTimeoutTime" BU_SG_REL_ CLU SG_ 127 C_FrontTSIGLhOpenSts 0;
BA_ "GenSigSendType" SG_ 127 C_FrontTSIGLhOpenSts 4;
BA_REL_ "GenSigTimeoutTime" BU_SG_REL_ CLU SG_ 127 C_FrontTSIGRhOpenSts 0;
BA_ "GenSigSendType" SG_ 127 C_FrontTSIGRhOpenSts 4;
BA_REL_ "GenSigTimeoutTime" BU_SG_REL_ CLU SG_ 127 C_SBendingLhOpenSts 0;
BA_ "GenSigSendType" SG_ 127 C_SBendingLhOpenSts 4;
BA_REL_ "GenSigTimeoutTime" BU_SG_REL_ CLU SG_ 127 C_SBendingRhOpenSts 0;
BA_ "GenSigSendType" SG_ 127 C_SBendingRhOpenSts 4;
BA_REL_ "GenSigTimeoutTime" BU_SG_REL_ CLU SG_ 127 C_LicensePlateLhOpenSts 0;
BA_ "GenSigSendType" SG_ 127 C_LicensePlateLhOpenSts 4;
BA_REL_ "GenSigTimeoutTime" BU_SG_REL_ CLU SG_ 127 C_LicensePlateRhOpenSts 0;
BA_ "GenSigSendType" SG_ 127 C_LicensePlateRhOpenSts 4;
BA_ "GenMsgCycleTime" BO_ 1472 1000;
BA_ "GenMsgNrOfRepetition" BO_ 1472 3;
BA_REL_ "GenSigTimeoutTime" BU_SG_REL_ CLU SG_ 1472 Audio_VolumeDown 3500;
BA_ "GenSigSendType" SG_ 1472 Audio_VolumeDown 4;
BA_ "GenSigStartValue" SG_ 1472 Audio_VolumeDown 3;
BA_REL_ "GenSigTimeoutTime" BU_SG_REL_ CLU SG_ 1472 Pas_Spkr_Flh_Alarm 3500;
BA_ "GenSigSendType" SG_ 1472 Pas_Spkr_Flh_Alarm 4;
BA_REL_ "GenSigTimeoutTime" BU_SG_REL_ CLU SG_ 1472 Pas_Spkr_Fcnt_Alarm 3500;
BA_ "GenSigSendType" SG_ 1472 Pas_Spkr_Fcnt_Alarm 4;
BA_REL_ "GenSigTimeoutTime" BU_SG_REL_ CLU SG_ 1472 Pas_Spkr_Frh_Alarm 3500;
BA_ "GenSigSendType" SG_ 1472 Pas_Spkr_Frh_Alarm 4;
BA_REL_ "GenSigTimeoutTime" BU_SG_REL_ CLU SG_ 1472 Pas_Spkr_Rlh_Alarm 3500;
BA_REL_ "GenSigTimeoutTime" BU_SG_REL_ PGS SG_ 1472 Pas_Spkr_Rlh_Alarm 3500;
BA_ "GenSigSendType" SG_ 1472 Pas_Spkr_Rlh_Alarm 4;
BA_REL_ "GenSigTimeoutTime" BU_SG_REL_ CLU SG_ 1472 Pas_Spkr_Rcnt_Alarm 3500;
BA_ "GenSigSendType" SG_ 1472 Pas_Spkr_Rcnt_Alarm 4;
BA_REL_ "GenSigTimeoutTime" BU_SG_REL_ CLU SG_ 1472 Pas_Spkr_Rrh_Alarm 3500;
BA_REL_ "GenSigTimeoutTime" BU_SG_REL_ PGS SG_ 1472 Pas_Spkr_Rrh_Alarm 3500;
BA_ "GenSigSendType" SG_ 1472 Pas_Spkr_Rrh_Alarm 4;
BA_ "GenMsgCycleTime" BO_ 1427 200;
BA_REL_ "GenSigTimeoutTime" BU_SG_REL_ CLU SG_ 1427 TPMS_W_LAMP 2000;
BA_REL_ "GenSigTimeoutTime" BU_SG_REL_ CUBIS SG_ 1427 TPMS_W_LAMP 2000;
BA_REL_ "GenSigTimeoutTime" BU_SG_REL_ HUD SG_ 1427 TPMS_W_LAMP 2000;
BA_REL_ "GenSigTimeoutTime" BU_SG_REL_ IBOX SG_ 1427 TPMS_W_LAMP 2000;
BA_REL_ "GenSigTimeoutTime" BU_SG_REL_ CLU SG_ 1427 TREAD_W_LAMP 2000;
BA_REL_ "GenSigTimeoutTime" BU_SG_REL_ CUBIS SG_ 1427 TREAD_W_LAMP 2000;
BA_REL_ "GenSigTimeoutTime" BU_SG_REL_ HUD SG_ 1427 TREAD_W_LAMP 2000;
BA_REL_ "GenSigTimeoutTime" BU_SG_REL_ IBOX SG_ 1427 TREAD_W_LAMP 2000;
BA_ "GenMsgDelayTime" BO_ 1265 10;
BA_ "GenMsgCycleTime" BO_ 1265 20;
BA_ "GenMsgCycleTime" BO_ 1456 1000;
BA_REL_ "GenSigTimeoutTime" BU_SG_REL_ _4WD SG_ 1456 CF_Clu_Odometer 5000;
BA_REL_ "GenSigTimeoutTime" BU_SG_REL_ AAF SG_ 1456 CF_Clu_Odometer 5000;
BA_REL_ "GenSigTimeoutTime" BU_SG_REL_ BCM SG_ 1456 CF_Clu_Odometer 5000;
BA_REL_ "GenSigTimeoutTime" BU_SG_REL_ CUBIS SG_ 1456 CF_Clu_Odometer 5000;
BA_REL_ "GenSigTimeoutTime" BU_SG_REL_ EMS SG_ 1456 CF_Clu_Odometer 5000;
BA_REL_ "GenSigTimeoutTime" BU_SG_REL_ EPB SG_ 1456 CF_Clu_Odometer 5000;
BA_REL_ "GenSigTimeoutTime" BU_SG_REL_ IBOX SG_ 1456 CF_Clu_Odometer 5000;
BA_REL_ "GenSigTimeoutTime" BU_SG_REL_ LDWS_LKAS SG_ 1456 CF_Clu_Odometer 5000;
BA_REL_ "GenSigTimeoutTime" BU_SG_REL_ SCC SG_ 1456 CF_Clu_Odometer 5000;
BA_REL_ "GenSigTimeoutTime" BU_SG_REL_ TPMS SG_ 1456 CF_Clu_Odometer 5000;
BA_ "GenMsgSendType" BO_ 1397 8;
BA_ "GenMsgCycleTime" BO_ 1397 0;
BA_ "GenMsgNrOfRepetition" BO_ 1397 3;
BA_REL_ "GenSigTimeoutTime" BU_SG_REL_ AVM SG_ 1397 HU_AVM_Cal_Cmd 0;
BA_REL_ "GenSigTimeoutTime" BU_SG_REL_ PGS SG_ 1397 HU_AVM_Cal_Cmd 0;
BA_ "GenSigSendType" SG_ 1397 HU_AVM_Cal_Cmd 4;
BA_ "GenSigStartValue" SG_ 1397 HU_AVM_Cal_Cmd 15;
BA_REL_ "GenSigTimeoutTime" BU_SG_REL_ AVM SG_ 1397 HU_AVM_Cal_Method 0;
BA_REL_ "GenSigTimeoutTime" BU_SG_REL_ PGS SG_ 1397 HU_AVM_Cal_Method 0;
BA_ "GenSigSendType" SG_ 1397 HU_AVM_Cal_Method 4;
BA_ "GenSigStartValue" SG_ 1397 HU_AVM_Cal_Method 3;
BA_REL_ "GenSigTimeoutTime" BU_SG_REL_ AVM SG_ 1397 HU_AVM_Save_Controlpoint 0;
BA_REL_ "GenSigTimeoutTime" BU_SG_REL_ PGS SG_ 1397 HU_AVM_Save_Controlpoint 0;
BA_ "GenSigSendType" SG_ 1397 HU_AVM_Save_Controlpoint 4;
BA_ "GenSigStartValue" SG_ 1397 HU_AVM_Save_Controlpoint 3;
BA_REL_ "GenSigTimeoutTime" BU_SG_REL_ AVM SG_ 1397 HU_AVM_PT_X 0;
BA_REL_ "GenSigTimeoutTime" BU_SG_REL_ PGS SG_ 1397 HU_AVM_PT_X 0;
BA_ "GenSigSendType" SG_ 1397 HU_AVM_PT_X 4;
BA_ "GenSigStartValue" SG_ 1397 HU_AVM_PT_X 4095;
BA_REL_ "GenSigTimeoutTime" BU_SG_REL_ AVM SG_ 1397 HU_AVM_RearViewPointOpt 0;
BA_REL_ "GenSigTimeoutTime" BU_SG_REL_ PGS SG_ 1397 HU_AVM_RearViewPointOpt 0;
BA_ "GenSigSendType" SG_ 1397 HU_AVM_RearViewPointOpt 4;
BA_ "GenSigStartValue" SG_ 1397 HU_AVM_RearViewPointOpt 15;
BA_REL_ "GenSigTimeoutTime" BU_SG_REL_ AVM SG_ 1397 HU_AVM_PT_Y 0;
BA_REL_ "GenSigTimeoutTime" BU_SG_REL_ PGS SG_ 1397 HU_AVM_PT_Y 0;
BA_ "GenSigSendType" SG_ 1397 HU_AVM_PT_Y 4;
BA_ "GenSigStartValue" SG_ 1397 HU_AVM_PT_Y 4095;
BA_REL_ "GenSigTimeoutTime" BU_SG_REL_ AVM SG_ 1397 HU_AVM_FrontViewPointOpt 0;
BA_REL_ "GenSigTimeoutTime" BU_SG_REL_ PGS SG_ 1397 HU_AVM_FrontViewPointOpt 0;
BA_ "GenSigSendType" SG_ 1397 HU_AVM_FrontViewPointOpt 4;
BA_ "GenSigStartValue" SG_ 1397 HU_AVM_FrontViewPointOpt 15;
BA_REL_ "GenSigTimeoutTime" BU_SG_REL_ AVM SG_ 1397 HU_AVM_SelectedMenu 0;
BA_REL_ "GenSigTimeoutTime" BU_SG_REL_ PGS SG_ 1397 HU_AVM_SelectedMenu 0;
BA_ "GenSigSendType" SG_ 1397 HU_AVM_SelectedMenu 4;
BA_ "GenSigStartValue" SG_ 1397 HU_AVM_SelectedMenu 31;
BA_REL_ "GenSigTimeoutTime" BU_SG_REL_ AVM SG_ 1397 HU_AVM_CameraOff 0;
BA_REL_ "GenSigTimeoutTime" BU_SG_REL_ PGS SG_ 1397 HU_AVM_CameraOff 0;
BA_ "GenSigSendType" SG_ 1397 HU_AVM_CameraOff 4;
BA_ "GenSigStartValue" SG_ 1397 HU_AVM_CameraOff 3;
BA_REL_ "GenSigTimeoutTime" BU_SG_REL_ AVM SG_ 1397 HU_AVM_Option 0;
BA_REL_ "GenSigTimeoutTime" BU_SG_REL_ PGS SG_ 1397 HU_AVM_Option 0;
BA_ "GenSigSendType" SG_ 1397 HU_AVM_Option 4;
BA_ "GenSigStartValue" SG_ 1397 HU_AVM_Option 15;
BA_REL_ "GenSigTimeoutTime" BU_SG_REL_ AVM SG_ 1397 HU_AVM_CrossLineMove_Cmd 0;
BA_REL_ "GenSigTimeoutTime" BU_SG_REL_ PGS SG_ 1397 HU_AVM_CrossLineMove_Cmd 0;
BA_ "GenSigSendType" SG_ 1397 HU_AVM_CrossLineMove_Cmd 4;
BA_ "GenSigStartValue" SG_ 1397 HU_AVM_CrossLineMove_Cmd 15;
BA_REL_ "GenSigTimeoutTime" BU_SG_REL_ AVM SG_ 1397 HU_AVM_RearView_Option 0;
BA_REL_ "GenSigTimeoutTime" BU_SG_REL_ PGS SG_ 1397 HU_AVM_RearView_Option 0;
BA_ "GenSigSendType" SG_ 1397 HU_AVM_RearView_Option 4;
BA_ "GenSigStartValue" SG_ 1397 HU_AVM_RearView_Option 15;
BA_REL_ "GenSigTimeoutTime" BU_SG_REL_ AVM SG_ 1397 HU_AVM_FrontView_Option 0;
BA_REL_ "GenSigTimeoutTime" BU_SG_REL_ PGS SG_ 1397 HU_AVM_FrontView_Option 0;
BA_ "GenSigSendType" SG_ 1397 HU_AVM_FrontView_Option 4;
BA_ "GenSigStartValue" SG_ 1397 HU_AVM_FrontView_Option 15;
BA_ "GenMsgSendType" BO_ 1395 8;
BA_ "GenMsgCycleTime" BO_ 1395 0;
BA_ "GenMsgNrOfRepetition" BO_ 1395 3;
BA_REL_ "GenSigTimeoutTime" BU_SG_REL_ AVM SG_ 1395 HU_PGSSelectedMenu 0;
BA_REL_ "GenSigTimeoutTime" BU_SG_REL_ PGS SG_ 1395 HU_PGSSelectedMenu 0;
BA_ "GenSigSendType" SG_ 1395 HU_PGSSelectedMenu 4;
BA_ "GenSigStartValue" SG_ 1395 HU_PGSSelectedMenu 15;
BA_REL_ "GenSigTimeoutTime" BU_SG_REL_ AVM SG_ 1395 HU_PGSOption 0;
BA_REL_ "GenSigTimeoutTime" BU_SG_REL_ PGS SG_ 1395 HU_PGSOption 0;
BA_ "GenSigSendType" SG_ 1395 HU_PGSOption 4;
BA_ "GenSigStartValue" SG_ 1395 HU_PGSOption 31;
BA_REL_ "GenSigTimeoutTime" BU_SG_REL_ AVM SG_ 1395 HU_AVM_ParkingAssistMenu 0;
BA_REL_ "GenSigTimeoutTime" BU_SG_REL_ PGS SG_ 1395 HU_AVM_ParkingAssistMenu 0;
BA_ "GenSigSendType" SG_ 1395 HU_AVM_ParkingAssistMenu 4;
BA_ "GenSigStartValue" SG_ 1395 HU_AVM_ParkingAssistMenu 15;
BA_REL_ "GenSigTimeoutTime" BU_SG_REL_ AVM SG_ 1395 HU_AVM_ParkingAssistSB 0;
BA_REL_ "GenSigTimeoutTime" BU_SG_REL_ PGS SG_ 1395 HU_AVM_ParkingAssistSB 0;
BA_ "GenSigSendType" SG_ 1395 HU_AVM_ParkingAssistSB 4;
BA_ "GenSigStartValue" SG_ 1395 HU_AVM_ParkingAssistSB 15;
BA_ "GenMsgCycleTime" BO_ 1370 600;
BA_ "GenMsgNrOfRepetition" BO_ 1370 3;
BA_REL_ "GenSigTimeoutTime" BU_SG_REL_ AVM SG_ 1370 HU_AVM_Status 2100;
BA_REL_ "GenSigTimeoutTime" BU_SG_REL_ PGS SG_ 1370 HU_AVM_Status 2100;
BA_ "GenSigSendType" SG_ 1370 HU_AVM_Status 4;
BA_ "GenSigStartValue" SG_ 1370 HU_AVM_Status 3;
BA_ "GenMsgSendType" BO_ 1490 8;
BA_ "GenMsgCycleTime" BO_ 1490 0;
BA_ "GenMsgNrOfRepetition" BO_ 1490 3;
BA_REL_ "GenSigTimeoutTime" BU_SG_REL_ DATC SG_ 1490 HU_DATC_RearOnOffSet 0;
BA_ "GenSigSendType" SG_ 1490 HU_DATC_RearOnOffSet 4;
BA_ "GenSigStartValue" SG_ 1490 HU_DATC_RearOnOffSet 3;
BA_REL_ "GenSigTimeoutTime" BU_SG_REL_ DATC SG_ 1490 HU_DATC_ADSOnOffSet 0;
BA_ "GenSigSendType" SG_ 1490 HU_DATC_ADSOnOffSet 4;
BA_ "GenSigStartValue" SG_ 1490 HU_DATC_ADSOnOffSet 3;
BA_ "GenMsgCycleTime" BO_ 1491 1000;
BA_ "GenMsgNrOfRepetition" BO_ 1491 3;
BA_REL_ "GenSigTimeoutTime" BU_SG_REL_ DATC SG_ 1491 HU_VRActivity 0;
BA_ "GenSigSendType" SG_ 1491 HU_VRActivity 4;
BA_ "GenSigStartValue" SG_ 1491 HU_VRActivity 3;
BA_REL_ "GenSigTimeoutTime" BU_SG_REL_ DATC SG_ 1491 HU_PhoneActivity 0;
BA_ "GenSigSendType" SG_ 1491 HU_PhoneActivity 4;
BA_ "GenSigStartValue" SG_ 1491 HU_PhoneActivity 3;
BA_REL_ "GenSigTimeoutTime" BU_SG_REL_ DATC SG_ 1491 BlowerNoiseControl 3500;
BA_ "GenSigSendType" SG_ 1491 BlowerNoiseControl 4;
BA_ "GenMsgCycleTime" BO_ 1407 2000;
BA_ "GenMsgNrOfRepetition" BO_ 1407 3;
BA_REL_ "GenSigTimeoutTime" BU_SG_REL_ AVM SG_ 1407 HU_Type 3500;
BA_REL_ "GenSigTimeoutTime" BU_SG_REL_ PGS SG_ 1407 HU_Type 3500;
BA_ "GenSigSendType" SG_ 1407 HU_Type 4;
BA_ "GenSigStartValue" SG_ 1407 HU_Type 255;
BA_ "GenMsgCycleTime" BO_ 1492 1000;
BA_ "GenMsgNrOfRepetition" BO_ 1492 3;
BA_REL_ "GenSigTimeoutTime" BU_SG_REL_ DATC SG_ 1492 TMU_IVRActivity 0;
BA_ "GenSigSendType" SG_ 1492 TMU_IVRActivity 4;
BA_ "GenSigStartValue" SG_ 1492 TMU_IVRActivity 3;
BA_REL_ "GenSigTimeoutTime" BU_SG_REL_ DATC SG_ 1492 TMU_PhoneActivity 0;
BA_ "GenSigSendType" SG_ 1492 TMU_PhoneActivity 4;
BA_ "GenSigStartValue" SG_ 1492 TMU_PhoneActivity 3;
BA_ "GenMsgCycleTime" BO_ 1411 100;
BA_ "GenSigStartValue" SG_ 1411 CF_Cubis_HUDisp 15;
BA_ "GenMsgCycleTime" BO_ 899 20;
BA_ "GenMsgCycleTime" BO_ 896 20;
BA_ "GenMsgCycleTime" BO_ 1017 20;
BA_ "GenSigStartValue" SG_ 1017 Height_FL 128;
BA_ "GenSigStartValue" SG_ 1017 Height_FR 128;
BA_ "GenSigStartValue" SG_ 1017 Height_RL 128;
BA_ "GenSigStartValue" SG_ 1017 Height_RR 128;
BA_ "GenMsgCycleTime" BO_ 900 20;
BA_ "GenMsgCycleTime" BO_ 1170 50;
BA_ "GenSigStartValue" SG_ 1170 CF_Ems_DecelReq 4094;
BA_ "GenSigStartValue" SG_ 1170 CR_Ems_EngOilTemp 53;
BA_ "GenSigStartValue" SG_ 1170 CF_Ems_ModeledAmbTemp 164;
BA_ "GenMsgCycleTime" BO_ 1479 100;
BA_ "GenSigStartValue" SG_ 129 BRAKE_ACT 1;
BA_ "GenMsgCycleTime" BO_ 1366 100;
BA_REL_ "GenSigTimeoutTime" BU_SG_REL_ AAF SG_ 1366 PID_04h 1000;
BA_REL_ "GenSigTimeoutTime" BU_SG_REL_ TCU SG_ 1366 PID_04h 1000;
BA_REL_ "GenSigTimeoutTime" BU_SG_REL_ AAF SG_ 1366 PID_05h 1000;
BA_REL_ "GenSigTimeoutTime" BU_SG_REL_ TCU SG_ 1366 PID_05h 1000;
BA_ "GenSigStartValue" SG_ 1366 PID_05h 40;
BA_REL_ "GenSigTimeoutTime" BU_SG_REL_ AAF SG_ 1366 PID_0Ch 1000;
BA_REL_ "GenSigTimeoutTime" BU_SG_REL_ TCU SG_ 1366 PID_0Ch 1000;
BA_REL_ "GenSigTimeoutTime" BU_SG_REL_ AAF SG_ 1366 PID_0Dh 1000;
BA_REL_ "GenSigTimeoutTime" BU_SG_REL_ TCU SG_ 1366 PID_0Dh 1000;
BA_REL_ "GenSigTimeoutTime" BU_SG_REL_ AAF SG_ 1366 PID_11h 1000;
BA_REL_ "GenSigTimeoutTime" BU_SG_REL_ TCU SG_ 1366 PID_11h 1000;
BA_REL_ "GenSigTimeoutTime" BU_SG_REL_ AAF SG_ 1366 PID_03h 1000;
BA_REL_ "GenSigTimeoutTime" BU_SG_REL_ TCU SG_ 1366 PID_03h 1000;
BA_ "GenMsgCycleTime" BO_ 1367 100;
BA_REL_ "GenSigTimeoutTime" BU_SG_REL_ AAF SG_ 1367 PID_06h 1000;
BA_REL_ "GenSigTimeoutTime" BU_SG_REL_ IBOX SG_ 1367 PID_06h 1000;
BA_REL_ "GenSigTimeoutTime" BU_SG_REL_ TCU SG_ 1367 PID_06h 1000;
BA_ "GenSigStartValue" SG_ 1367 PID_06h 128;
BA_REL_ "GenSigTimeoutTime" BU_SG_REL_ AAF SG_ 1367 PID_07h 1000;
BA_REL_ "GenSigTimeoutTime" BU_SG_REL_ IBOX SG_ 1367 PID_07h 1000;
BA_REL_ "GenSigTimeoutTime" BU_SG_REL_ TCU SG_ 1367 PID_07h 1000;
BA_ "GenSigStartValue" SG_ 1367 PID_07h 128;
BA_REL_ "GenSigTimeoutTime" BU_SG_REL_ AAF SG_ 1367 PID_08h 1000;
BA_REL_ "GenSigTimeoutTime" BU_SG_REL_ IBOX SG_ 1367 PID_08h 1000;
BA_REL_ "GenSigTimeoutTime" BU_SG_REL_ TCU SG_ 1367 PID_08h 1000;
BA_ "GenSigStartValue" SG_ 1367 PID_08h 128;
BA_REL_ "GenSigTimeoutTime" BU_SG_REL_ AAF SG_ 1367 PID_09h 1000;
BA_REL_ "GenSigTimeoutTime" BU_SG_REL_ IBOX SG_ 1367 PID_09h 1000;
BA_REL_ "GenSigTimeoutTime" BU_SG_REL_ TCU SG_ 1367 PID_09h 1000;
BA_ "GenSigStartValue" SG_ 1367 PID_09h 128;
BA_REL_ "GenSigTimeoutTime" BU_SG_REL_ AAF SG_ 1367 PID_0Bh 1000;
BA_REL_ "GenSigTimeoutTime" BU_SG_REL_ IBOX SG_ 1367 PID_0Bh 1000;
BA_REL_ "GenSigTimeoutTime" BU_SG_REL_ TCU SG_ 1367 PID_0Bh 1000;
BA_REL_ "GenSigTimeoutTime" BU_SG_REL_ AAF SG_ 1367 PID_23h 1000;
BA_REL_ "GenSigTimeoutTime" BU_SG_REL_ IBOX SG_ 1367 PID_23h 1000;
BA_REL_ "GenSigTimeoutTime" BU_SG_REL_ TCU SG_ 1367 PID_23h 1000;
BA_ "GenMsgCycleTime" BO_ 1168 50;
BA_ "GenSigStartValue" SG_ 1168 EPB_FAIL 2;
BA_ "GenSigStartValue" SG_ 1168 EPB_FORCE 1000;
BA_ "GenMsgSendType" BO_ 1984 8;
BA_ "GenMsgCycleTime" BO_ 1984 0;
BA_ "GenMsgNrOfRepetition" BO_ 1984 3;
BA_REL_ "GenSigTimeoutTime" BU_SG_REL_ SAS SG_ 1984 CCW 0;
BA_ "GenSigSendType" SG_ 1984 CCW 4;
BA_REL_ "GenSigTimeoutTime" BU_SG_REL_ SAS SG_ 1984 SAS_CID 0;
BA_ "GenSigSendType" SG_ 1984 SAS_CID 4;
BA_ "GenSigStartValue" SG_ 1984 SAS_CID 688;
BA_ "GenMsgCycleTime" BO_ 1151 20;
BA_ "GenSigStartValue" SG_ 1151 _4WD_TQC_LIM 64255;
BA_ "GenMsgCycleTime" BO_ 915 20;
BA_ "GenSigStartValue" SG_ 915 SA_COUNT 16384;
BA_ "GenMsgCycleTime" BO_ 916 20;
BA_ "GenSigStartValue" SG_ 356 CR_Esc_StrTqReq 2048;
BA_ "GenMsgCycleTime" BO_ 1414 100;
BA_REL_ "GenSigTimeoutTime" BU_SG_REL_ CLU SG_ 1414 CF_Evp_Stat 2000;
BA_ "GenMsgCycleTime" BO_ 1365 100;
BA_REL_ "GenSigTimeoutTime" BU_SG_REL_ EMS SG_ 1365 CR_Fpcm_LPActPre 1000;
BA_REL_ "GenSigTimeoutTime" BU_SG_REL_ EMS SG_ 1365 CF_Fpcm_LPPumpOverCur 1000;
BA_REL_ "GenSigTimeoutTime" BU_SG_REL_ EMS SG_ 1365 CF_Fpcm_PreSnrHi 1000;
BA_REL_ "GenSigTimeoutTime" BU_SG_REL_ EMS SG_ 1365 CF_Fpcm_PreSnrDisc 1000;
BA_REL_ "GenSigTimeoutTime" BU_SG_REL_ EMS SG_ 1365 CF_Fpcm_PreSnrShort 1000;
BA_REL_ "GenSigTimeoutTime" BU_SG_REL_ EMS SG_ 1365 CF_Fpcm_LPPumpDiscShort 1000;
BA_REL_ "GenSigTimeoutTime" BU_SG_REL_ EMS SG_ 1365 CF_Fpcm_LP_System_Error 1000;
BA_REL_ "GenSigTimeoutTime" BU_SG_REL_ EMS SG_ 1365 CF_Fpcm_PreSnrSigErr 1000;
BA_REL_ "GenSigTimeoutTime" BU_SG_REL_ EMS SG_ 1365 CF_Fpcm_LPCtrCirFlt 1000;
BA_ "GenMsgCycleTime" BO_ 1378 100;
BA_REL_ "GenSigTimeoutTime" BU_SG_REL_ CLU SG_ 1378 CF_Hud_HeightStaus 1000;
BA_REL_ "GenSigTimeoutTime" BU_SG_REL_ BCM SG_ 1378 CF_Hud_PBackStatus 0;
BA_REL_ "GenSigTimeoutTime" BU_SG_REL_ CLU SG_ 1378 CF_Hud_PBackStatus 0;
BA_REL_ "GenSigTimeoutTime" BU_SG_REL_ CLU SG_ 1378 CF_Hud_Brightness 1000;
BA_ "GenMsgCycleTime" BO_ 1415 200;
BA_ "GenMsgCycleTime" BO_ 1419 50;
BA_ "GenSigStartValue" SG_ 852 CF_Lvr_GearInf 9;
BA_ "GenMsgCycleTime" BO_ 897 20;
BA_ "GenSigStartValue" SG_ 897 CF_Mdps_Stat 1;
BA_ "GenSigStartValue" SG_ 897 CR_Mdps_DrvTq 2048;
BA_REL_ "GenSigTimeoutTime" BU_SG_REL_ _4WD SG_ 688 SAS_Angle 100;
BA_REL_ "GenSigTimeoutTime" BU_SG_REL_ ACU SG_ 688 SAS_Angle 100;
BA_REL_ "GenSigTimeoutTime" BU_SG_REL_ AFLS SG_ 688 SAS_Angle 100;
BA_REL_ "GenSigTimeoutTime" BU_SG_REL_ AVM SG_ 688 SAS_Angle 100;
BA_REL_ "GenSigTimeoutTime" BU_SG_REL_ CLU SG_ 688 SAS_Angle 100;
BA_REL_ "GenSigTimeoutTime" BU_SG_REL_ ECS SG_ 688 SAS_Angle 100;
BA_REL_ "GenSigTimeoutTime" BU_SG_REL_ EMS SG_ 688 SAS_Angle 100;
BA_REL_ "GenSigTimeoutTime" BU_SG_REL_ ESC SG_ 688 SAS_Angle 100;
BA_REL_ "GenSigTimeoutTime" BU_SG_REL_ IBOX SG_ 688 SAS_Angle 100;
BA_REL_ "GenSigTimeoutTime" BU_SG_REL_ LCA SG_ 688 SAS_Angle 100;
BA_REL_ "GenSigTimeoutTime" BU_SG_REL_ LDWS_LKAS SG_ 688 SAS_Angle 100;
BA_REL_ "GenSigTimeoutTime" BU_SG_REL_ PGS SG_ 688 SAS_Angle 100;
BA_REL_ "GenSigTimeoutTime" BU_SG_REL_ PSB SG_ 688 SAS_Angle 100;
BA_REL_ "GenSigTimeoutTime" BU_SG_REL_ SCC SG_ 688 SAS_Angle 100;
BA_REL_ "GenSigTimeoutTime" BU_SG_REL_ SPAS SG_ 688 SAS_Angle 100;
BA_REL_ "GenSigTimeoutTime" BU_SG_REL_ TCU SG_ 688 SAS_Angle 100;
BA_REL_ "GenSigTimeoutTime" BU_SG_REL_ AFLS SG_ 688 SAS_Speed 100;
BA_REL_ "GenSigTimeoutTime" BU_SG_REL_ ECS SG_ 688 SAS_Speed 100;
BA_REL_ "GenSigTimeoutTime" BU_SG_REL_ ESC SG_ 688 SAS_Speed 100;
BA_REL_ "GenSigTimeoutTime" BU_SG_REL_ IBOX SG_ 688 SAS_Speed 100;
BA_REL_ "GenSigTimeoutTime" BU_SG_REL_ LDWS_LKAS SG_ 688 SAS_Speed 100;
BA_REL_ "GenSigTimeoutTime" BU_SG_REL_ SCC SG_ 688 SAS_Speed 100;
BA_REL_ "GenSigTimeoutTime" BU_SG_REL_ SPAS SG_ 688 SAS_Speed 100;
BA_REL_ "GenSigTimeoutTime" BU_SG_REL_ TCU SG_ 688 SAS_Speed 100;
BA_REL_ "GenSigTimeoutTime" BU_SG_REL_ ECS SG_ 688 SAS_Stat 100;
BA_REL_ "GenSigTimeoutTime" BU_SG_REL_ ESC SG_ 688 SAS_Stat 100;
BA_REL_ "GenSigTimeoutTime" BU_SG_REL_ IBOX SG_ 688 SAS_Stat 100;
BA_REL_ "GenSigTimeoutTime" BU_SG_REL_ LDWS_LKAS SG_ 688 SAS_Stat 100;
BA_REL_ "GenSigTimeoutTime" BU_SG_REL_ PSB SG_ 688 SAS_Stat 100;
BA_REL_ "GenSigTimeoutTime" BU_SG_REL_ SCC SG_ 688 SAS_Stat 100;
BA_REL_ "GenSigTimeoutTime" BU_SG_REL_ SPAS SG_ 688 SAS_Stat 100;
BA_REL_ "GenSigTimeoutTime" BU_SG_REL_ TCU SG_ 688 SAS_Stat 100;
BA_ "GenSigStartValue" SG_ 688 SAS_Stat 7;
BA_REL_ "GenSigTimeoutTime" BU_SG_REL_ ECS SG_ 688 MsgCount 100;
BA_REL_ "GenSigTimeoutTime" BU_SG_REL_ ESC SG_ 688 MsgCount 100;
BA_REL_ "GenSigTimeoutTime" BU_SG_REL_ IBOX SG_ 688 MsgCount 100;
BA_REL_ "GenSigTimeoutTime" BU_SG_REL_ LDWS_LKAS SG_ 688 MsgCount 100;
BA_REL_ "GenSigTimeoutTime" BU_SG_REL_ PSB SG_ 688 MsgCount 100;
BA_REL_ "GenSigTimeoutTime" BU_SG_REL_ SCC SG_ 688 MsgCount 100;
BA_REL_ "GenSigTimeoutTime" BU_SG_REL_ SPAS SG_ 688 MsgCount 100;
BA_REL_ "GenSigTimeoutTime" BU_SG_REL_ ECS SG_ 688 CheckSum 100;
BA_REL_ "GenSigTimeoutTime" BU_SG_REL_ EMS SG_ 688 CheckSum 100;
BA_REL_ "GenSigTimeoutTime" BU_SG_REL_ ESC SG_ 688 CheckSum 100;
BA_REL_ "GenSigTimeoutTime" BU_SG_REL_ IBOX SG_ 688 CheckSum 100;
BA_REL_ "GenSigTimeoutTime" BU_SG_REL_ LDWS_LKAS SG_ 688 CheckSum 100;
BA_REL_ "GenSigTimeoutTime" BU_SG_REL_ PSB SG_ 688 CheckSum 100;
BA_REL_ "GenSigTimeoutTime" BU_SG_REL_ SCC SG_ 688 CheckSum 100;
BA_REL_ "GenSigTimeoutTime" BU_SG_REL_ SPAS SG_ 688 CheckSum 100;
BA_ "GenMsgCycleTime" BO_ 1530 1000;
BA_REL_ "GenSigTimeoutTime" BU_SG_REL_ Dummy SG_ 1530 CF_Ods_PrcCmd 5000;
BA_REL_ "GenSigTimeoutTime" BU_SG_REL_ Dummy SG_ 1530 CF_Ods_BtsFail 5000;
BA_REL_ "GenSigTimeoutTime" BU_SG_REL_ ACU SG_ 1530 CF_Ods_AcuRcvSN 5000;
BA_REL_ "GenSigTimeoutTime" BU_SG_REL_ ACU SG_ 1530 CF_Ods_EolCal 5000;
BA_REL_ "GenSigTimeoutTime" BU_SG_REL_ ACU SG_ 1530 CF_Ods_PsFail 5000;
BA_REL_ "GenSigTimeoutTime" BU_SG_REL_ ACU SG_ 1530 CF_Ods_EcuFail 5000;
BA_REL_ "GenSigTimeoutTime" BU_SG_REL_ ACU SG_ 1530 CF_Ods_WgtStat 5000;
BA_REL_ "GenSigTimeoutTime" BU_SG_REL_ ACU SG_ 1530 CF_Ods_OccStat 5000;
BA_REL_ "GenSigTimeoutTime" BU_SG_REL_ ACU SG_ 1530 CR_Wcs_ErrStat 5000;
BA_REL_ "GenSigTimeoutTime" BU_SG_REL_ ACU SG_ 1530 CR_Wcs_ClassStat 5000;
BA_REL_ "GenSigTimeoutTime" BU_SG_REL_ BCM SG_ 1530 CR_Wcs_ClassStat 5000;
BA_ "GenMsgCycleTime" BO_ 1531 1000;
BA_REL_ "GenSigTimeoutTime" BU_SG_REL_ ACU SG_ 1531 CR_Ods_SerNum0 5000;
BA_REL_ "GenSigTimeoutTime" BU_SG_REL_ ACU SG_ 1531 CR_Ods_SerNum1 5000;
BA_REL_ "GenSigTimeoutTime" BU_SG_REL_ ACU SG_ 1531 CR_Ods_SerNum2 5000;
BA_REL_ "GenSigTimeoutTime" BU_SG_REL_ ACU SG_ 1531 CR_Ods_SerNum3 5000;
BA_REL_ "GenSigTimeoutTime" BU_SG_REL_ ACU SG_ 1531 CR_Ods_SerNum4 5000;
BA_REL_ "GenSigTimeoutTime" BU_SG_REL_ ACU SG_ 1531 CR_Ods_SerNum5 5000;
BA_REL_ "GenSigTimeoutTime" BU_SG_REL_ ACU SG_ 1531 CR_Ods_SerNum6 5000;
BA_REL_ "GenSigTimeoutTime" BU_SG_REL_ ACU SG_ 1531 CR_Ods_SerNum7 5000;
BA_ "GenMsgCycleTime" BO_ 1532 1000;
BA_REL_ "GenSigTimeoutTime" BU_SG_REL_ ACU SG_ 1532 CR_Ods_ID 5000;
BA_REL_ "GenSigTimeoutTime" BU_SG_REL_ Dummy SG_ 1532 CR_Ods_Chksum_H 5000;
BA_REL_ "GenSigTimeoutTime" BU_SG_REL_ Dummy SG_ 1532 CR_Ods_Chksum_L 5000;
BA_REL_ "GenSigTimeoutTime" BU_SG_REL_ Dummy SG_ 1532 CR_Ods_RomID_H 5000;
BA_REL_ "GenSigTimeoutTime" BU_SG_REL_ Dummy SG_ 1532 CR_Ods_RomID_L 5000;
BA_ "GenMsgCycleTime" BO_ 1393 100;
BA_ "GenMsgCycleTime" BO_ 1379 1000;
BA_ "GenMsgNrOfRepetition" BO_ 1379 3;
BA_REL_ "GenSigTimeoutTime" BU_SG_REL_ CLU SG_ 1379 PGS_State 5000;
BA_ "GenSigSendType" SG_ 1379 PGS_State 4;
BA_ "GenSigStartValue" SG_ 1379 PGS_State 15;
BA_REL_ "GenSigTimeoutTime" BU_SG_REL_ CLU SG_ 1379 PGS_ParkGuideState 5000;
BA_ "GenSigSendType" SG_ 1379 PGS_ParkGuideState 4;
BA_ "GenSigStartValue" SG_ 1379 PGS_ParkGuideState 31;
BA_REL_ "GenSigTimeoutTime" BU_SG_REL_ CLU SG_ 1379 PGS_Option 5000;
BA_ "GenSigSendType" SG_ 1379 PGS_Option 4;
BA_ "GenSigStartValue" SG_ 1379 PGS_Option 31;
BA_REL_ "GenSigTimeoutTime" BU_SG_REL_ CLU SG_ 1379 PGS_Version 5000;
BA_ "GenSigSendType" SG_ 1379 PGS_Version 4;
BA_ "GenSigStartValue" SG_ 1379 PGS_Version 65535;
BA_ "GenMsgCycleTime" BO_ 1434 200;
BA_ "GenMsgCycleTime" BO_ 912 20;
BA_ "GenSigStartValue" SG_ 912 CF_Spas_Stat 1;
BA_ "GenMsgCycleTime" BO_ 1268 50;
BA_ "GenSigStartValue" SG_ 1268 CF_Spas_VolDown 3;
BA_REL_ "GenSigTimeoutTime" BU_SG_REL_ ESC SG_ 354 Clutch_Driving_Tq 0;
BA_REL_ "GenSigTimeoutTime" BU_SG_REL_ CLU SG_ 354 Cluster_Engine_RPM 0;
BA_REL_ "GenSigTimeoutTime" BU_SG_REL_ CLU SG_ 354 Cluster_Engine_RPM_Flag 0;
BA_REL_ "GenSigTimeoutTime" BU_SG_REL_ CLU SG_ 1427 POS_FL_W_LAMP 2000;
BA_REL_ "GenSigTimeoutTime" BU_SG_REL_ CUBIS SG_ 1427 POS_FL_W_LAMP 2000;
BA_REL_ "GenSigTimeoutTime" BU_SG_REL_ HUD SG_ 1427 POS_FL_W_LAMP 2000;
BA_REL_ "GenSigTimeoutTime" BU_SG_REL_ IBOX SG_ 1427 POS_FL_W_LAMP 2000;
BA_REL_ "GenSigTimeoutTime" BU_SG_REL_ CLU SG_ 1427 POS_FR_W_LAMP 2000;
BA_REL_ "GenSigTimeoutTime" BU_SG_REL_ CUBIS SG_ 1427 POS_FR_W_LAMP 2000;
BA_REL_ "GenSigTimeoutTime" BU_SG_REL_ HUD SG_ 1427 POS_FR_W_LAMP 2000;
BA_REL_ "GenSigTimeoutTime" BU_SG_REL_ IBOX SG_ 1427 POS_FR_W_LAMP 2000;
BA_REL_ "GenSigTimeoutTime" BU_SG_REL_ CLU SG_ 1427 POS_RL_W_LAMP 2000;
BA_REL_ "GenSigTimeoutTime" BU_SG_REL_ CUBIS SG_ 1427 POS_RL_W_LAMP 2000;
BA_REL_ "GenSigTimeoutTime" BU_SG_REL_ HUD SG_ 1427 POS_RL_W_LAMP 2000;
BA_REL_ "GenSigTimeoutTime" BU_SG_REL_ IBOX SG_ 1427 POS_RL_W_LAMP 2000;
BA_REL_ "GenSigTimeoutTime" BU_SG_REL_ CLU SG_ 1427 POS_RR_W_LAMP 2000;
BA_REL_ "GenSigTimeoutTime" BU_SG_REL_ CUBIS SG_ 1427 POS_RR_W_LAMP 2000;
BA_REL_ "GenSigTimeoutTime" BU_SG_REL_ HUD SG_ 1427 POS_RR_W_LAMP 2000;
BA_REL_ "GenSigTimeoutTime" BU_SG_REL_ IBOX SG_ 1427 POS_RR_W_LAMP 2000;
BA_REL_ "GenSigTimeoutTime" BU_SG_REL_ CLU SG_ 1427 STATUS_TPMS 2000;
BA_REL_ "GenSigTimeoutTime" BU_SG_REL_ CLU SG_ 1427 UNIT 0;
BA_REL_ "GenSigTimeoutTime" BU_SG_REL_ CLU SG_ 1427 PRESSURE_FL 2000;
BA_REL_ "GenSigTimeoutTime" BU_SG_REL_ CLU SG_ 1427 PRESSURE_FR 2000;
BA_REL_ "GenSigTimeoutTime" BU_SG_REL_ CLU SG_ 1427 PRESSURE_RL 2000;
BA_REL_ "GenSigTimeoutTime" BU_SG_REL_ CLU SG_ 1427 PRESSURE_RR 2000;
VAL_ 1412 CF_Aaf_ActFlapStatus 1 "CLOSE" 2 "OPEN" 3 "Unknown" ;
VAL_ 1412 CF_Aaf_ModeStatus 0 "Normal Mode" 1 "High Speed Mode" 2 "High Performance Mode" 3 "HS & HP Mode" 4 "Coast Down Mode" 5 "Fail Safety Mode" 6 "Safe Mode" 7 "Reserved" ;
VAL_ 1412 CF_Aaf_WrnLamp 0 "Warning Lamp/Message Off" 1 "Warning Lamp/Message On" ;
VAL_ 1412 CF_Aaf_SolFlapStatus 1 "CLOSE" 2 "OPEN" ;
VAL_ 1412 CF_Aaf_MilOnReq 0 "MIL OFF" 1 "MIL ON" ;
VAL_ 906 ABS_DEF 0 "ABS is not defective" 1 "ABS is defective" ;
VAL_ 906 EBD_DEF 0 "EBD is not defective" 1 "EBD is defective" ;
VAL_ 906 ABS_ACT 0 "ABS control inactive" 1 "ABS control active" ;
VAL_ 906 ABS_W_LAMP 0 "ABS Warning lamp OFF" 1 "ABS Warning lamp ON" ;
VAL_ 906 EBD_W_LAMP 0 "EBD Warning lamp OFF" 1 "EBD Warning lamp ON" ;
VAL_ 906 ABS_DIAG 0 "ABS is not diagnostic mode" 1 "ABS is diagnostic mode" ;
VAL_ 906 ESS_STAT 0 "ESS control ¡°inactive¡± (Normal condition)" 1 "ESS control ¡°active¡± (Emergency stop condition)" 2 "ESS system is defective" 3 "ESS extended function active (Hazard lamp blinking)" ;
VAL_ 903 WHL_DIR_FL 0 "Unknown (Wheel moving stop state or Not applied wheel sensor for direction)" 1 "Forward direction" 2 "Backward direction" 3 "Error identifier" ;
VAL_ 903 WHL_DIR_FR 0 "Unknown (Wheel moving stop state or Not applied wheel sensor for direction)" 1 "Forward direction" 2 "Backward direction" 3 "Error identifier" ;
VAL_ 903 WHL_DIR_RL 0 "Unknown (Wheel moving stop state or Not applied wheel sensor for direction)" 1 "Forward direction" 2 "Backward direction" 3 "Error identifier" ;
VAL_ 903 WHL_DIR_RR 0 "Unknown (Wheel moving stop state or Not applied wheel sensor for direction)" 1 "Forward direction" 2 "Backward direction" 3 "Error identifier" ;
VAL_ 1440 CF_Ods_SNRcv 0 "Request to send ODS Serial Number" 1 "Acknowledgement for the Correct S/N Received" ;
VAL_ 1440 CF_Ods_IDRcv 0 "Request to send ODS Identifier" 1 "Acknowledgement for the Correct ODS Identifier Received" ;
VAL_ 1440 CF_Ods_RZReq 0 "No re-zero request" 1 "Request to re-zero the empty seat offset" ;
VAL_ 1440 CF_Abg_DepInhEnt 0 "Default Value" 1 "Crash event with Passenger Front/Side Airbag Inhibited" ;
VAL_ 1440 CF_Abg_DepEnt 0 "Default Value" 1 "Crash event with Passenger Front/Side Airbag not Inhibited" ;
VAL_ 1440 CF_PasBkl_FltStat 0 "No Fault" 1 "Fault condition exists" ;
VAL_ 1440 CF_DriBkl_FltStat 0 "No Fault" 1 "Fault condition exists" ;
VAL_ 1440 CF_PasBkl_Stat 0 "Passenger Seat Belt Not Latched" 1 "Passenger Seat Belt Latched" ;
VAL_ 1440 CF_DriBkl_Stat 0 "Driver Seat Belt Not Latched" 1 "Driver Seat Belt Latched" ;
VAL_ 1440 CF_SWL_Ind 0 "Warning Lamp on" 1 "Warning Lamp off" 2 "Warning Lamp flash" 3 "Not used" ;
VAL_ 1440 CF_Acu_FltStat 0 "Fault status is active" 1 "Fault status is historic" 2 "Fault does not exist" 3 "Not used" ;
VAL_ 1440 CF_Acu_ExtOfSab 0 "ACU EOL Programming Mode" 1 "Side(or Side/Curtain) Airbag doesn't exist." 2 "Side(or Side/Curtain) Airbag exists." 3 "Not used" ;
VAL_ 1425 AFLS_STAT 0 "AFLS is in normal condition" 1 "AFLS Off" 2 "Reserved" 3 "AFLS is defective" ;
VAL_ 1425 CF_Afls_TrfChgStat 0 "Nomal Mode" 1 "Traffic Change Mode" ;
VAL_ 1425 CF_Afls_LedHLStat 0 "LED Headlamp is in nornal condition" 1 "FAN fail" 2 "LED Fail" 3 "Reserved" ;
VAL_ 1437 CF_Ahls_WarnLamp 0 "Turn off the warning lamp" 1 "Turn on the warning lamp" 2 "The warning lamp blink(2Hz)" 3 "Invalid" ;
VAL_ 1437 CF_Ahls_WarnMsg 0 "AHLS normal operation" 1 "AHLS malfunction" 2 "AHLS fired" 3 "Invalid" ;
VAL_ 1371 AVM_View 0 "None" 1 "AVM Off" 2 "AVM+Rear View" 3 "AVM+Front View" 4 "RearLeft+Rear View" 5 "FrontLeft+Front View" 6 "RearRight+Rear View" 7 "FrontRight+Front View" 8 "Rear Wide View" 9 "Front Wide View" 10 "Manual Calibration Initial View" 11 "Front Camera Calibration View" 12 "Rear Camera Calibration View" 13 "Left Camera Calibration View" 14 "Right Camera Calibration View" 15 "Direct AVM Video Out View" 16 "Parking Assist Init View" 17 "Parking Assist Rear View" 18 "Parking Assist Front View" 19 "Front 2-Section View" 20 "Reserved" 21 "Reserved" 22 "Reserved" 23 "Reserved" 24 "Reserved" 25 "Reserved" 26 "Reserved" 27 "Reserved" 28 "Reserved" 29 "Reserved" 30 "Reserved" 31 "Invalid" ;
VAL_ 1371 AVM_ParkingAssist_BtnSts 0 "Not used" 1 "Start Btn Deactivation" 2 "Start Btn" 3 "Exit" 4 "reserved" 5 "reserved" 6 "reserved" 7 "Invalid" ;
VAL_ 1371 AVM_Display_Message 0 "Off" 1 "No Message" 2 "Calibration Mode" 3 "Reserved" 4 "Reserved" 5 "Reserved" 6 "Reserved" 7 "Reserved" 8 "Reserved" 9 "Reserved" 10 "Reserved" 11 "Reserved" 12 "Reserved" 13 "Reserved" 14 "Reserved" 15 "Reserved" 16 "Reserved" 17 "Reserved" 18 "Reserved" 19 "Reserved" 20 "Reserved" 21 "Reserved" 22 "Reserved" 23 "Reserved" 24 "Reserved" 25 "Reserved" 26 "Reserved" 27 "Reserved" 28 "Reserved" 29 "Reserved" 30 "Reserved" 31 "Reserved" 32 "Reserved" 33 "Reserved" 34 "Reserved" 35 "Reserved" 36 "Reserved" 37 "Reserved" 38 "Reserved" 39 "Reserved" 40 "Reserved" 41 "Reserved" 42 "Reserved" 43 "Reserved" 44 "Reserved" 45 "Reserved" 46 "Reserved" 47 "Reserved" 48 "Reserved" 49 "Reserved" 50 "Reserved" 51 "Reserved" 52 "Reserved" 53 "Reserved" 54 "Reserved" 55 "Reserved" 56 "Reserved" 57 "Reserved" 58 "Select ParkingAssistMode" 59 "Reserved" 60 "Reserved" 61 "Warning Around" 62 "Warning Front" 63 "Warning Rear" 255 "Invalid" ;
VAL_ 1371 AVM_Popup_Msg 0 "Not used" 1 "No Message" 2 "Release Parking Assist Mode" 3 "reserved" 4 "reserved" 5 "reserved" 6 "reserved" 7 "reserved" 8 "reserved" 9 "reserved" 10 "reserved" 11 "reserved" 12 "reserved" 13 "reserved" 15 "Invalid" ;
VAL_ 1371 AVM_Ready 0 "Off" 1 "AVM Mode Start Request" 2 "AVM Mode End Request" 3 "Black Screen On Request" 4 "Black Screen Off  Request" 5 "Reserved" 6 "Reserved" 7 "Reserved" 8 "Reserved" 9 "Reserved" 10 "Reserved" 11 "Reserved" 12 "Reserved" 13 "Reserved" 14 "Reserved" 15 "Invalid" ;
VAL_ 1371 AVM_ParkingAssist_Step 0 "Not used" 1 "Message Not Display" 2 "Left Garage Step1" 3 "Left Garage Step2" 4 "Right Garage Step1" 5 "Right Garage Step2" 6 "Garage Park Complete" 7 "Left Parallel Step1" 8 "Left Parallel Step2" 9 "Right Parallel Step1" 10 "Right Parallel Step2" 11 "Parallel Park Complete" 12 "Reserved" 13 "Reserved" 14 "Reserved" 15 "Invalid" ;
VAL_ 1371 AVM_FrontBtn_Type 0 "Not used" 3 "reserved" 4 "reserved" 5 "reserved" 6 "reserved" 7 "reserved" 8 "reserved" 9 "reserved" 10 "reserved" 11 "reserved" 12 "reserved" 13 "reserved" 14 "reserved" 1 "Wide Button Type" 2 "2-Section Button Type" 15 "Invalid" ;
VAL_ 1371 AVM_Option 15 "Invalid" ;
VAL_ 1371 AVM_HU_FrontViewPointOpt 0 "Not used" 4 "reserved" 5 "reserved" 6 "reserved" 7 "reserved" 8 "reserved" 9 "reserved" 10 "reserved" 11 "reserved" 12 "reserved" 13 "reserved" 14 "reserved" 1 "30 degree" 2 "45 degree" 3 "60 degree" 15 "Invalid" ;
VAL_ 1371 AVM_HU_RearView_Option 0 "None" 1 "AVM+Rear" 2 "RearLeft+Rear" 3 "RearRight+Rear" 4 "Rear Wide" 5 "reserved" 6 "reserved" 7 "reserved" 8 "reserved" 9 "reserved" 10 "reserved" 11 "reserved" 12 "reserved" 13 "reserved" 14 "reserved" 15 "Invalid" ;
VAL_ 1371 AVM_HU_FrontView_Option 0 "None" 1 "AVM+Front" 2 "FrontLeft+Front" 3 "FrontRight+Front" 4 "Front Wide" 5 "reserved" 6 "reserved" 7 "reserved" 8 "reserved" 9 "reserved" 10 "reserved" 11 "reserved" 12 "reserved" 13 "reserved" 14 "reserved" 15 "Invalid" ;
VAL_ 1371 AVM_Version 0 "None" 65535 "Invalid" ;
VAL_ 1363 CF_Gway_GwayDiagState 0 "Stop Diag" 1 "Start Diag" ;
VAL_ 1363 CF_Gway_DDMDiagState 0 "Stop Diag" 1 "Start Diag" ;
VAL_ 1363 CF_Gway_SCMDiagState 0 "Stop Diag" 1 "Start Diag" ;
VAL_ 1363 CF_Gway_PSMDiagState 0 "Stop Diag" 1 "Start Diag" ;
VAL_ 1363 CF_Gway_SJBDiagState 0 "Stop Diag" 1 "Start Diag" ;
VAL_ 1363 CF_Gway_IPMDiagState 0 "Stop Diag" 1 "Start Diag" ;
VAL_ 1363 CF_Gway_LDMFail 0 "Default Value" 1 "LED Head lamp fail" 2 "LED Fan fail" 3 "Invalid" ;
VAL_ 1363 CF_Gway_CLUSwGuiCtrl 0 "Off" 1 "Up" 2 "Down" 3 "Left" 4 "Right" 5 "OK" 6 "Reserved" 7 "Reserved" ;
VAL_ 1363 CF_Gway_CLUSwGroup 0 "Off" 1 "On" ;
VAL_ 1363 CF_Gway_CLUSwMode 0 "Off" 1 "On" ;
VAL_ 1363 CF_Gway_CLUSwEnter 0 "Off" 1 "On" ;
VAL_ 1363 CF_Gway_AutoLightValue 0 "OFF" 1 "Night" ;
VAL_ 1363 CF_Gway_BrakeFluidSw 0 "Off" 1 "On" ;
VAL_ 1363 CF_Gway_DrvSeatBeltInd 0 "Off" 1 "Blink" 2 "On" ;
VAL_ 1363 CF_Gway_AvTail 0 "Off" 1 "On" ;
VAL_ 1363 CF_Gway_RearFogAct 0 "Off" 1 "On" ;
VAL_ 1363 CF_Gway_ExtTailAct 0 "Off" 1 "On" ;
VAL_ 1363 CF_Gway_RRDrSw 0 "Close" 1 "Open" ;
VAL_ 1363 CF_Gway_RLDrSw 0 "Close" 1 "Open" ;
VAL_ 1363 CF_Gway_IntTailAct 0 "Off" 1 "On" ;
VAL_ 1363 CF_Gway_CountryCfg 0 "Dom" 1 "Na" 2 "Eu" 3 "Aus" 4 "China" 5 "Gen,Mes" ;
VAL_ 1363 CF_Gway_WiperParkPosition 0 "else" 1 "Parking Position" ;
VAL_ 1363 CF_Gway_HLLowLHFail 0 "Not Fail" 1 "Fail" ;
VAL_ 1363 CF_Gway_HLLowRHFail 0 "Not Fail" 1 "Fail" ;
VAL_ 1363 CF_Gway_ESCLFailWarn 0 "Off" 1 "On" ;
VAL_ 1363 CF_Gway_ESCLNotLockedWarn 0 "Off" 1 "On" ;
VAL_ 1363 CF_Gway_ESCLNotUnlockWarn 0 "Off" 1 "On" ;
VAL_ 1363 CF_Gway_IDoutWarn 0 "Off" 1 "On" ;
VAL_ 1363 CF_Gway_ImmoLp 0 "Off" 1 "On" ;
VAL_ 1363 CF_Gway_BCMRKEID 0 "None" 1 "ID1" 2 "ID2" 3 "ID3" 4 "ID4" ;
VAL_ 1363 CF_Gway_VehicleNotPWarn 0 "Off" 1 "On" ;
VAL_ 1363 CF_Gway_DeactivationWarn 0 "Off" 1 "On" ;
VAL_ 1363 CF_Gway_KeyBATDischargeWarn 0 "Off" 1 "On" ;
VAL_ 1363 CF_Gway_SSBWarn 0 "Off" 1 "On" ;
VAL_ 1363 CF_Gway_SMKFobID 0 "None" 1 "ID1" 2 "ID2" 3 "ID3" 4 "ID4" ;
VAL_ 1363 CF_Gway_SMKRKECmd 0 "None" 1 "Lock" 2 "Unlock" 3 "Trunk(or Tail Gate)" 4 "Panic" 5 "Panic Stop" 6 "Two Step Unlock Warning" ;
VAL_ 1363 CF_Gway_AutoLightOption 0 "Off" 1 "On" ;
VAL_ 1363 CF_Gway_SJBDeliveryMode 0 "Before Delivery(Welcome Off)" 1 "After Delivery(Welcome On)" ;
VAL_ 1363 CF_Gway_KeyoutLp 0 "Off" 1 "On" ;
VAL_ 1363 CF_Gway_SMKDispWarn 0 "Off" 1 "Shift_P_Warning" 2 "Key_Bat_Discharge_Warning" 3 "Not_Unlocked_Warning" 4 "Not_Locked_Warning" 5 "Escl_Ecu_Fail_Warning" 6 "Engine_Start_Operation_IND" 7 "Auth_Fail_Warning" 8 "Key_Removal_IND" 9 "SMK_Lamp_Warning" 10 "SSB_Warning" 11 "Auth_Fail_Warning2" 12 "Vehicle_Not_P_Warning" 13 "Stop Lamp Fuse Fail Warning" 14 "Not P_N Warning" ;
VAL_ 1363 CF_Gway_WngBuz 0 "Off" 1 "SeatBelt Warning" 2 "Key Operated Warning" 3 "Parking Brake Warning" 4 "Sun Roof Open Warning" 5 "Key Learning Sound(NoSMKOption)" 6 "ICE Warning" 7 "Rear Fog Warning" ;
VAL_ 1369 CF_Gway_MemoryP1Cmd 0 "None" 1 "P1" ;
VAL_ 1369 CF_Gway_MemoryP2Cmd 0 "None" 1 "P2" ;
VAL_ 1369 CF_Gway_PBackP1Cmd 0 "None" 1 "P1" ;
VAL_ 1369 CF_Gway_PBackP2Cmd 0 "None" 1 "P2" ;
VAL_ 1369 CF_Gway_StrgWhlHeatedState 0 "Off" 1 "On" ;
VAL_ 1369 CF_Gway_PBackStopCmd 0 "Off" 1 "Stop" ;
VAL_ 1369 CF_Gway_StaticBendLhAct 0 "Off" 1 "On" ;
VAL_ 1369 CF_Gway_StaticBendRhAct 0 "Off" 1 "On" ;
VAL_ 1369 CF_Gway_DrvWdwStat 0 "Window Close" 1 "Window Open" ;
VAL_ 1369 CF_Gway_RLWdwState 0 "Window Close" 1 "Window Open" ;
VAL_ 1369 CF_Gway_RRWdwState 0 "Window Close" 1 "Window Open" ;
VAL_ 1369 CF_Gway_AstWdwStat 0 "Window Close" 1 "Window Open" ;
VAL_ 1369 CF_Gway_MemoryEnable 0 "Disable" 1 "Enable" ;
VAL_ 1369 CF_Gway_PBACKStopCmd 0 "Off" 1 "Stop" ;
VAL_ 1369 CF_Gway_PBACKStop 0 "off" 1 "stop" ;
VAL_ 1369 CF_Gway_IMSBuzzer 0 "Off" 1 "On" ;
VAL_ 1369 CF_Gway_DrvSeatBeltInd 0 "Off" 1 "Blink" 2 "On" ;
VAL_ 1369 CF_Gway_AstSeatBeltInd 0 "Off" 1 "Blink" 2 "On" ;
VAL_ 1369 CF_Gway_RCSeatBeltInd 0 "Off" 1 "Blink" 2 "On" ;
VAL_ 1369 CF_Gway_RLSeatBeltInd 0 "Off" 1 "Blink" 2 "On" ;
VAL_ 1369 CF_Gway_RRSeatBeltInd 0 "Off" 1 "Blink" 2 "On" ;
VAL_ 1369 CF_Gway_RrWiperHighSw 0 "Off" 1 "On" ;
VAL_ 1369 CF_Gway_RrWiperLowSw 0 "Off" 1 "On" ;
VAL_ 127 C_StopLampLhOpenSts 0 "Normal" 1 "Open Status" ;
VAL_ 127 C_StopLampRhOpenSts 0 "Normal" 1 "Open Status" ;
VAL_ 127 C_HMSLOpenSts 0 "Normal" 1 "Open Status" ;
VAL_ 127 C_HLampLowLhOpenSts 0 "Normal" 1 "Open Status" ;
VAL_ 127 C_HLampLowRhOpenSts 0 "Normal" 1 "Open Status" ;
VAL_ 127 C_HLampHighLhOpenSts 0 "Normal" 1 "Open Status" ;
VAL_ 127 C_HLampHighRhOpenSts 0 "Normal" 1 "Open Status" ;
VAL_ 127 C_DRLLampLhOpenSts 0 "Normal" 1 "Open Status" ;
VAL_ 127 C_DRLLampRhOpenSts 0 "Normal" 1 "Open Status" ;
VAL_ 127 C_RearFOGLhOpenSts 0 "Normal" 1 "Open Status" ;
VAL_ 127 C_RearFOGRhOpenSts 0 "Normal" 1 "Open Status" ;
VAL_ 127 C_FrontFOGLhOpenSts 0 "Normal" 1 "Open Status" ;
VAL_ 127 C_FrontFOGRhOpenSts 0 "Normal" 1 "Open Status" ;
VAL_ 127 C_RearEXTTailLhOpenSts 0 "Normal" 1 "Open Status" ;
VAL_ 127 C_RearEXTTailRhOpenSts 0 "Normal" 1 "Open Status" ;
VAL_ 127 C_FrontEXTTailLhOpenSts 0 "Normal" 1 "Open Status" ;
VAL_ 127 C_FrontEXTTailRhOpenSts 0 "Normal" 1 "Open Status" ;
VAL_ 127 C_RearTSIGLhOpenSts 0 "Normal" 1 "Open Status" ;
VAL_ 127 C_RearTSIGRhOpenSts 0 "Normal" 1 "Open Status" ;
VAL_ 127 C_FrontTSIGLhOpenSts 0 "Normal" 1 "Open Status" ;
VAL_ 127 C_FrontTSIGRhOpenSts 0 "Normal" 1 "Open Status" ;
VAL_ 127 C_SBendingLhOpenSts 0 "Normal" 1 "Open Status" ;
VAL_ 127 C_SBendingRhOpenSts 0 "Normal" 1 "Open Status" ;
VAL_ 127 C_LicensePlateLhOpenSts 0 "Normal" 1 "Open Status" ;
VAL_ 127 C_LicensePlateRhOpenSts 0 "Normal" 1 "Open Status" ;
VAL_ 1472 Audio_VolumeDown 0 "Off" 1 "VolumeDown" 2 "reserved" 3 "Invalid" ;
VAL_ 1472 Pas_Spkr_Flh_Alarm 0 "off" 1 "1st waring" 2 "2nd warning" 3 "3rd warning" ;
VAL_ 1472 Pas_Spkr_Fcnt_Alarm 0 "off" 1 "1st waring" 2 "2nd warning" 3 "3rd warning" ;
VAL_ 1472 Pas_Spkr_Frh_Alarm 0 "off" 1 "1st waring" 2 "2nd warning" 3 "3rd warning" ;
VAL_ 1472 Pas_Spkr_Rlh_Alarm 0 "off" 1 "1st waring" 2 "2nd warning" 3 "3rd warning" ;
VAL_ 1472 Pas_Spkr_Rcnt_Alarm 0 "off" 1 "1st waring" 2 "2nd warning" 3 "3rd warning" ;
VAL_ 1472 Pas_Spkr_Rrh_Alarm 0 "off" 1 "1st waring" 2 "2nd warning" 3 "3rd warning" ;
VAL_ 1427 TPMS_W_LAMP 0 "TMPS Malfunction Warning lamp OFF" 1 "TMPS Malfunction Warning lamp ON" 2 "TMPS Malfunction Warning BLINKING(2Hz)" 3 "Reserved" ;
VAL_ 1427 TREAD_W_LAMP 0 "TREAD Warning lamp OFF" 1 "TREAD Warning lamp ON" 2 "TREAD Warning lamp BLINKING(2Hz)" 3 "Reserved" ;
VAL_ 1265 CF_Clu_CruiseSwState 0 "Idle Position" 1 "Resume/Plus" 2 "Set/Minus" 3 "Time gap (Distance, SCC only)" 4 "ACC/SCC cancel" 7 "Reserved" ;
VAL_ 1265 CF_Clu_CruiseSwMain 0 "Off" 1 "On" ;
VAL_ 1265 CF_Clu_SldMainSW 0 "Off" 1 "On" ;
VAL_ 1265 CF_Clu_VanzDecimal 0 "0" 1 "0.125" 2 "0.250" 3 "0.375" ;
VAL_ 1265 CF_Clu_SPEED_UNIT 0 "km/h" 1 "MPH" ;
VAL_ 1265 CF_Clu_DetentOut 0 "Detent Off" 1 "Detent On" ;
VAL_ 1265 CF_Clu_RheostatLevel 0 "Reserved" 1 "Step 1" 2 "Step 2" 3 "Step 3" 4 "Step 4" 5 "Step 5" 6 "Step 6" 7 "Step 7" 8 "Step 8" 9 "Step 9" 10 "Step 10" 11 "Step 11" 12 "Step 12" 13 "Step 13" 14 "Step 14" 15 "Step 15" 16 "Step 16" 17 "Step 17" 18 "Step 18" 19 "Step 19" 20 "Step 20 (Reset Value)" 21 "Step 21 (Detent)" ;
VAL_ 1265 CF_Clu_CluInfo 0 "Display is not applied" 1 "Display is applied" ;
VAL_ 1265 CF_Clu_AmpInfo 0 "AMP is not applied" 1 "AMP is applied" ;
VAL_ 1397 HU_AVM_Cal_Cmd 0 "Off" 1 "Update" 2 "Re-enter" 3 "Enter" 4 "Finish" 5 "Front Cal" 6 "Rear Cal" 7 "Left Cal" 8 "Right Cal" 9 "reserved" 10 "reserved" 11 "reserved" 12 "reserved" 13 "reserved" 14 "reserved" 15 "Invalid" ;
VAL_ 1397 HU_AVM_Cal_Method 0 "Not used" 1 "Manual Cal. Mode" 2 "Auto Cal. Mode" 3 "Invalid" ;
VAL_ 1397 HU_AVM_Save_Controlpoint 0 "Not used" 1 "Start Cmd" 2 "reserved" 3 "Invalid" ;
VAL_ 1397 HU_AVM_PT_X 4095 "Invalid x-coordinate" ;
VAL_ 1397 HU_AVM_RearViewPointOpt 0 "Not used" 4 "reserved" 5 "reserved" 6 "reserved" 7 "reserved" 8 "reserved" 9 "reserved" 10 "reserved" 11 "reserved" 12 "reserved" 13 "reserved" 14 "reserved" 1 "30 degree" 2 "45 degree" 3 "60 degree" 15 "Invalid" ;
VAL_ 1397 HU_AVM_PT_Y 4095 "Invalid y-coordinate" ;
VAL_ 1397 HU_AVM_FrontViewPointOpt 0 "Not used" 4 "reserved" 5 "reserved" 6 "reserved" 7 "reserved" 8 "reserved" 9 "reserved" 10 "reserved" 11 "reserved" 12 "reserved" 13 "reserved" 14 "reserved" 1 "30 degree" 2 "45 degree" 3 "60 degree" 15 "Invalid" ;
VAL_ 1397 HU_AVM_SelectedMenu 0 "Off" 1 "AVM+Rear View" 31 "Invalid" 2 "AVM+Front View" 3 "RearLeft+Rear View" 4 "FrontLeft+Front View" 5 "RearRight+Rear View" 6 "FrontRight+Front View" 7 "Rear Wide View" 8 "Front Wide View" 9 "reserved" 10 "reserved" 11 "reserved" 12 "reserved" 13 "reserved" 14 "reserved" 15 "reserved" 16 "reserved" 17 "reserved" 18 "reserved" 19 "reserved" 20 "reserved" 21 "reserved" 22 "reserved" 23 "reserved" 24 "reserved" 25 "reserved" 26 "reserved" 27 "reserved" 28 "reserved" 29 "reserved" 30 "reserved" ;
VAL_ 1397 HU_AVM_CameraOff 0 "Default" 1 "Camera Off" 2 "Not Used" 3 "Invalid" ;
VAL_ 1397 HU_AVM_Option 15 "Invalid" ;
VAL_ 1397 HU_AVM_CrossLineMove_Cmd 0 "Not used" 1 "Move Right" 2 "Move Left" 3 "Move Up" 4 "Move Down" 5 "reserved" 6 "reserved" 7 "reserved" 8 "reserved" 9 "reserved" 10 "reserved" 11 "reserved" 12 "reserved" 13 "reserved" 14 "reserved" 15 "Invalid" ;
VAL_ 1397 HU_AVM_RearView_Option 0 "None" 1 "AVM+Rear" 2 "RearLeft+Rear" 3 "RearRight+Rear" 4 "Rear Wide" 5 "reserved" 6 "reserved" 7 "reserved" 8 "reserved" 9 "reserved" 10 "reserved" 11 "reserved" 12 "reserved" 13 "reserved" 14 "reserved" 15 "Invalid" ;
VAL_ 1397 HU_AVM_FrontView_Option 0 "None" 1 "AVM+Front" 2 "FrontLeft+Front" 3 "FrontRight+Front" 4 "Front Wide" 5 "reserved" 6 "reserved" 7 "reserved" 8 "reserved" 9 "reserved" 10 "reserved" 11 "reserved" 12 "reserved" 13 "reserved" 14 "reserved" 15 "Invalid" ;
VAL_ 1395 HU_PGSSelectedMenu 0 "Off" 1 "Description" 2 "Garage Park" 3 "Parallel Park" 4 "Setting" 5 "Left" 6 "Right" 7 "Finish" 8 "Previous" 9 "Head Unit ºÎÆÃ Áß" 10 "Not used" 11 "Not used" 12 "Not used" 13 "Not used" 14 "Not used" 15 "Invalid" ;
VAL_ 1395 HU_PGSOption 0 "Use" 1 "Use" 2 "Use" 3 "Use" 4 "Use" 5 "Use" 6 "Use" 7 "Use" 8 "Use" 9 "Use" 10 "Use" 11 "Use" 12 "Use" 13 "Use" 14 "Use" 15 "Use" 16 "Reserved" 17 "Reserved" 18 "Reserved" 19 "Reserved" 20 "Reserved" 21 "Reserved" 22 "Reserved" 23 "Reserved" 24 "Reserved" 25 "Reserved" 26 "Reserved" 27 "Reserved" 28 "Reserved" 29 "Reserved" 30 "Reserved" 31 "Invalid" ;
VAL_ 1395 HU_AVM_ParkingAssistMenu 0 "Not Used" 1 "Parking Assist Btn Select" 2 "Reserved" 3 "Reserved" 4 "Reserved" 5 "Reserved" 6 "Reserved" 7 "Reserved" 8 "Reserved" 9 "Reserved" 10 "Reserved" 11 "Reserved" 12 "Reserved" 13 "Reserved" 14 "Reserved" 15 "Invalid" ;
VAL_ 1395 HU_AVM_ParkingAssistSB 0 "Not used" 1 "Right Angle Left" 2 "Right Angle Right" 3 "Parallel Left" 4 "Parallel Right" 5 "Reserved" 6 "Reserved" 7 "Reserved" 8 "Reserved" 9 "Reserved" 10 "Reserved" 11 "Reserved" 12 "Reserved" 13 "Reserved" 14 "Reserved" 15 "Invalid" ;
VAL_ 1370 HU_AVM_Status 0 "Not ready" 1 "Normal" 2 "Fail" 3 "Invalid" ;
VAL_ 1490 HU_DATC_RearOnOffSet 0 "Rear Off" 1 "Rear On" 2 "reserved" 3 "Invalid" ;
VAL_ 1490 HU_DATC_ADSOnOffSet 0 "Function Off" 1 "Function On" 2 "reserved" 3 "Invalid" ;
VAL_ 1491 HU_VRActivity 0 "Deactivated" 1 "Activated" 2 "reserved" 3 "Invalid" ;
VAL_ 1491 HU_PhoneActivity 0 "Deactivated" 1 "Activated" 2 "reserved" 3 "Invalid" ;
VAL_ 1491 BlowerNoiseControl 0 "Off" 1 "Blower Noise Control On" 2 "reserved" 3 "Invalid" ;
VAL_ 1407 HU_Type 16 "AVN(Tuner DVD KOR)" 17 "AVN(Tuner DVD EUR)" 18 "AVN(Tuner DVD China)" 19 "AVN(Tuner DVD Japan)" 20 "AVN(Tuner DVD EUR)" 21 "AVN(Tuner CDP KOR)" 22 "AVN(Tuner CDP EUR)" 23 "AVN(Tuner CDP China)" 24 "AVN(Tuner CDP Japan)" 25 "AVN(Tuner CDP EUR)" 32 "AVNT (Open)" 33 "AVNT (Not open)" 48 "Econmic Radio" 64 "Standard Radio" 80 "AV(Tuner DVD KOR)" 81 "AV(Tuner DVD EUR)" 82 "AV(Tuner DVD China)" 83 "AV(Tuner DVD Japan)" 84 "AV(Tuner DVD EUR)" 85 "AV(Tuner CDP KOR)" 86 "AV(Tuner CDP EUR)" 87 "AV(Tuner CDP China)" 88 "AV(Tuner CDP Japan)" 89 "AV(Tuner CDP EUR)" 96 "VIT Basic AVN" 97 "VIT Premier AVN" 255 "Invalid" ;
VAL_ 1492 TMU_IVRActivity 0 "Deactivated" 1 "Activated" 2 "reserved" 3 "Invalid" ;
VAL_ 1492 TMU_PhoneActivity 0 "Deactivated" 1 "Activated" 2 "reserved" 3 "Invalid" ;
VAL_ 1411 CF_Cubis_HUDisp 0 "AUDIO" 1 "AVN" 2 "MTS(Unserved)" 3 "MTS(Served)" ;
VAL_ 899 CF_Fatc_AcnRqSwi 0 "A/C off request" 1 "A/C on request" ;
VAL_ 899 CF_Fatc_AcnCltEnRq 0 "A/C clutch disable request" 1 "A/C clutch enable request" ;
VAL_ 899 CF_Fatc_EcvFlt 0 "Normal(No Fault)" 1 "ECV Control Fault" ;
VAL_ 899 CF_Fatc_BlwrOn 0 "HVAC Blower off" 1 "HVAC Blower on" ;
VAL_ 899 CF_FATC_Iden 0 "FATC Type 0 (reserved)" 1 "FATC Type 1 (Doowon)" 2 "FATC Type 2 (Halla)" 3 "FATC Type 3 (reserved)" ;
VAL_ 899 CF_Fatc_BlwrMax 0 "Max blower speed is not selected" 1 "Max blower speed is selected" ;
VAL_ 899 CF_Fatc_EngStartReq 0 "Normal" 1 "Engine Auto Start Request" ;
VAL_ 899 CF_Fatc_IsgStopReq 0 "Enable" 1 "Disable (Engine Stop is prohibited)" ;
VAL_ 899 CF_Fatc_CtrInf 0 "Internal Compressor" 1 "External Compressor with Comp clutch" 2 "External Compressor without Comp clutch" 3 "Fixed Compressor" ;
VAL_ 899 CF_Fatc_Compload 0 "A/C Off request" 1 "A/C On request" 2 "A/C On and Engine Speed 1 stage up request" 3 "A/C On and Engine Speed 2 stage up request" ;
VAL_ 899 CF_Fatc_ActiveEco 0 "Active ECO Button is not selected" 1 "Active ECO Button is selected" ;
VAL_ 899 CF_Fatc_AutoActivation 0 "invalid" 1 "Automatic control is Active" ;
VAL_ 899 CF_Fatc_DefSw 0 "FRONT DEF switch is not selected" 1 "FRONT DEF switch is selected" ;
VAL_ 899 CF_Fatc_PtcRlyStat 0 "PTC Relay Off" 1 "PTC Relay On" ;
VAL_ 896 CF_DiBox_SPIErrSedMSV 0 "NO ERROR" 1 "ERROR" ;
VAL_ 896 CF_DiBox_SPIErrFrtMSV 0 "NO ERROR" 1 "ERROR" ;
VAL_ 896 CF_DiBox_IDErrSedMSV 0 "NO ERROR" 1 "ERROR" ;
VAL_ 896 CF_DiBox_IDErrFrtMSV 0 "NO ERROR" 1 "ERROR" ;
VAL_ 896 CF_DiBox_IniStatMSV 0 "NO SUCESS" 1 "SUCCESS" ;
VAL_ 1017 Height_FL 254 "Not initialized" ;
VAL_ 1017 Height_FR 254 "Not initialized" ;
VAL_ 1017 Height_RL 254 "Not initialized" ;
VAL_ 1017 Height_RR 254 "Not initialized" ;
VAL_ 640 LV_FUEL_TYPE_ECU 0 "Gasoline" 1 "Gas" ;
VAL_ 640 LV_BFS_CFIRM 0 "Not Confirmed" 1 "Confirmed" ;
VAL_ 640 LV_CRASH 0 "Deactivation" 1 "Activation" ;
VAL_ 640 LV_VB_OFF_ACT 0 "Deactivation" 1 "Activation" ;
VAL_ 640 LV_GSL_MAP 0 "AMP signal send" 1 "MAP signal send" ;
VAL_ 640 LV_ENG_TURN 0 "Deactivation" 1 "Activation" ;
VAL_ 608 GLOW_STAT 0 "Lamp Off" 1 "Lamp On" ;
VAL_ 608 CRUISE_LAMP_M 0 "Cruise MAIN switch indication lamp turn OFF" 1 "Cruise MAIN switch indication lamp turn ON" ;
VAL_ 608 CRUISE_LAMP_S 0 "Cruise SET switch indication lamp turn OFF" 1 "Cruise SET switch indication lamp turn ON" ;
VAL_ 608 PRE_FUEL_CUT_IN 0 "Continue to fuel cut off control" 1 "Indication of fuel cut in previous to stop fuel cut off" ;
VAL_ 608 ENG_STAT 0 "Engine Stop" 1 "Cranking" 2 "Stalled" 3 "Running" 4 "Reserved" 5 "Reserved" 6 "Reserved" 7 "Fault" ;
VAL_ 608 SOAK_TIME_ERROR 0 "No Failure detected" 1 "Failure detected" ;
VAL_ 608 CF_Ems_AclAct 0 "Accelerator pedal not pressed" 1 "Accelerator pedal pressed" 2 "Reserved" 3 "Accelerator pedal position sensor failure" ;
VAL_ 900 CF_Ems_DiagFulHDEV 0 "Condition not fulfilled" 1 "Condition fulfilled" ;
VAL_ 900 CF_Ems_SwiOffIC1 0 "Switch On" 1 "Switch Off" ;
VAL_ 900 CF_Ems_SwiOffIC2 0 "Switch On" 1 "Switch Off" ;
VAL_ 900 CF_Ems_DiagReqHDEV 0 "Result not equested" 1 "Result requested" ;
VAL_ 1170 CF_Ems_BrkReq 0 "Brake control request is not active" 1 "Brake control request is active" ;
VAL_ 1170 CF_Ems_DnShftReq 0 "Downshift control request is not active" 1 "Downshift request to 1st gear" 2 "Downshift request to 2nd gear" 3 "Downshift request to 3rd gear" 4 "Downshift request to 4th gear" 5 "Downshift request to 5th gear" 6 "Downshift request to 6th gear" 7 "Downshift request to 7th gear" 8 "Downshift request to 8th gear" 9 "Reserved" 10 "Reserved" 11 "Reserved" 12 "Reserved" 13 "Reserved" 14 "Reserved" ;
VAL_ 1170 CF_Ems_RepModChk 0 "Normal state" 1 "Reprogramming condition OK" 2 "Reprogramming condition NG" 3 "Reserved" ;
VAL_ 1170 CF_Ems_AAFOpenReq 0 "None" 1 "AAF open request" ;
VAL_ 1170 DPF_LAMP_STAT 0 "DPF Lamp Off" 1 "DPF Lamp On" 2 "DPF Lamp Blinking(1Hz)/Message" 3 "Reserved(Lamp Off)" ;
VAL_ 1170 BAT_LAMP_STAT 0 "Battery Warning Lamp OFF" 1 "Battery Warning Lamp ON" ;
VAL_ 1170 CF_Ems_OPSFail 0 "Oil Pressure Warning Lamp OFF" 1 "Oil Pressure Warning Lamp ON" ;
VAL_ 1479 SCR_LEVEL_WARN_LAMP 0 "" ;
VAL_ 1479 SCR_LEVEL_WARN 0 "" ;
VAL_ 1479 SCR_SYS_ERROR_WARN 0 "" ;
VAL_ 1479 SCR_SYSTEM_WARN_LAMP 0 "Lamp Off" 1 "Lamp ON" ;
VAL_ 1479 SCR_INDUCEMENT_EXIT_COND 0 "No display" 1 "'fill up correct urea' AND No Restart In %Mileage%" 2 "¡®check the SCR system' AND No Restart In %Mileage%" ;
VAL_ 1479 SCR_UREA_LEVEL 255 "urea level sensor error" ;
VAL_ 1479 SCR_NO_REMAINING_RESTARTS 0 "No display" 255 "Error" ;
VAL_ 1479 SCR_REMAINING_DISTANCE 0 "No display" 65535 "Error" ;
VAL_ 128 PV_AV_CAN 0 "Accelerator Pedal not activated" 254 "Accelerator Pedal fully activated" 255 "Accelerator Pedal is defective (fail state) or Non-ETC system (APS is not installed)" ;
VAL_ 128 F_N_ENG 0 "No error" 1 "Engine speed sensor defective" ;
VAL_ 128 F_SUB_TQI 0 "No error" 1 "Error on Torque Measurement" ;
VAL_ 129 BRAKE_ACT 0 "Brake switch possibly pressed" 1 "Brake switch not pressed(off)" 2 "Brake switch surely pressed" 3 "Brake switch Failure" ;
VAL_ 399 CF_CdaStat 0 "CDA OFF (Solenoid Valve OFF)" 1 "Preparation for CDA operation" 2 "CDA ON (Solenoid Valve ON)" 3 "Reserved" 4 "Reserved" 5 "Reserved" 6 "Reserved" 7 "Fault in CDA operation" ;
VAL_ 399 CF_Ems_IsgStat 0 "ISG is not operating Normal engine operating without ISG" 1 "Idle stop is activated Idle is stopped by ECU during driving" 2 "Automatically started by ECU Engine is automatically started by ECU regardless driver¡¯s volition during idle stop because the condition that ISG function to be prohibited is satisfied, for example SOC is too low." 3 "ISG is prohibited Driver prohibits to activate ISG in order to avoid start lag when he met traffic jam for example." 4 "Fault is existing in ISG There is fault, which is related with ISG. So, idle stop is prohibited and engine started automatically if it is idle stop condition. But for the vehicles that use CF_EMS_ISGStat2, the condition for not-activated battery sensor can be ignored." 5 "Idle stop is inhibited by system automatically for safety and  convenient condition related with battery SOC, brake vacuum pressure etc. ISG function check for EOL." 6 "Auto start is deactivated system automatically to keep safety, Such as door open, hood open and seat belt unlock." 7 "If driver shift gear N to D range without braking to make auto starting. (Economy ISG Only)" ;
VAL_ 399 CF_Ems_OilChg 0 "OIL LEVEL LAMP Off" 1 "OIL LEVEL LAMP On" ;
VAL_ 399 CF_Ems_EtcLimpMod 0 "Engine control is available" 1 "ETC Limphome mode by ECU" ;
VAL_ 399 CF_Ems_UpTarGr 0 "Gear Shiftup Display Off" 1 "Gear Shiftup Display On" ;
VAL_ 399 CF_Ems_DownTarGr 0 "Gear Shiftdown Display Off" 1 "Gear Shiftdown Display On" ;
VAL_ 399 CF_Ems_DesCurGr 0 "No display" 1 "Gear Position 1 display" 2 "Gear Position 2 display" 3 "Gear Position 3 display" 4 "Gear Position 4 display" 5 "Gear Position 5 display" 6 "Gear Position 6 display" 7 "Gear Position 7 display" 8 "Gear Position 8 display" 9 "Gear Position 9 display" 16 "Error ID" ;
VAL_ 399 CF_Ems_SldAct 0 "Speed limiter function is not active" 1 "Speed limiter function is active" ;
VAL_ 399 CF_Ems_SldPosAct 0 "Positive action is not active" 1 "Positive action is active" ;
VAL_ 399 CF_Ems_HPresStat 0 "Fuel Tank is not in high Pressure" 1 "Fuel Tank is in high Pressure" ;
VAL_ 399 CF_Ems_IsgBuz 0 "Initial Value" 1 "Request buzzer ON" ;
VAL_ 399 CF_Ems_IdlStpFCO 0 "Not fuel consumption" 1 "Fuel consumption(=1mL)" ;
VAL_ 399 CF_Ems_ActEcoAct 0 "Active Eco Drive is not active" 1 "Active Eco Drive is active" ;
VAL_ 399 CF_Ems_EngRunNorm 0 "Engine Stop or Starting Phase" 1 "Engine Running" ;
VAL_ 399 CF_Ems_IsgStat2 0 "Default" 1 "The condition for not-activated battery sensor. (Except EOL condition.)" 2 "In Auto Start status, when rapidly accelerating before complete gear shift. (Economy ISG Only)" ;
VAL_ 1168 EPB_I_LAMP 0 "Release State (EPB/ AVH)" 1 "Apply State (EPB)" 2 "Dynamic Braking (EPB) or Driver Action Requested" ;
VAL_ 1168 EPB_F_LAMP 0 "No failure" 1 "Failure detected or in diagnosis mode" 2 "EOL configuration not done or Emergency released" 3 "Reserved" ;
VAL_ 1168 EPB_ALARM 0 "Off" 1 "Comfortable tone (Sound once)" 2 "Uncomfortable tone" 3 "Reserved" ;
VAL_ 1168 EPB_CLU 0 "Off" 1 "EPB is in maintenance mode" 2 "Driver tries to DAR but safety condition is not satisfied" 3 "EPB applies by ESC request" ;
VAL_ 1168 EPB_SWITCH 0 "Neutral position" 1 "Apply position (pull)" 2 "Release position (push)" 3 "Switch failure" ;
VAL_ 1168 EPB_RBL 0 "No request" 1 "Request to turn on rear brake lights" ;
VAL_ 1168 EPB_STATUS 0 "See details in EPB_FRC_ERR" 1 "Released" 2 "Clamped" 3 "Clamping in progress without switch" 4 "Releasing in progress without switch" 5 "Dynamic braking via EPB" 6 "Releasing in progress by switch" 7 "Clamping in progress by switch" ;
VAL_ 1168 EPB_FRC_ERR 0 "No failure" 1 "Clamp position not reached" 2 "Emergency release" 3 "Force not measurable (e.g. sensor failure)" ;
VAL_ 1168 EPB_DBF_STAT 0 "EPB_DBF_REQ signal is valid" 1 "EPB_DBF_REQ signal is invalid" ;
VAL_ 1168 ESP_ACK 0 "Idle / No acknowledge" 1 "Acknowledge for external ESC request" ;
VAL_ 1168 EPB_DBF_REQ 0 "No Request" 1 "Dynamic braking request" ;
VAL_ 1168 EPB_FAIL 0 "Not valid" 1 "EPB No failure" 2 "EPB Initialization State" 3 "EPB Diagnostic" 4 "EPB Temporarily Not Available" 5 "EPB Permanently Not Available" ;
VAL_ 1168 EPB_FORCE 0 "EPB Fully released" ;
VAL_ 1984 CCW 3 "Request calibration and acceptance of SAS_CID" 5 "Reset SAS_CAL flag" ;
VAL_ 1151 AVH_STAT 0 "No apply" 1 "Vehicle is held by the service brake" 2 "Being released" 3 "Reserved" ;
VAL_ 1151 LDM_STAT 0 "ESC ready to DBF/AVH (requested by switch)" 1 "ESC can¡¯t perform DBF/AVH (requested by switch)" ;
VAL_ 1151 REQ_EPB_ACT 0 "No request" 1 "Release request" 2 "Close request in comfort mode" 3 "Close request in secure mode" ;
VAL_ 1151 REQ_EPB_STAT 0 "REQ_EPB_ACT signal is valid" 1 "REQ_EPB_ACT signal is invalid" ;
VAL_ 1151 ECD_ACT 0 "ECD is not active" 1 "ECD is active(operating)" ;
VAL_ 1151 _4WD_LIM_REQ 0 "No request from ESC" 1 "Request duty limit from ESC" ;
VAL_ 1151 _4WD_OPEN 0 "Passive" 1 "Clutch off" 2 "Torque limit" 3 "Error" ;
VAL_ 1151 _4WD_LIM_MODE 0 "Maximum limitation mode" 1 "Minimum limitation mode" ;
VAL_ 915 SA_Z_FLAG 0 "No zero point detection" 1 "Zero point detection" ;
VAL_ 916 BrakeLight 0 "No request" 1 "Activate brake lights" ;
VAL_ 916 DCEnable 0 "Disable deceleration control" 1 "Enable deceleration control" ;
VAL_ 916 ACCReqLim 0 "No request" 1 "Limited No Limitation" 2 "Acceleration Limited" 3 "Deceleration Limited" ;
VAL_ 916 ACCEnable 0 "SCC enabled" 1 "SCC disabled reversible" 2 "SCC disabled irreversible" 3 "SCC disabled irreversible due to communication error" ;
VAL_ 916 DriverOverride 0 "No override" 1 "Override by acceleration pedal" 2 "Override by deceleration" 3 "Not defined" ;
VAL_ 916 StandStill 0 "No stand still detected" 1 "stand still detected" ;
VAL_ 916 ACC_EQUIP 0 "SCC is not equipped" 1 "SCC is equipped" ;
VAL_ 916 PBRAKE_ACT 0 "Parking brake is not activated" 1 "Parking brake is activated" ;
VAL_ 916 ACC_REQ 0 "No request" 1 "Enable SCC torque request" ;
VAL_ 916 DriverBraking 0 "Brake pedal not pressed" 1 "Brake pedal pressed" ;
VAL_ 916 CF_VSM_Coded 0 "Not coded" 1 "Coded" ;
VAL_ 916 CF_VSM_Avail 0 "Not available" 1 "Available" 2 "Temporarily not available" 3 "Permanently not available" ;
VAL_ 916 CF_VSM_Handshake 0 "Not okay" 1 "Okay" ;
VAL_ 916 CF_DriBkeStat 0 "Driver is not braking / failure" 1 "Driver is braking" ;
VAL_ 916 CF_VSM_ConfSwi 0 "Switch Not Pressed" 1 "Switch Pressed" 2 "Reserved" 3 "Error Identifier (switch failure detected by ESC or CAN communication failure)" ;
VAL_ 916 AEB_EQUIP 0 "AEB is not equipped" 1 "AEB is equipped" ;
VAL_ 356 CF_Esc_Act 0 "VSM control inactive0H" 1 "VSM control active" ;
VAL_ 356 CF_Esc_CtrMode 0 "Inactive" 1 "Mode 1 (sensor value overlay mode)" 2 "Mode 2 (output torque overlay mode)" 3 "Mode 3 (Particular control)" ;
VAL_ 356 CF_Esc_Def 0 "VSM is not defective" 1 "VSM is defective" ;
VAL_ 1414 CF_Evp_Stat 0 "EVP is no defective" 1 "EVP is defective" ;
VAL_ 1365 CF_Fpcm_LPPumpOverCur 0 "Normal Operation" 1 "LP Pump Over Current" ;
VAL_ 1365 CF_Fpcm_PreSnrHi 0 "Normal Operation" 1 "LP Fuel Pump Pressure is too High" ;
VAL_ 1365 CF_Fpcm_PreSnrDisc 0 "Normal Operation" 1 "Pressure Sensor Disconnect Error" ;
VAL_ 1365 CF_Fpcm_PreSnrShort 0 "Normal Operation" 1 "Pressure Sensor Short Error" ;
VAL_ 1365 CF_Fpcm_LPPumpDiscShort 0 "Normal Operation" 1 "LP Fuel Pump Disconnect or Short Error" ;
VAL_ 1365 CF_Fpcm_LP_System_Error 0 "Normal Operation" 1 "System Error for Low PressureSystem" ;
VAL_ 1365 CF_Fpcm_PreSnrSigErr 0 "Normal Operation" 1 "LP Fuel Pump Sensor Signal Vibration" ;
VAL_ 1365 CF_Fpcm_LPCtrCirFlt 0 "Normal Operation" 1 "LP Fuel Pump Controller Circuit Error" ;
VAL_ 1378 CF_Hud_HeightStaus 0 "Step 1" 1 "Step 2" 2 "Step 3" 3 "Step 4" 4 "Step 5" 5 "Step 6" 6 "Step 7" 7 "Step 8" 8 "Step 9" 9 "Step 10" 10 "Step 11" 11 "Step 12" 12 "Step 13" 13 "Step 14" 14 "Step 15" 15 "Step 16" 16 "Step 17" 17 "St" ;
VAL_ 1378 CF_Hud_PBackStatus 0 "Stop" 1 "Play 1" 2 "Play 2" 3 "Invalid" ;
VAL_ 1378 CF_Hud_Brightness 0 "Step 10x01" 16 "Step 17" 17 "Step 18" 18 "Step 19" 19 "Step 20" ;
VAL_ 1415 CF_Tmu_VehSld 0 "Vehicle Slow Down Off" 1 "Vehicle Slow Down On" ;
VAL_ 1415 CF_Tmu_VehImmo 0 "Vehicle Immobilization Off" 1 "Vehicle Immobilization On" ;
VAL_ 1415 CF_Tmu_ReqRepCnd 0 "Normal state" 1 "Reprogramming request" 2 "Reprogramming complete" 3 "Reserved" ;
VAL_ 1415 CF_Tmu_AirconCtr 0 "Deactivate air conditioner automatic control" 1 "Activate air conditioner automatic control" ;
VAL_ 1415 CF_Tmu_TempMd 0 "Centigrade Mode" 1 "Fahrenheit Mode" ;
VAL_ 1415 CF_Tmu_TempSet 0 "Blank" 1 "Display" 16 "24¡É/76¢µ" 17 "24.5¡É/77¢µ" 18 "25¡É/78¢µ" 19 "25.5¡É/79¢µ" 20 "26¡É/80¢µ" 21 "26.5¡É/81¢µ" 22 "27¡É/82¢µ" 23 "27.5¡É/83¢µ" 24 "28¡É/84¢µ" 25 "28.5¡É/85¢µ" 26 "29¡É/86¢µ" 27 "29.5¡É/87¢µ" 28 "30¡É/88¢µ" 29 "30.5¡É/89¢µ" 30 "31¡É/High" 31 "31.5¡É" 2 "Low" 32 "High" 3 "17.5¡É/63¢µ" 4 "18¡É/64¢µ" 5 "18.5¡É/65¢µ" 6 "19¡É/66¢µ" 7 "19.5¡É/67¢µ" 8 "20¡É/68¢µ" 9 "20.5¡É/69¢µ" 10 "21¡É/70¢µ" 11 "21.5¡É/71¢µ" 12 "22¡É/72¢µ" 13 "22.5¡É/73¢µ" 14 "23¡É/74¢µ" 15 "23.5¡É/75¢µ" ;
VAL_ 1415 CF_Tmu_DefrostCtr 0 "Deactivate defrost mode" 1 "Activate defrost mode" ;
VAL_ 1419 CF_Lca_Stat 0 "System is Off" 1 "System Passive" 2 "System Active" 3 "System Failure" 4 "System Blockage" 5 "System Overtemperature" 6 "System minor failure" ;
VAL_ 1419 CF_Rcta_Stat 0 "RCTA is Off" 1 "RCTA Passive" 2 "RCTA Active" 3 "RCTA Failure" 4 "RCTA Blockage" 5 "RCTA Overtemperature" 6 "RCTA Minor Failure" ;
VAL_ 1419 CF_Lca_IndLeft 0 "Indicator output off" 1 "Indicator on (information)" 2 "Indicator blinking(warning)" 3 "Indicator output check" ;
VAL_ 1419 CF_Rcw_Stat 0 "RCW is Off" 1 "RCW Passive" 2 "RCW Active" 3 "RCW Failure" 4 "RCW Blockage" 5 "RCW Overtemperature" 6 "RCW Minor Failure" ;
VAL_ 1419 CF_RCW_Warning 0 "Warning is Off" 1 "Warning On" ;
VAL_ 1419 CF_Lca_IndRight 0 "Indicator output off" 1 "Indicator on (information)" 2 "Indicator blinking(warning)" 3 "Indicator output check" ;
VAL_ 1419 CF_Lca_SndWan_Stat 0 "LCA sound is Off" 1 "LCA sound is On" 2 "failure" 3 "reserved" ;
VAL_ 1419 CF_FR_SndWan 0 "Speaker is Off" 1 "Speaker On" ;
VAL_ 1419 CF_FL_SndWan 0 "Speaker is Off" 1 "Speaker On" ;
VAL_ 1419 CF_RR_SndWan 0 "Speaker is Off" 1 "Speaker On" ;
VAL_ 1419 CF_RL_SndWan 0 "Speaker is Off" 1 "Speaker On" ;
VAL_ 1419 CF_RCTA_IndLeft 0 "Warning is Off" 1 "Warning On" ;
VAL_ 1419 CF_RCTA_IndRight 0 "Warning is Off" 1 "Warning On" ;
VAL_ 1419 CF_SndWarnForClu 0 "OFF" 1 "Warning Sound is On" ;
VAL_ 625 LV_FUEL_TYPE_BOX 0 "Gasoline" 1 "Gas" ;
VAL_ 625 LV_BFS_IN_PROGRESS 0 "No progress" 1 "Progress" ;
VAL_ 625 LV_GAS_OK 0 "Gas system is not OK" 1 "Gas system is OK" ;
VAL_ 625 LV_FUP_ENA_THD 0 "The pressure is too low to start engine" 1 "The pressure is enough high to start engine" ;
VAL_ 625 LV_PRE_CDN_LEAK 0 "Not Active" 1 "Active" ;
VAL_ 625 LV_CONF_INJECTION_DELAY 0 "Not Active" 1 "Active" ;
VAL_ 625 LV_LPG_SW_DRIVER_REQ 0 "LPG Switch Not Pressed" 1 "LPG Switch Pressed" ;
VAL_ 852 CF_Lvr_GearInf 0 "Gear lever position P" 5 "Gear lever position D" 6 "Gear lever position N" 7 "Gear lever position R" 8 "Gear lever position in Sport mode/ Manual mode" 9 "Initial value" 15 "Fault" ;
VAL_ 852 CF_Lvr_PRelStat 0 "Parking Not Released" 1 "Parking Released" ;
VAL_ 852 CF_Lvr_BkeAct 0 "Brake Pedal BLS Switch is not activated" 1 "Brake Pedal BLS Switch is activated" ;
VAL_ 852 CF_Lvr_NFnStat 0 "N Park function is not activated" 1 "N Park function is activated" ;
VAL_ 852 CF_Lvr_PosInf 0 "Initial value" 1 "Gear lever position P" 2 "Intermediate position P-R" 3 "Gear lever position R" 4 "Intermediate position R-N" 5 "Gear lever position N" 6 "Intermediate position N-D" 7 "Gear lever position D" 8 "Nr" 9 "Nd" 10 "Gear lever position M (Ds)" 11 "Gear lever position ¡°M+¡±" 12 "Gear lever position ¡°M -¡±" 15 "Fault" ;
VAL_ 852 CF_Lvr_UlkButStat 0 "Not supported" 1 "Safety Button Off" 2 "Safety Button On" 3 "Fault" ;
VAL_ 852 CF_Lvr_PNStat 0 "Initial Value" 1 "Park Status" 2 "Not Park Status" 3 "-" ;
VAL_ 897 CF_Mdps_WLmp 0 "MDPS Malfunction Warning lamp OFF" 1 "MDPS Malfunciton Warning lamp BLANKING(2Hz)" 2 "MDPS Malfunction Warning lamp ON" 3 "MDPS Malfunction Warning lamp BLANKING(1Hz)" ;
VAL_ 897 CF_Mdps_Flex 0 "Standard Mode" 1 "Sport Mode" 2 "Comport Mode" 3 "Reserved" ;
VAL_ 897 CF_Mdps_FlexDisp 0 "No Display" 1 "Display" ;
VAL_ 897 CF_Mdps_Stat 0 "Reserved" 1 "Steering still in initialization phase" 2 "Steering ready, waits for SPAS command" 3 "Steering set in standby by SPAS" 4 "Steering requested to go to first activation step" 5 "Steering requested to go to final activation step" 6 "Steering went to error internally" 7 "Steering aborted the automatic function" 15 "Not Available" ;
VAL_ 897 CF_Mdps_ALTRequest 0 "Current consumption is low" 1 "Current consumption is high" ;
VAL_ 897 CF_Mdps_SPAS_FUNC 0 "The SPAS function of MDPS is not plugged in (unplugged)." 1 "The SPAS function of MDPS is plugged in." ;
VAL_ 897 CF_Mdps_LKAS_FUNC 0 "The LKAS function of MDPS is not plugged in (unplugged)." 1 "The LKAS function of MDPS is plugged in." ;
VAL_ 897 CF_Mdps_CurrMode 0 "Standard Mode" 1 "Sport Mode" 2 "Comfort Mode" 3 "Reserved" ;
VAL_ 897 CF_Mdps_Type 0 "C-MDPS" 1 "R-MDPS(Dual Pinion)" 2 "R-MDPS(Belt)" 3 "Reserved" ;
VAL_ 1530 CF_Ods_PrcCmd 0 "No command in process" 1 "Command in process" ;
VAL_ 1530 CF_Ods_BtsFail 0 "No Belt Tension Sensor Fault exists" 1 "Belt Tension Sensor Fault exists" ;
VAL_ 1530 CF_Ods_AcuRcvSN 0 "ACU Serial Number not received" 1 "ACU Serial Number Received" ;
VAL_ 1530 CF_Ods_EolCal 0 "No re-zero request" 1 "Request to re-zero the empty seat offset" ;
VAL_ 1530 CF_Ods_PsFail 0 "No Pressue Sensor Fault exists" 1 "Pressure Sensor Fault exists" ;
VAL_ 1530 CF_Ods_EcuFail 0 "No ECU Fault exists" 1 "ECU Fault exists" ;
VAL_ 1530 CF_Ods_WgtStat 0 "Occupant below ¡°allow¡± threshold" 1 "Occupant above ¡°allow¡± threshold" ;
VAL_ 1530 CF_Ods_OccStat 0 "Seat not occupied" 1 "Seat Occupied" ;
VAL_ 1530 CR_Wcs_ClassStat 0 "Empty (Class0)" 1 "Child (Class1)" 2 "Adult (Class2)" 4 "Indeterminate" ;
VAL_ 1393 CF_Opi_Over_Temp 0 "No Failure Detected" 1 "Failure Detected" ;
VAL_ 1393 CF_Opi_Over_Cur 0 "No failure Detected" 1 "Failure Detected" ;
VAL_ 1393 CF_Opi_Over_Vol 0 "No Failure Detected" 1 "Failure Detected" ;
VAL_ 1393 CF_Opi_Hall_Fail 0 "No Failure Detected" 1 "Failure Detected" ;
VAL_ 1393 CF_Opi_Flt 0 "No Failure Detected" 1 "Failure Detected" ;
VAL_ 1393 CF_Opi_Motor_Dir 0 "Clock Wise(CW)" 1 "Counter Clock Wise(CCW)" ;
VAL_ 1379 PGS_State 0 "Off" 1 "Fr Cam View" 2 "Rr Normal View with Menu" 4 "Garage Parking" 7 "Parallel Parking" 8 "Rr Top View with Menu" 10 "Setting View" 11 "Rr Cam View without Menu" 15 "Invalid" ;
VAL_ 1379 PGS_ParkGuideState 0 "Off" 1 "Garage_Parallel Step1" 3 "Garage_Parallel Step 2" 6 "Parallel Step 3" 15 "abnormal stopping(speed)" 31 "Invalid" ;
VAL_ 1379 PGS_Option 31 "Invalid" ;
VAL_ 1379 PGS_Version 0 "None" 65535 "Invalid" ;
VAL_ 1434 PSB_LH_FAIL 0 "No failure" 1 "Failure/Service Required" 2 "Defect, PSB warning light off" 3 "Signal not valid" ;
VAL_ 1434 PSB_LH_ACT 0 "No PSB motor activation" 1 "PSB retract cycle active" 2 "Reserved" 3 "Reserved" ;
VAL_ 1434 PSB_RH_FAIL 0 "No failure" 1 "Failure/Service Required" 2 "Defect, PSB warning light off" 3 "Signal not valid" ;
VAL_ 1434 PSB_RH_ACT 0 "No PSB motor activation" 1 "PSB retract cycle active" 2 "Reserved" 3 "Reserved" ;
VAL_ 387 CF_EndBst_PwmDuH 0 "No Error" 1 "Error" ;
VAL_ 387 CF_EndBst_PwmDuL 0 "No Error" 1 "Error" ;
VAL_ 387 CF_EndBst_PwmFqOutRng 0 "No Error" 1 "Error" ;
VAL_ 387 CF_EndBst_HbriOverCur 0 "No Error" 1 "Error" ;
VAL_ 387 CF_EndBst_HbriOverTemp 0 "No Error" 1 "Error" ;
VAL_ 387 CF_EndBst_PosSnsKOR 0 "No Error" 1 "Error" ;
VAL_ 387 CF_EndBst_PosSnsOSOR 0 "No Error" 1 "Error" ;
VAL_ 387 CF_EndBst_EepFlt 0 "No Error" 1 "Error" ;
VAL_ 387 CF_EndBst_RomFlt 0 "No Error" 1 "Error" ;
VAL_ 387 CF_EndBst_RamFlt 0 "No Error" 1 "Error" ;
VAL_ 387 CF_EndBst_CanFlt 0 "No Error" 1 "Error" ;
VAL_ 387 CF_EndBst_AgH 0 "No Error" 1 "Error" ;
VAL_ 387 CF_EndBst_AgL 0 "No Error" 1 "Error" ;
VAL_ 387 CF_EndBst_ORVol 0 "No Error" 1 "Error" ;
VAL_ 912 CF_Spas_Stat 0 "Reserved" 1 "SPAS_Init" 2 "SPAS_NewStart" 3 "SPAS_Standby" 4 "SPAS_Active" 5 "SPAS_Angle_Control_Active" 6 "SPAS_Failure" 7 "SPAS_Abort" ;
VAL_ 912 CF_Spas_TestMode 0 "SPAS is not in Test Mode" 1 "SPAS is in Test Mode" ;
VAL_ 912 CF_Spas_BeepAlarm 0 "No warning alarm" 1 "SPAS or PAS Failure State warning alarm" 3 "Change to TGS ¡°R¡± warning alarm" 4 "SPAS parking complete warning alarm" 7 "¡°Stop¡± message during SPAS function warning alarm" 8 "¡°Scan complete¡± message warning" 9 "¡°System abort¡± message during SPAS driving warning alarm" 10 "¡°Gear Shift to Backward¡± warning alarm" 11 "¡°Gear Shift to Forward¡± warning alarm" 12 "SPAS parking out complete warning alarm" ;
VAL_ 912 CF_Spas_Mode_Seq 0 "Default" 1 "Domestic" 2 "EU LHD" 3 "EU RHD" ;
VAL_ 912 CF_Spas_PasVol 0 "Default" 1 "Level 1" 2 "Level 2" 3 "Level 3" 7 "Invalild (Error Value)" ;
VAL_ 1268 CF_Spas_HMI_Stat 0 "No Display" 1 "Parking mode selection - right perpendicular" 2 "Parking mode selection - left perpendicular" 3 "Parking mode selection - right parallel" 4 "Parking mode selection - left parallel" 5 "Parking mode selection - OFF" 6 "Requesting go forward for detecting parking space" 7 "Detecting parking space - right perpendicular" 8 "Detecting parking space - left perpendicular" 9 "Detecting parking space - right parallel" 10 "Detecting parking space - left parallel" 13 "Requesting stop of vehicle in perpendicular parking" 14 "Requesting Steering Wheel to left side in right perpendicular parking" 15 "Requesting Steering Wheel to right side in left perpendicular parking" 17 "Finishing parking space - right perpendicular" 18 "Finishing parking space - left perpendicular" 19 "Finishing parking space - right parallel" 20 "Finishing parking space - left parallel" 23 "Automatic steering activation" 25 "Requesting gear shift to forward during automatic steering activation" 26 "Requesting gear shift to backward during automatic steering activation" 28 "Finishing automatic steering activation" 30 "System auto-canceled" 31 "System failed" 32 "Over speed of vehicle" 33 "Requesting EPB AUTO-HOLD OFF" 34 "System deactivation by TRAILER MODE" 35 "System deactivation by TCS OFF" 37 "Parking out mode selection - OFF" 38 "Parking out mode selection - left" 39 "Parking out mode selection - right" 40 "Detecting parking out space - left" 41 "Detecting parking out space - right" 42 "Requesting gear shift to backward in parking out mode after detecting parking out space" 44 "Automatic steering activation for parking out" 46 "Requesting gear shift to forward in parking out mode" 47 "Requesting gear shift to backward in parking out mode" 49 "Finishing automatic steering activation for parking out" 50 "System auto-canceled in parking out mode" 51 "Informing parking space - right perpendicular" 52 "Informing parking space - left perpendicular" 53 "Informing parking space - right parallel" 54 "Informing parking space - left parallel" ;
VAL_ 1268 CF_Spas_Disp 0 "No display" 1 "PAS display" 2 "SPAS display" 3 "SPAS displaly" ;
VAL_ 1268 CF_Spas_FIL_Ind 0 "OFF (No warning)" 1 "1¡¯st warning level" 2 "2¡¯nd warning level" 3 "3¡¯nd warning level (the closest status with obstacle)" 7 "Malfunction (sensor fail)" ;
VAL_ 1268 CF_Spas_FIR_Ind 0 "OFF (No warning)" 1 "1¡¯st warning level" 2 "2¡¯nd warning level" 3 "3¡¯nd warning level (the closest status with obstacle)" 7 "Malfunction (sensor fail)" ;
VAL_ 1268 CF_Spas_FOL_Ind 0 "OFF (No warning)" 1 "1¡¯st warning level" 2 "2¡¯nd warning level" 3 "3¡¯nd warning level (the closest status with obstacle)" 7 "Malfunction (sensor fail)" ;
VAL_ 1268 CF_Spas_FOR_Ind 0 "OFF (No warning)" 1 "1¡¯st warning level" 2 "2¡¯nd warning level" 3 "3¡¯nd warning level (the closest status with obstacle)" 7 "Malfunction (sensor fail)" ;
VAL_ 1268 CF_Spas_VolDown 0 "OFF (deactivation of warning alarm)" 1 "ON (activation of warning alarm)" 2 "Reserved" 3 "Not supported" ;
VAL_ 1268 CF_Spas_RIL_Ind 0 "OFF (No warning)" 1 "1¡¯st warning level" 2 "2¡¯nd warning level" 3 "3¡¯nd warning level (the closest status with obstacle)" 7 "Malfunction (sensor fail)" ;
VAL_ 1268 CF_Spas_RIR_Ind 0 "OFF (No warning)" 1 "1¡¯st warning level" 2 "2¡¯nd warning level" 3 "3¡¯nd warning level (the closest status with obstacle)" 7 "Malfunction (sensor fail)" ;
VAL_ 1268 CF_Spas_FLS_Alarm 0 "OFF(No warning alarm)" 1 "1¡¯st warning alarm level" 2 "2¡¯nd warning alarm level" 3 "3¡¯nd warning alarm level (the closest status with obstacle)" ;
VAL_ 1268 CF_Spas_ROL_Ind 0 "OFF (No warning)" 1 "1¡¯st warning level" 2 "2¡¯nd warning level" 3 "3¡¯nd warning level (the closest status with obstacle)" 7 "Malfunction (sensor fail)" ;
VAL_ 1268 CF_Spas_ROR_Ind 0 "OFF (No warning)" 1 "1¡¯st warning level" 2 "2¡¯nd warning level" 3 "3¡¯nd warning level (the closest status with obstacle)" 7 "Malfunction (sensor fail)" ;
VAL_ 1268 CF_Spas_FCS_Alarm 0 "OFF(No warning alarm)" 1 "1¡¯st warning alarm level" 2 "2¡¯nd warning alarm level" 3 "3¡¯nd warning alarm level (the closest status with obstacle)" ;
VAL_ 1268 CF_Spas_FI_Ind 0 "OFF (No warning)" 1 "1¡¯st warning level" 2 "2¡¯nd warning level" 3 "3¡¯nd warning level (the closest status with obstacle)" 7 "Malfunction (sensor fail)" ;
VAL_ 1268 CF_Spas_RI_Ind 0 "OFF (No warning)" 1 "1¡¯st warning level" 2 "2¡¯nd warning level" 3 "3¡¯nd warning level (the closest status with obstacle)" 7 "Malfunction (sensor fail)" ;
VAL_ 1268 CF_Spas_FRS_Alarm 0 "OFF(No warning alarm)" 1 "1¡¯st warning alarm level" 2 "2¡¯nd warning alarm level" 3 "3¡¯nd warning alarm level (the closest status with obstacle)" ;
VAL_ 1268 CF_Spas_FR_Alarm 0 "OFF(No warning alarm)" 1 "¡¯st warning alarm level" 2 "2¡¯nd warning alarm level" 3 "3¡¯nd warning alarm level (the closest status with obstacle)" ;
VAL_ 1268 CF_Spas_RR_Alarm 0 "OFF(No warning alarm)" 1 "1¡¯st warning alarm level" 2 "2¡¯nd warning alarm level" 3 "3¡¯nd warning alarm level (the closest status with obstacle)" ;
VAL_ 1268 CF_Spas_BEEP_Alarm 0 "No warning alarm" 1 "SPAS or PAS Failure State warning alarm" 3 "Change to TGS ¡°R¡± warning alarm" 4 "SPAS parking complete warning alarm" 7 "¡°Stop¡± message during SPAS function warning alarm" 8 "¡°Scan complete¡± message warning" 9 "¡°System abort¡± message during SPAS driving warning alarm" 10 "¡°Gear Shift to Backward¡± warning alarm" 11 "¡°Gear Shift to Forward¡± warning alarm" 12 "SPAS parking out complete warning alarm" ;
VAL_ 1268 CF_Spas_StatAlarm 0 "SPAS&PAS Function Alarm OFF" 1 "SPAS&PAS Function Alarm ON" ;
VAL_ 1268 CF_Spas_RLS_Alarm 0 "OFF(No warning alarm)" 1 "1¡¯st warning alarm level" 2 "2¡¯nd warning alarm level" 3 "3¡¯nd warning alarm level (the closest status with obstacle)" ;
VAL_ 1268 CF_Spas_RCS_Alarm 0 "OFF(No warning alarm)" 1 "1¡¯st warning alarm level" 2 "2¡¯nd warning alarm level" 3 "3¡¯nd warning alarm level (the closest status with obstacle)" ;
VAL_ 1268 CF_Spas_RRS_Alarm 0 "OFF(No warning alarm)" 1 "1¡¯st warning alarm level" 2 "2¡¯nd warning alarm level" 3 "3¡¯nd warning alarm level (the closest status with obstacle)" ;
VAL_ 1427 POS_FL_W_LAMP 0 "FL POSITION Warning lamp OFF" 1 "FL POSITION Warning lamp ON" ;
VAL_ 1427 POS_FR_W_LAMP 0 "FR POSITION Warning lamp OFF" 1 "FR POSITION Warning lamp ON" ;
VAL_ 1427 POS_RL_W_LAMP 0 "RL POSITION Warning lamp OFF" 1 "RL POSITION Warning lamp ON" ;
VAL_ 1427 POS_RR_W_LAMP 0 "RR POSITION Warning lamp OFF" 1 "RR POSITION Warning lamp ON" ;
VAL_ 1427 STATUS_TPMS 0 "inactive" 1 "active" 2 "reserved" 3 "reserved" 4 "reserved" 5 "reserved" 6 "reserved" 7 "reserved" ;
VAL_ 1427 UNIT 0 "psi" 1 "kpa" 2 "bar" 3 "reserved" ;
